VERSION ""

NS_ :

BS_:

BU_: ACCL BGW BLE DBPC DCFL DCFR DCRL DCRR DDP DSM ECPM FBCM FFL FLDC FRDC HLL HLR HUD IHUB LGL PBPC PDP PSM RBCM RCLL RCLR RLDC RLDP RLSM RRDC RRDP RRSM SCAM TOOL IPC u d t

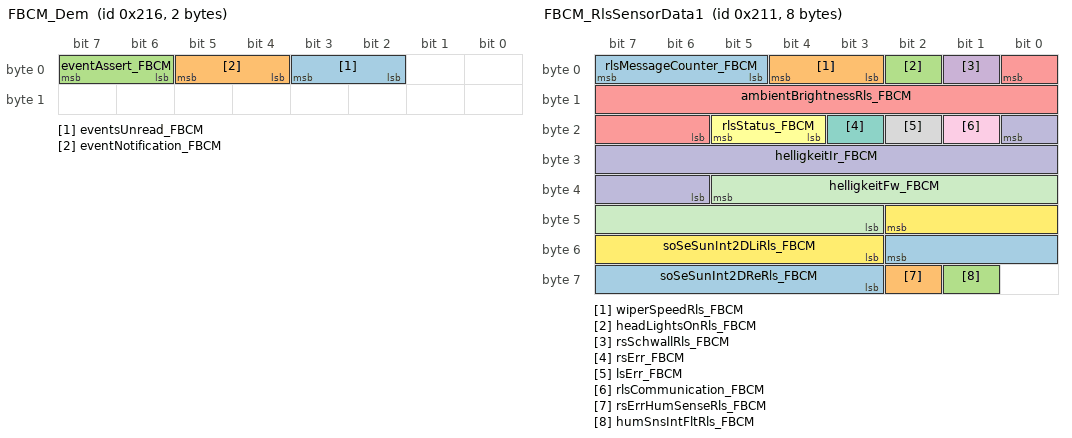
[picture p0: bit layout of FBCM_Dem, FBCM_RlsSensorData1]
BO_ 534 FBCM_Dem: 2 FBCM
 SG_ eventsUnread_FBCM : 3|2@0+ (1,0) [0|2] "" BGW,TOOL
 SG_ eventNotification_FBCM : 5|2@0+ (1,0) [0|2] "" TOOL
 SG_ eventAssert_FBCM : 7|2@0+ (1,0) [0|2] "" TOOL

BO_ 529 FBCM_RlsSensorData1: 8 FBCM
 SG_ rlsMessageCounter_FBCM : 7|3@0+ (1,0) [0|7] "" BGW
 SG_ wiperSpeedRls_FBCM : 4|2@0+ (1,0) [0|3] "" BGW
 SG_ headLightsOnRls_FBCM : 2|1@0+ (1,0) [0|1] "" BGW
 SG_ rsSchwallRls_FBCM : 1|1@0+ (1,0) [0|1] "" BGW
 SG_ ambientBrightnessRls_FBCM : 0|11@0+ (1,0) [0|2047] "" BGW
 SG_ rlsStatus_FBCM : 21|2@0+ (1,0) [0|3] "" BGW
 SG_ rsErr_FBCM : 19|1@0+ (1,0) [0|1] "" BGW
 SG_ lsErr_FBCM : 18|1@0+ (1,0) [0|1] "" BGW
 SG_ rlsCommunication_FBCM : 17|1@0+ (1,0) [0|1] "" BGW
 SG_ helligkeitIr_FBCM : 16|11@0+ (1,0) [0|2047] "" BGW
 SG_ helligkeitFw_FBCM : 37|11@0+ (1,0) [0|2047] "" BGW
 SG_ soSeSunInt2DLiRls_FBCM : 42|8@0+ (1,0) [0|255] "" BGW
 SG_ soSeSunInt2DReRls_FBCM : 50|8@0+ (1,0) [0|255] "" BGW
 SG_ rsErrHumSenseRls_FBCM : 58|1@0+ (1,0) [0|1] "" BGW
 SG_ humSnsIntFltRls_FBCM : 57|1@0+ (1,0) [0|1] "" BGW

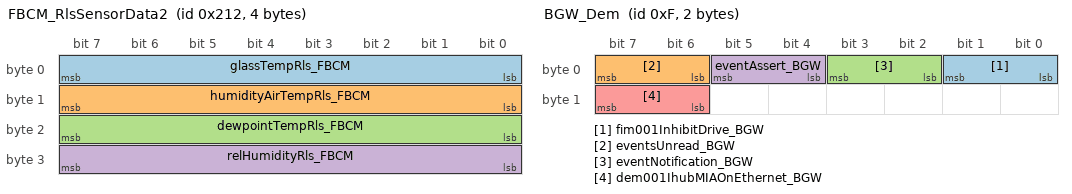
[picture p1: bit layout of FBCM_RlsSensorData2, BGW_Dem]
BO_ 530 FBCM_RlsSensorData2: 4 FBCM
 SG_ glassTempRls_FBCM : 7|8@0+ (1,0) [0|255] "" BGW
 SG_ humidityAirTempRls_FBCM : 15|8@0+ (1,0) [0|255] "" BGW
 SG_ dewpointTempRls_FBCM : 23|8@0+ (1,0) [0|255] "" BGW
 SG_ relHumidityRls_FBCM : 31|8@0+ (1,0) [0|255] "" BGW

BO_ 716 DCRR_IMU: 4 DCRR
 SG_ imuRollAngle_DCRR : 23|14@0- (0.022,0) [-180|180] "" BGW
 SG_ imuPitchAngle_DCRR : 7|14@0- (0.022,0) [-180|180] "" BGW

BO_ 684 DCRL_IMU: 4 DCRL
 SG_ imuRollAngle_DCRL : 23|14@0- (0.022,0) [-180|180] "" BGW
 SG_ imuPitchAngle_DCRL : 7|14@0- (0.022,0) [-180|180] "" BGW

BO_ 652 DCFR_IMU: 4 DCFR
 SG_ imuRollAngle_DCFR : 23|14@0- (0.022,0) [-180|180] "" BGW
 SG_ imuPitchAngle_DCFR : 7|14@0- (0.022,0) [-180|180] "" BGW

BO_ 612 DCFL_IMU: 4 DCFL
 SG_ imuRollAngle_DCFL : 23|14@0- (0.022,0) [-180|180] "" BGW
 SG_ imuPitchAngle_DCFL : 7|14@0- (0.022,0) [-180|180] "" BGW

BO_ 14 BGW_VehicleIdNumber: 8 BGW
 SG_ v : NaN|NaN@0+ (NaN,NaN) [NaN|NaN] "N" u

BO_ 15 BGW_Dem: 2 BGW
 SG_ fim001InhibitDrive_BGW : 1|2@0+ (1,0) [0|2] "" TOOL
 SG_ eventsUnread_BGW : 7|2@0+ (1,0) [0|2] "" TOOL
 SG_ eventNotification_BGW : 3|2@0+ (1,0) [0|2] "" TOOL
 SG_ eventAssert_BGW : 5|2@0+ (1,0) [0|2] "" TOOL
 SG_ dem001IhubMIAOnEthernet_BGW : 15|2@0+ (1,0) [0|2] "" TOOL

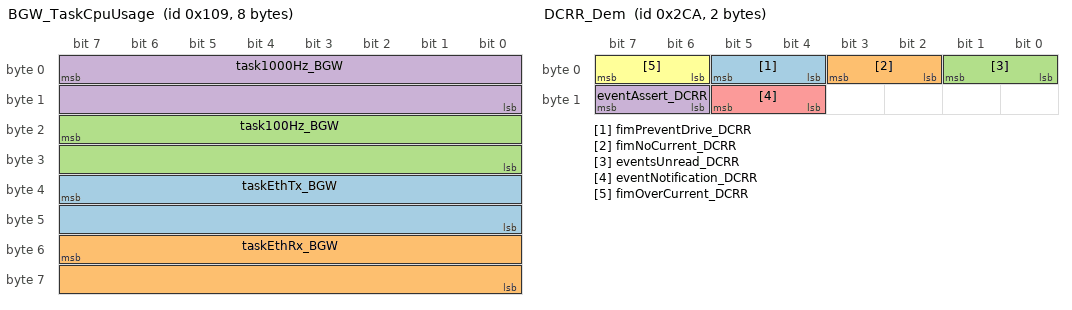
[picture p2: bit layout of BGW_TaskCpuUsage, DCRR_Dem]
BO_ 265 BGW_TaskCpuUsage: 8 BGW
 SG_ taskEthTx_BGW : 39|16@0+ (0.01,0) [0|100] "%" TOOL
 SG_ taskEthRx_BGW : 55|16@0+ (0.01,0) [0|100] "%" TOOL
 SG_ task100Hz_BGW : 23|16@0+ (0.01,0) [0|100] "%" TOOL
 SG_ task1000Hz_BGW : 7|16@0+ (0.01,0) [0|100] "%" TOOL

BO_ 269 BGW_InfoFromIHUB4: 8 BGW
 SG_ chargePortDoorOpenReq_IHUB : 61|2@0+ (1,0) [0|2] "" FBCM
 SG_ doorPassengerWindowLock_IHUB : 47|2@0+ (1,0) [0|2] "" DCRR,DCRL,DCFR,DCFL
 SG_ doorPanelRsdDisableRR_IHUB : 35|2@0+ (1,0) [0|2] "" RRDP
 SG_ doorPanelRsdDisableRL_IHUB : 37|2@0+ (1,0) [0|2] "" RLDP
 SG_ nAirConditionAutoRR_IHUB : 39|2@0+ (1,0) [0|2] "" RRDP
 SG_ nAirConditionAutoRL_IHUB : 41|2@0+ (1,0) [0|2] "" RLDP
 SG_ nAirConditionAutoFR_IHUB : 43|2@0+ (1,0) [0|2] "" PDP
 SG_ nAirConditionAutoFL_IHUB : 45|2@0+ (1,0) [0|2] "" DDP
 SG_ seatMemoryRR_IHUB : 27|2@0+ (1,0) [0|2] "" RRDP
 SG_ seatMemoryRL_IHUB : 29|2@0+ (1,0) [0|2] "" RLDP
 SG_ seatMemoryFL_IHUB : 31|2@0+ (1,0) [0|2] "" DDP
 SG_ seatMemoryFR_IHUB : 33|2@0+ (1,0) [0|2] "" PDP
 SG_ screenDisplayTempUnitsRRDP_IHUB : 25|2@0+ (1,0) [0|2] "" RRDP
 SG_ screenDisplayTempUnitsRLDP_IHUB : 17|2@0+ (1,0) [0|2] "" RLDP
 SG_ screenDisplayTempUnitsPDP_IHUB : 9|2@0+ (1,0) [0|2] "" PDP
 SG_ screenDisplayTempUnitsDDP_IHUB : 1|2@0+ (1,0) [0|2] "" DDP
 SG_ personalAssistantCmdRR_IHUB : 20|3@0+ (1,0) [0|6] "" RRDP
 SG_ personalAssistantCmdRL_IHUB : 23|3@0+ (1,0) [0|6] "" RLDP
 SG_ personalAssistantCmdFR_IHUB : 12|3@0+ (1,0) [0|6] "" PDP
 SG_ personalAssistantCmdFL_IHUB : 15|3@0+ (1,0) [0|6] "" DDP
 SG_ wirelessChargePadRR_IHUB : 4|3@0+ (1,0) [0|6] "" RRDP
 SG_ wirelessChargePadRL_IHUB : 7|3@0+ (1,0) [0|6] "" RLDP
 SG_ windowReqFrontLeft_IHUB : 55|2@0+ (1,0) [0|2] "" DCFL
 SG_ windowReqFrontRight_IHUB : 53|2@0+ (1,0) [0|2] "" DCFR
 SG_ windowReqRearLeft_IHUB : 51|2@0+ (1,0) [0|2] "" DCRL
 SG_ windowReqRearRight_IHUB : 49|2@0+ (1,0) [0|2] "" DCRR
 SG_ mirrorDimmingEnableDisable_IHUB : 63|2@0+ (1,0) [0|2] "" DCFL,DCFR
 SG_ lightHazardOnReq_IHUB : 59|2@0+ (1,0) [0|2] "" FBCM
 SG_ hornOnReq_IHUB : 57|2@0+ (1,0) [0|2] "" FBCM

BO_ 714 DCRR_Dem: 2 DCRR
 SG_ fimPreventDrive_DCRR : 5|2@0+ (1,0) [0|2] "" TOOL
 SG_ fimNoCurrent_DCRR : 3|2@0+ (1,0) [0|2] "" TOOL
 SG_ eventsUnread_DCRR : 1|2@0+ (1,0) [0|2] "" BGW,TOOL
 SG_ eventAssert_DCRR : 15|2@0+ (1,0) [0|2] "" TOOL
 SG_ eventNotification_DCRR : 13|2@0+ (1,0) [0|2] "" TOOL
 SG_ fimOverCurrent_DCRR : 7|2@0+ (1,0) [0|2] "" TOOL

BO_ 270 BGW_InfoFromIHUB3: 8 BGW
 SG_ deviceStateOfChargeFR_IHUB : 0|7@0+ (1,0) [0|100] "" PDP
 SG_ deviceStateOfChargeFL_IHUB : 7|7@0+ (1,0) [0|100] "" DDP
 SG_ deviceStateOfChargeRL_IHUB : 9|7@0+ (1,0) [0|100] "" RLDP
 SG_ deviceStateOfChargeRR_IHUB : 18|7@0+ (1,0) [0|100] "" RRDP
 SG_ deviceChargingFR_IHUB : 25|2@0+ (1,0) [0|2] "" PDP
 SG_ deviceChargingFL_IHUB : 27|2@0+ (1,0) [0|2] "" DDP
 SG_ deviceChargingRL_IHUB : 33|2@0+ (1,0) [0|2] "" RLDP
 SG_ deviceChargingRR_IHUB : 41|2@0+ (1,0) [0|2] "" RRDP
 SG_ deviceSignalStrengthRL_IHUB : 36|3@0+ (1,0) [0|5] "" RLDP
 SG_ deviceSignalStrengthFR_IHUB : 39|3@0+ (1,0) [0|5] "" PDP
 SG_ deviceSignalStrengthFL_IHUB : 44|3@0+ (1,0) [0|5] "" DDP
 SG_ deviceSignalStrengthRR_IHUB : 47|3@0+ (1,0) [0|5] "" RRDP
 SG_ doorPanelDisableRR_IHUB : 49|2@0+ (1,0) [0|2] "" RRDP
 SG_ doorPanelDisableRL_IHUB : 51|2@0+ (1,0) [0|2] "" RLDP
 SG_ doorPanelDisableFR_IHUB : 53|2@0+ (1,0) [0|2] "" PDP
 SG_ doorPanelDisableFL_IHUB : 55|2@0+ (1,0) [0|2] "" DDP
 SG_ doorPanelSeatsDisableRR_IHUB : 57|2@0+ (1,0) [0|2] "" RRDP
 SG_ doorPanelSeatsDisableRL_IHUB : 59|2@0+ (1,0) [0|2] "" RLDP
 SG_ doorPanelSeatsDisableFR_IHUB : 61|2@0+ (1,0) [0|2] "" PDP
 SG_ doorPanelSeatsDisableFL_IHUB : 63|2@0+ (1,0) [0|2] "" DDP

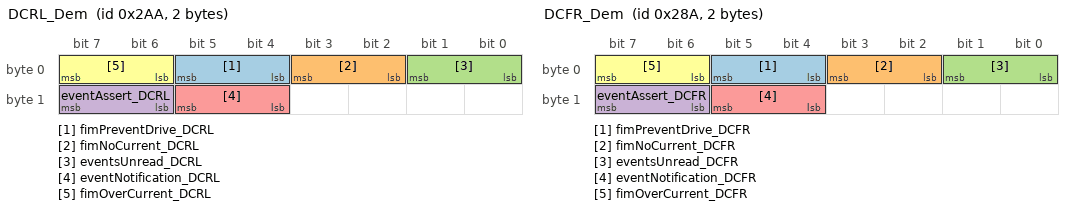
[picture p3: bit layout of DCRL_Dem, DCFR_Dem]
BO_ 682 DCRL_Dem: 2 DCRL
 SG_ fimPreventDrive_DCRL : 5|2@0+ (1,0) [0|2] "" TOOL
 SG_ fimNoCurrent_DCRL : 3|2@0+ (1,0) [0|2] "" TOOL
 SG_ eventsUnread_DCRL : 1|2@0+ (1,0) [0|2] "" BGW,TOOL
 SG_ eventAssert_DCRL : 15|2@0+ (1,0) [0|2] "" TOOL
 SG_ eventNotification_DCRL : 13|2@0+ (1,0) [0|2] "" TOOL
 SG_ fimOverCurrent_DCRL : 7|2@0+ (1,0) [0|2] "" TOOL

BO_ 650 DCFR_Dem: 2 DCFR
 SG_ fimPreventDrive_DCFR : 5|2@0+ (1,0) [0|2] "" TOOL
 SG_ fimNoCurrent_DCFR : 3|2@0+ (1,0) [0|2] "" TOOL
 SG_ eventsUnread_DCFR : 1|2@0+ (1,0) [0|2] "" BGW,TOOL
 SG_ eventAssert_DCFR : 15|2@0+ (1,0) [0|2] "" TOOL
 SG_ eventNotification_DCFR : 13|2@0+ (1,0) [0|2] "" TOOL
 SG_ fimOverCurrent_DCFR : 7|2@0+ (1,0) [0|2] "" TOOL

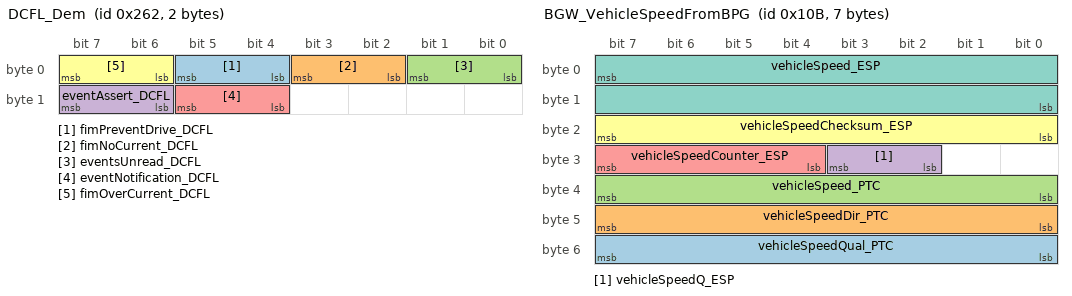
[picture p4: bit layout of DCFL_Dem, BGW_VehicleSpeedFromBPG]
BO_ 610 DCFL_Dem: 2 DCFL
 SG_ fimPreventDrive_DCFL : 5|2@0+ (1,0) [0|2] "" TOOL
 SG_ fimNoCurrent_DCFL : 3|2@0+ (1,0) [0|2] "" TOOL
 SG_ eventsUnread_DCFL : 1|2@0+ (1,0) [0|2] "" BGW,TOOL
 SG_ eventAssert_DCFL : 15|2@0+ (1,0) [0|2] "" TOOL
 SG_ eventNotification_DCFL : 13|2@0+ (1,0) [0|2] "" TOOL
 SG_ fimOverCurrent_DCFL : 7|2@0+ (1,0) [0|2] "" TOOL

BO_ 266 BGW_LightingCmdAes: 5 BGW
 SG_ extBrightness_IHUB : 7|4@0+ (0.07,0) [0|0.98] "%" ECPM,RRDC,RLDC,FRDC,FLDC,FFL
 SG_ extSequenceId_IHUB : 15|8@0+ (1,0) [0|254] "" RRDC,RLDC,FRDC,FLDC,FFL,HLL,HLR,ACCL,LGL,RCLR,RCLL
 SG_ extGlobalLightingCounter_IHUB : 23|8@0+ (1,0) [0|254] "" FBCM,FRDC,RRDC,FLDC,RLDC,FFL,HLL,HLR,ACCL,LGL,RCLR,RCLL

BO_ 267 BGW_VehicleSpeedFromBPG: 7 BGW
 SG_ vehicleSpeedQual_PTC : 55|8@0+ (1,0) [0|254] "" DCFL,DCFR,DCRL,DCRR
 SG_ vehicleSpeedDir_PTC : 47|8@0+ (1,0) [0|254] "" DCFL,DCFR,DCRL,DCRR
 SG_ vehicleSpeed_PTC : 39|8@0+ (1,0) [0|254] "" DCFL,DCFR,DCRL,DCRR
 SG_ vehicleSpeedQ_ESP : 27|2@0+ (1,0) [0|3] "" DCFL,DCFR,DCRL,DCRR
 SG_ vehicleSpeedCounter_ESP : 31|4@0+ (1,0) [0|15] "" DCFL,DCFR,DCRL,DCRR
 SG_ vehicleSpeedChecksum_ESP : 23|8@0+ (1,0) [0|255] "" DCFL,DCFR,DCRL,DCRR
 SG_ vehicleSpeed_ESP : 7|16@0+ (0.01,0) [0|655.34] "km/h" ECPM,FBCM,RBCM,DCFL,DCFR,DCRL,DCRR

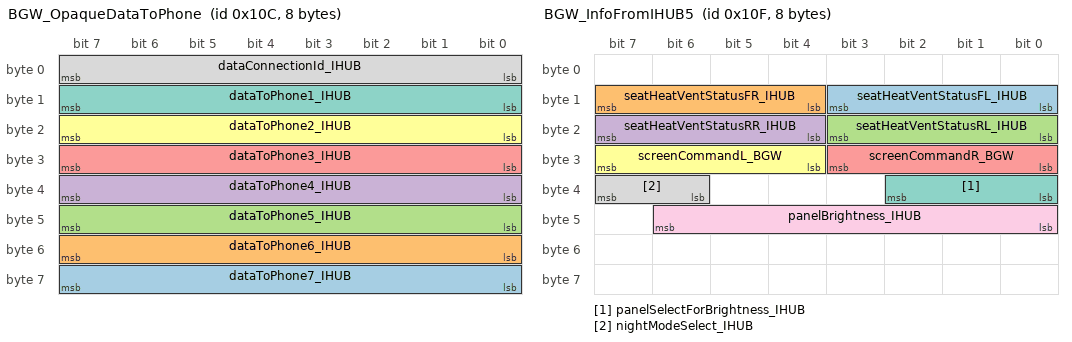
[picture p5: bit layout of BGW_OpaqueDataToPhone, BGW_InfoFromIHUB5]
BO_ 268 BGW_OpaqueDataToPhone: 8 BGW
 SG_ dataToPhone7_IHUB : 63|8@0+ (1,0) [0|254] "" BLE
 SG_ dataToPhone6_IHUB : 55|8@0+ (1,0) [0|254] "" BLE
 SG_ dataToPhone5_IHUB : 47|8@0+ (1,0) [0|254] "" BLE
 SG_ dataToPhone4_IHUB : 39|8@0+ (1,0) [0|254] "" BLE
 SG_ dataToPhone3_IHUB : 31|8@0+ (1,0) [0|254] "" BLE
 SG_ dataToPhone2_IHUB : 23|8@0+ (1,0) [0|254] "" BLE
 SG_ dataToPhone1_IHUB : 15|8@0+ (1,0) [0|254] "" BLE
 SG_ dataConnectionId_IHUB : 7|8@0+ (1,0) [0|254] "" BLE

BO_ 271 BGW_InfoFromIHUB5: 8 BGW
 SG_ seatHeatVentStatusFL_IHUB : 11|4@0+ (1,0) [0|8] "" DDP
 SG_ seatHeatVentStatusFR_IHUB : 15|4@0+ (1,0) [0|8] "" PDP
 SG_ seatHeatVentStatusRL_IHUB : 19|4@0+ (1,0) [0|8] "" RLDP
 SG_ seatHeatVentStatusRR_IHUB : 23|4@0+ (1,0) [0|8] "" RRDP
 SG_ screenCommandR_BGW : 27|4@0+ (1,0) [0|10] "" DBPC
 SG_ screenCommandL_BGW : 31|4@0+ (1,0) [0|10] "" PBPC
 SG_ panelSelectForBrightness_IHUB : 34|3@0+ (1,0) [0|6] "" PBPC,DBPC,DDP,PDP,RLDP,RRDP
 SG_ nightModeSelect_IHUB : 39|2@0+ (1,0) [0|1] "" ECPM,PBPC,DBPC,DDP,PDP,RLDP,RRDP
 SG_ panelBrightness_IHUB : 46|7@0+ (1,0) [0|100] "" ECPM,PBPC,DBPC,DDP,PDP,RLDP,RRDP

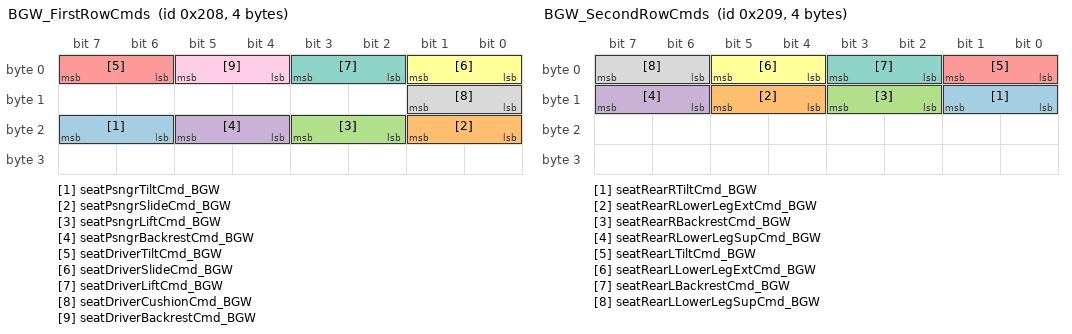
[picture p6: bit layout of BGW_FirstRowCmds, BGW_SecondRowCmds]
BO_ 520 BGW_FirstRowCmds: 4 BGW
 SG_ seatPsngrTiltCmd_BGW : 23|2@0+ (1,0) [0|2] "" PSM
 SG_ seatPsngrSlideCmd_BGW : 17|2@0+ (1,0) [0|2] "" PSM
 SG_ seatPsngrLiftCmd_BGW : 19|2@0+ (1,0) [0|2] "" PSM
 SG_ seatPsngrBackrestCmd_BGW : 21|2@0+ (1,0) [0|2] "" PSM
 SG_ seatDriverTiltCmd_BGW : 7|2@0+ (1,0) [0|2] "" DSM
 SG_ seatDriverSlideCmd_BGW : 1|2@0+ (1,0) [0|2] "" DSM
 SG_ seatDriverLiftCmd_BGW : 3|2@0+ (1,0) [0|2] "" DSM
 SG_ seatDriverCushionCmd_BGW : 9|2@0+ (1,0) [0|2] "" DSM
 SG_ seatDriverBackrestCmd_BGW : 5|2@0+ (1,0) [0|2] "" DSM

BO_ 521 BGW_SecondRowCmds: 4 BGW
 SG_ seatRearRTiltCmd_BGW : 9|2@0+ (1,0) [0|2] "" RRSM
 SG_ seatRearRLowerLegExtCmd_BGW : 13|2@0+ (1,0) [0|2] "" RRSM
 SG_ seatRearRBackrestCmd_BGW : 11|2@0+ (1,0) [0|2] "" RRSM
 SG_ seatRearRLowerLegSupCmd_BGW : 15|2@0+ (1,0) [0|2] "" RRSM
 SG_ seatRearLTiltCmd_BGW : 1|2@0+ (1,0) [0|2] "" RLSM
 SG_ seatRearLLowerLegExtCmd_BGW : 5|2@0+ (1,0) [0|2] "" RLSM
 SG_ seatRearLBackrestCmd_BGW : 3|2@0+ (1,0) [0|2] "" RLSM
 SG_ seatRearLLowerLegSupCmd_BGW : 7|2@0+ (1,0) [0|2] "" RLSM

BO_ 522 BGW_DSMMassageCtrl: 8 BGW
 SG_ seatMassgReqOnOffDSM_BGW : 40|1@0+ (1,0) [0|1] "" DSM
 SG_ seatMassgReqMassgSpdLvlDSM_BGW : 55|2@0+ (1,0) [0|1] "" DSM
 SG_ seatMassgReqMassgProgDSM_BGW : 45|4@0+ (1,0) [0|1] "" DSM
 SG_ seatMassgReqMassgIntenDSM_BGW : 52|2@0+ (1,0) [0|1] "" DSM
 SG_ seatEngPAmbAir1DSM_BGW : 39|8@0+ (5,0) [0|255] "hPa" DSM
 SG_ seatIndVlvCtrlDSM_BGW : 26|1@0+ (1,0) [0|1] "" DSM
 SG_ seatPmpRunDSM_BGW : 25|1@0+ (1,0) [0|1] "" DSM
 SG_ seatShIncDSM_BGW : 23|1@0+ (1,0) [0|1] "" DSM
 SG_ seatShDecDSM_BGW : 24|1@0+ (1,0) [0|1] "" DSM
 SG_ seatCushIncDSM_BGW : 21|1@0+ (1,0) [0|1] "" DSM
 SG_ seatCushDecDSM_BGW : 22|1@0+ (1,0) [0|1] "" DSM
 SG_ seatBackSaveSetToMemDSM_BGW : 20|2@0+ (1,0) [0|1] "" DSM
 SG_ seatBackCtrReqInOutEasyDSM_BGW : 18|1@0+ (1,0) [0|1] "" DSM
 SG_ seatDiAutCorrnDSM_BGW : 17|1@0+ (1,0) [0|1] "" DSM
 SG_ seatEmgyStopDSM_BGW : 16|1@0+ (1,0) [0|1] "" DSM
 SG_ seatBackPosnStoreDSM_BGW : 15|1@0+ (1,0) [0|1] "" DSM
 SG_ seatBackPosnRestoreDSM_BGW : 14|1@0+ (1,0) [0|1] "" DSM
 SG_ seatMemSeatCtrlDSM_BGW : 13|2@0+ (1,0) [0|1] "" DSM
 SG_ seatProfPenDSM_BGW : 11|4@0+ (1,0) [0|14] "" DSM
 SG_ seatLumIncDSM_BGW : 7|1@0+ (1,0) [0|1] "" DSM
 SG_ seatLumDecDSM_BGW : 6|1@0+ (1,0) [0|1] "" DSM
 SG_ seatLumUpDSM_BGW : 5|1@0+ (1,0) [0|1] "" DSM
 SG_ seatLumDwnDSM_BGW : 4|1@0+ (1,0) [0|1] "" DSM
 SG_ seatBackBlstrDecDSM_BGW : 3|1@0+ (1,0) [0|1] "" DSM
 SG_ seatBackBlstrIncDSM_BGW : 2|1@0+ (1,0) [0|1] "" DSM

BO_ 523 BGW_PSMMassageCtrl: 8 BGW
 SG_ seatEngPAmbAir1PSM_BGW : 39|8@0+ (5,0) [0|254] "hPa" PSM
 SG_ seatShIncPSM_BGW : 23|1@0+ (1,0) [0|1] "" PSM
 SG_ seatShDecPSM_BGW : 24|1@0+ (1,0) [0|1] "" PSM
 SG_ seatLumUpPSM_BGW : 5|1@0+ (1,0) [0|1] "" PSM
 SG_ seatLumIncPSM_BGW : 7|1@0+ (1,0) [0|1] "" PSM
 SG_ seatLumDwnPSM_BGW : 4|1@0+ (1,0) [0|1] "" PSM
 SG_ seatLumDecPSM_BGW : 6|1@0+ (1,0) [0|1] "" PSM
 SG_ seatCushIncPSM_BGW : 21|1@0+ (1,0) [0|1] "" PSM
 SG_ seatCushDecPSM_BGW : 22|1@0+ (1,0) [0|1] "" PSM
 SG_ seatBackSaveSetToMemPSM_BGW : 20|2@0+ (1,0) [0|2] "" PSM
 SG_ seatBackPosnStorePSM_BGW : 15|1@0+ (1,0) [0|1] "" PSM
 SG_ seatBackPosnRestorePSM_BGW : 14|1@0+ (1,0) [0|1] "" PSM
 SG_ seatBackCtrReqInOutEasyPSM_BGW : 18|1@0+ (1,0) [0|1] "" PSM
 SG_ seatBackBlstrIncPSM_BGW : 2|1@0+ (1,0) [0|1] "" PSM
 SG_ seatProfPenPSM_BGW : 11|4@0+ (1,0) [0|14] "" PSM
 SG_ seatPmpRunPSM_BGW : 25|1@0+ (1,0) [0|1] "" PSM
 SG_ seatMemSeatCtrlPSM_BGW : 13|2@0+ (1,0) [0|3] "" PSM
 SG_ seatMassgReqOnOffPSM_BGW : 40|1@0+ (1,0) [0|1] "" PSM
 SG_ seatMassgReqMassgSpdLvlPSM_BGW : 55|2@0+ (1,0) [0|2] "" PSM
 SG_ seatMassgReqMassgProgPSM_BGW : 45|4@0+ (1,0) [0|15] "" PSM
 SG_ seatMassgReqMassgIntenPSM_BGW : 52|2@0+ (1,0) [0|2] "" PSM
 SG_ seatIndVlvCtrlPSM_BGW : 26|1@0+ (1,0) [0|1] "" PSM
 SG_ seatEmgyStopPSM_BGW : 16|1@0+ (1,0) [0|1] "" PSM
 SG_ seatDiAutCorrnPSM_BGW : 17|1@0+ (1,0) [0|1] "" PSM
 SG_ seatBackBlstrDecPSM_BGW : 3|1@0+ (1,0) [0|1] "" PSM

BO_ 524 BGW_SecondRowCmdsV2: 4 BGW
 SG_ seatRearRBackrestCmdV2_BGW : 11|2@0+ (1,0) [0|2] "" RRSM
 SG_ seatRearLBackrestCmdV2_BGW : 3|2@0+ (1,0) [0|2] "" RLSM

BO_ 525 BGW_UserInfo: 2 BGW
 SG_ userID_IHUB : 7|8@0+ (1,0) [0|16] "" FBCM,PBPC,DBPC
 SG_ userLocation_IHUB : 15|8@0+ (1,0) [0|30] "" FBCM,PBPC,DBPC

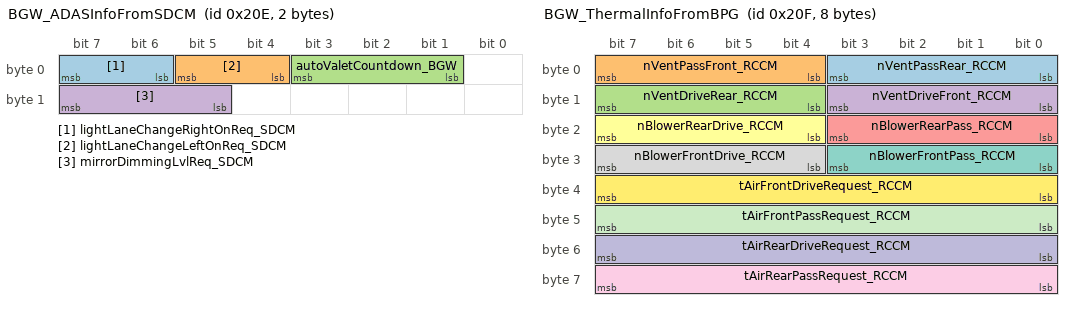
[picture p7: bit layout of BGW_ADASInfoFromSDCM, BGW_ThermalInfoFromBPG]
BO_ 526 BGW_ADASInfoFromSDCM: 2 BGW
 SG_ lightLaneChangeRightOnReq_SDCM : 7|2@0+ (1,0) [0|2] "" FBCM
 SG_ lightLaneChangeLeftOnReq_SDCM : 5|2@0+ (1,0) [0|2] "" FBCM
 SG_ autoValetCountdown_BGW : 3|3@0+ (1,0) [0|3] "" DBPC,PBPC
 SG_ mirrorDimmingLvlReq_SDCM : 15|3@0+ (1,0) [0|6] "" DCFL,DCFR

BO_ 527 BGW_ThermalInfoFromBPG: 8 BGW
 SG_ nVentPassRear_RCCM : 3|4@0+ (1,0) [0|12] "" RRDP
 SG_ nVentPassFront_RCCM : 7|4@0+ (1,0) [0|12] "" PDP
 SG_ nVentDriveRear_RCCM : 15|4@0+ (1,0) [0|12] "" RLDP
 SG_ nVentDriveFront_RCCM : 11|4@0+ (1,0) [0|12] "" DDP
 SG_ nBlowerRearPass_RCCM : 19|4@0+ (1,0) [0|14] "" RRDP
 SG_ nBlowerRearDrive_RCCM : 23|4@0+ (1,0) [0|14] "" RLDP
 SG_ nBlowerFrontPass_RCCM : 27|4@0+ (1,0) [0|14] "" PDP
 SG_ nBlowerFrontDrive_RCCM : 31|4@0+ (1,0) [0|14] "" DDP
 SG_ tAirRearPassRequest_RCCM : 63|8@0+ (0.1,15.5) [15.5|32.5] "C" RRDP
 SG_ tAirRearDriveRequest_RCCM : 55|8@0+ (0.1,15.5) [15.5|32.5] "C" RLDP
 SG_ tAirFrontPassRequest_RCCM : 47|8@0+ (0.1,15.5) [15.5|32.5] "C" PDP
 SG_ tAirFrontDriveRequest_RCCM : 39|8@0+ (0.1,15.5) [15.5|32.5] "C" DDP

BO_ 568 SCAM_Status: 6 SCAM
 SG_ stspTe_SCAM : 41|2@0+ (1,0) [0|2] "" BGW
 SG_ stspTi_SCAM : 43|2@0+ (1,0) [0|2] "" BGW
 SG_ plsHTe_SCAM : 45|2@0+ (1,0) [0|2] "" BGW
 SG_ shcHTe_SCAM : 47|2@0+ (1,0) [0|2] "" BGW
 SG_ drpHTe_SCAM : 33|2@0+ (1,0) [0|2] "" BGW
 SG_ schMTe_SCAM : 35|2@0+ (1,0) [0|2] "" BGW
 SG_ drpMTe_SCAM : 37|2@0+ (1,0) [0|2] "" BGW
 SG_ ovcTe_SCAM : 39|2@0+ (1,0) [0|2] "" BGW
 SG_ hiTmpTe_SCAM : 25|2@0+ (1,0) [0|2] "" BGW
 SG_ stallTe_SCAM : 27|2@0+ (1,0) [0|2] "" BGW
 SG_ plsHTi_SCAM : 29|2@0+ (1,0) [0|2] "" BGW
 SG_ shcHTi_SCAM : 31|2@0+ (1,0) [0|2] "" BGW
 SG_ drpHTi_SCAM : 17|2@0+ (1,0) [0|2] "" BGW
 SG_ shcMTi_SCAM : 19|2@0+ (1,0) [0|2] "" BGW
 SG_ drpMTi_SCAM : 21|2@0+ (1,0) [0|2] "" BGW
 SG_ ovcTi_SCAM : 23|2@0+ (1,0) [0|2] "" BGW
 SG_ hiTmpTi_SCAM : 9|2@0+ (1,0) [0|2] "" BGW
 SG_ stallTi_SCAM : 11|2@0+ (1,0) [0|2] "" BGW
 SG_ maxBlNum_SCAM : 13|2@0+ (1,0) [0|2] "" BGW
 SG_ overVolt_SCAM : 15|2@0+ (1,0) [0|2] "" BGW
 SG_ lowVolt_SCAM : 1|2@0+ (1,0) [0|2] "" BGW
 SG_ underVolt_SCAM : 3|2@0+ (1,0) [0|2] "" BGW
 SG_ comErr_SCAM : 5|2@0+ (1,0) [0|2] "" BGW
 SG_ intErr_SCAM : 7|2@0+ (1,0) [0|2] "" BGW

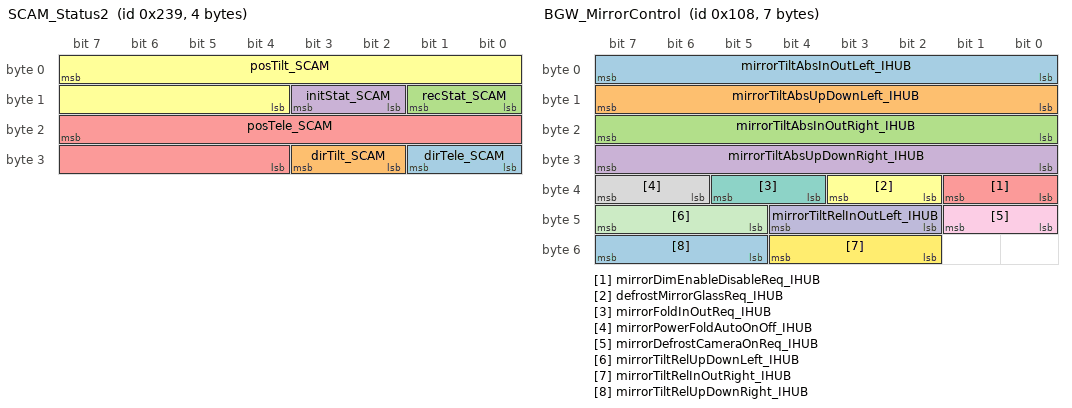
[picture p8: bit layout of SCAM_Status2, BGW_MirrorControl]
BO_ 569 SCAM_Status2: 4 SCAM
 SG_ dirTele_SCAM : 25|2@0+ (1,0) [0|2] "" BGW
 SG_ dirTilt_SCAM : 27|2@0+ (1,0) [0|2] "" BGW
 SG_ recStat_SCAM : 9|2@0+ (1,0) [0|2] "" BGW
 SG_ initStat_SCAM : 11|2@0+ (1,0) [0|2] "" BGW
 SG_ posTele_SCAM : 23|12@0+ (1,0) [0|4094] "" BGW
 SG_ posTilt_SCAM : 7|12@0+ (1,0) [0|4094] "" BGW

BO_ 608 DCFL_Status: 5 DCFL
 SG_ windowLockState_DCFL : 21|2@0+ (1,0) [0|2] "" BGW,DCFL,DCFR,DCRL,DCRR
 SG_ doorIsUnlatched_DCFL : 31|2@0+ (1,0) [0|2] "" FBCM,BGW,DCFR,DCRR,DCRL,IHUB
 SG_ doorExtSwitch_DCFL : 9|2@0+ (1,0) [0|2] "" BGW
 SG_ doorLockReq_DCFL : 23|2@0+ (1,0) [0|2] "" BGW
 SG_ doorMirrorState_DCFL : 7|3@0+ (1,0) [0|6] "" ECPM,BGW
 SG_ doorState_DCFL : 13|4@0+ (1,0) [0|6] "" ECPM,RBCM,FBCM,BGW
 SG_ mirrorHeaterState_DCFL : 15|2@0+ (1,0) [0|2] "" ECPM,BGW
 SG_ sideRepeaterState_DCFL : 2|2@0+ (1,0) [0|2] "" BGW,RBCM
 SG_ doorDTCPresent_DCFL : 4|2@0+ (1,0) [0|2] "" BGW
 SG_ windowStatusFl_DCFL : 19|3@0+ (1,0) [0|6] "" BGW
 SG_ mirrorFoldFeedbackLeft_DCFL : 29|2@0+ (1,0) [0|2] "" BGW
 SG_ mirrorDefrostGlassStatusLh_DCFL : 27|2@0+ (1,0) [0|2] "" BGW
 SG_ mirrorStatusMovUpDownLeft_DCFL : 39|2@0+ (1,0) [0|2] "" BGW
 SG_ mirrorStatusMovInOutLeft_DCFL : 37|2@0+ (1,0) [0|2] "" BGW
 SG_ mirrorDefrostCamStatusLeft_DCFL : 35|2@0+ (1,0) [0|2] "" BGW
 SG_ mirrorFoldAutoStatusLeft_DCFL : 25|2@0+ (1,0) [0|2] "" BGW
 SG_ mirrorDimEnabDisableStatus_DCFL : 33|2@0+ (1,0) [0|2] "" BGW

BO_ 609 DCFL_Switch: 4 DCFL
 SG_ mirrorRight_DCFL : 16|1@0+ (1,0) [0|1] "" DCRR,DCRL,DCFR,DCFL,TOOL
 SG_ mirrorLeft_DCFL : 17|1@0+ (1,0) [0|1] "" DCRR,DCRL,DCFR,DCFL,TOOL
 SG_ mirrorDown_DCFL : 18|1@0+ (1,0) [0|1] "" DCRR,DCRL,DCFR,DCFL,TOOL
 SG_ windowLock_DCFL : 20|1@0+ (1,0) [0|1] "" DCRR,DCRL,DCFR,DCFL,TOOL
 SG_ leftMirrorSel_DCFL : 21|1@0+ (1,0) [0|1] "" DCRR,DCRL,DCFR,DCFL,TOOL
 SG_ rightMirrorSel_DCFL : 22|1@0+ (1,0) [0|1] "" DCRR,DCRL,DCFR,DCFL,TOOL
 SG_ windowReqRearLeft_DCFL : 10|3@0+ (1,0) [0|6] "" DCRR,DCFR,DCFL,DCRL
 SG_ windowReqRearRight_DCFL : 13|3@0+ (1,0) [0|6] "" DCRL,DCFR,DCFL,DCRR
 SG_ nothingPressed_DCFL : 14|1@0+ (1,0) [0|1] "" DCRR,DCRL,DCFR,DCFL,TOOL
 SG_ buttonPressed_DCFL : 15|1@0+ (1,0) [0|1] "" DCRR,DCRL,DCFR,DCFL,TOOL
 SG_ windowReqFrontLeft_DCFL : 3|3@0+ (1,0) [0|6] "" DCRR,DCRL,DCFR,DCFL,BGW
 SG_ windowReqFrontRight_DCFL : 6|3@0+ (1,0) [0|6] "" DCRR,DCRL,DCFR,DCFL,BGW
 SG_ mirrorUp_DCFL : 7|1@0+ (1,0) [0|1] "" DCRR,DCRL,DCFR,DCFL,TOOL
 SG_ doorMirrorFoldCmd_DCFL : 27|2@0+ (1,0) [0|2] "" DCRR,DCRL,DCFL,BGW,DCFR
 SG_ doorExtDriverRearRelease_DCFL : 25|2@0+ (1,0) [0|2] "" DCRR,DCRL,DCFR,DCFL,BGW,FBCM
 SG_ doorIntDriverRearRelease_DCFL : 31|2@0+ (1,0) [0|2] "" DCRR,DCRL,DCFR,DCFL,BGW,FBCM
 SG_ doorDriverFrontPresentReq_DCFL : 29|2@0+ (1,0) [0|2] "" DCRR,DCRL,DCFR,DCFL,BGW,FBCM

BO_ 611 DCFL_MirrorPosition: 3 DCFL
 SG_ mirrorStatusPosUpDownLh_DCFL : 11|12@0- (0.00391,0) [-8|8] "" BGW
 SG_ mirrorStatusPosInOutLh_DCFL : 7|12@0- (0.005374,0) [-11|11] "" BGW

BO_ 264 BGW_MirrorControl: 7 BGW
 SG_ mirrorTiltAbsInOutLeft_IHUB : 7|8@0+ (0.1,-11) [-11|11] "" DCFR,DCFL
 SG_ mirrorTiltAbsUpDownLeft_IHUB : 15|8@0+ (0.1,-8) [-8|8] "" DCFR,DCFL
 SG_ mirrorTiltAbsInOutRight_IHUB : 23|8@0+ (0.1,-11) [-11|11] "" DCFL,DCFR
 SG_ mirrorTiltAbsUpDownRight_IHUB : 31|8@0+ (0.1,-8) [-8|8] "" DCFR,DCFL
 SG_ mirrorDimEnableDisableReq_IHUB : 33|2@0+ (1,0) [0|2] "" DCFL,DCFR
 SG_ defrostMirrorGlassReq_IHUB : 35|2@0+ (1,0) [0|2] "" DCFL,DCFR
 SG_ mirrorFoldInOutReq_IHUB : 37|2@0+ (1,0) [0|2] "" DCFR,DCFL
 SG_ mirrorPowerFoldAutoOnOff_IHUB : 39|2@0+ (1,0) [0|2] "" DCFL,DCFR
 SG_ mirrorDefrostCameraOnReq_IHUB : 41|2@0+ (1,0) [0|2] "" DCFL,DCFR
 SG_ mirrorTiltRelInOutLeft_IHUB : 44|3@0+ (1,0) [0|6] "" DCFL
 SG_ mirrorTiltRelUpDownLeft_IHUB : 47|3@0+ (1,0) [0|6] "" DCFL
 SG_ mirrorTiltRelInOutRight_IHUB : 52|3@0+ (1,0) [0|6] "" DCFL,DCFR
 SG_ mirrorTiltRelUpDownRight_IHUB : 55|3@0+ (1,0) [0|6] "" DCFL,DCFR

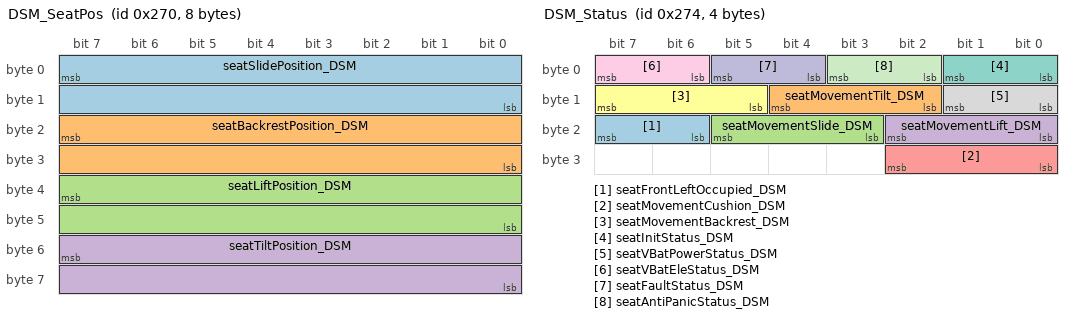
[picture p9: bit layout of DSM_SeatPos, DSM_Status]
BO_ 624 DSM_SeatPos: 8 DSM
 SG_ seatSlidePosition_DSM : 7|16@0- (1,0) [-32768|32766] "" BGW
 SG_ seatBackrestPosition_DSM : 23|16@0- (1,0) [-32768|32766] "" BGW
 SG_ seatLiftPosition_DSM : 39|16@0- (1,0) [-32768|32766] "" BGW
 SG_ seatTiltPosition_DSM : 55|16@0- (1,0) [-32768|32766] "" BGW

BO_ 625 DSM_CushionPos: 2 DSM
 SG_ seatCushionPosition_DSM : 7|16@0- (1,0) [-32768|32766] "" BGW

BO_ 628 DSM_Status: 4 DSM
 SG_ seatFrontLeftOccupied_DSM : 23|2@0+ (1,0) [0|1] "" FBCM,DCFL,BGW,IHUB
 SG_ seatMovementTilt_DSM : 12|3@0+ (1,0) [0|3] "" BGW
 SG_ seatMovementSlide_DSM : 21|3@0+ (1,0) [0|3] "" BGW
 SG_ seatMovementLift_DSM : 18|3@0+ (1,0) [0|3] "" BGW
 SG_ seatMovementCushion_DSM : 26|3@0+ (1,0) [0|3] "" BGW
 SG_ seatMovementBackrest_DSM : 15|3@0+ (1,0) [0|3] "" BGW
 SG_ seatInitStatus_DSM : 1|2@0+ (1,0) [0|2] "" BGW
 SG_ seatVBatPowerStatus_DSM : 9|2@0+ (1,0) [0|1] "" BGW
 SG_ seatVBatEleStatus_DSM : 7|2@0+ (1,0) [0|1] "" BGW
 SG_ seatFaultStatus_DSM : 5|2@0+ (1,0) [0|2] "" BGW
 SG_ seatAntiPanicStatus_DSM : 3|2@0+ (1,0) [0|2] "" BGW

BO_ 648 DCFR_Status: 5 DCFR
 SG_ windowLockState_DCFR : 21|2@0+ (1,0) [0|2] "" DCFL,DCFR,DCRL,DCRR,BGW
 SG_ doorIsUnlatched_DCFR : 31|2@0+ (1,0) [0|2] "" FBCM,BGW,DCFL,DCRR,DCRL,IHUB
 SG_ doorExtSwitch_DCFR : 9|2@0+ (1,0) [0|2] "" BGW
 SG_ doorLockReq_DCFR : 23|2@0+ (1,0) [0|2] "" BGW
 SG_ doorMirrorState_DCFR : 7|3@0+ (1,0) [0|6] "" ECPM,BGW
 SG_ doorState_DCFR : 13|4@0+ (1,0) [0|6] "" ECPM,RBCM,FBCM,BGW
 SG_ mirrorHeaterState_DCFR : 15|2@0+ (1,0) [0|2] "" ECPM,BGW
 SG_ sideRepeaterState_DCFR : 2|2@0+ (1,0) [0|2] "" BGW,RBCM
 SG_ doorDTCPresent_DCFR : 4|2@0+ (1,0) [0|2] "" BGW
 SG_ windowStatusFr_DCFR : 19|3@0+ (1,0) [0|6] "" BGW
 SG_ mirrorFoldFeedbackRight_DCFR : 29|2@0+ (1,0) [0|2] "" BGW
 SG_ mirrorDefrostGlassStatusRh_DCFR : 27|2@0+ (1,0) [0|2] "" BGW
 SG_ mirrorStatusMovUpDownRight_DCFR : 39|2@0+ (1,0) [0|2] "" BGW
 SG_ mirrorStatusMovInOutRight_DCFR : 37|2@0+ (1,0) [0|2] "" BGW
 SG_ mirrorDefrostCamStatusRight_DCFR : 35|2@0+ (1,0) [0|2] "" BGW
 SG_ mirrorFoldAutoStatusRight_DCFR : 25|2@0+ (1,0) [0|2] "" BGW
 SG_ mirrorDimEnabDisableStatus_DCFR : 33|2@0+ (1,0) [0|2] "" BGW

BO_ 649 DCFR_Switch: 4 DCFR
 SG_ mirrorRight_DCFR : 16|1@0+ (1,0) [0|1] "" DCRR,DCRL,DCFR,DCFL,TOOL
 SG_ mirrorLeft_DCFR : 17|1@0+ (1,0) [0|1] "" DCRR,DCRL,DCFR,DCFL,TOOL
 SG_ mirrorDown_DCFR : 18|1@0+ (1,0) [0|1] "" DCRR,DCRL,DCFR,DCFL,TOOL
 SG_ windowLock_DCFR : 20|1@0+ (1,0) [0|1] "" DCRR,DCRL,DCFR,DCFL,TOOL
 SG_ leftMirrorSel_DCFR : 21|1@0+ (1,0) [0|1] "" DCRR,DCRL,DCFR,DCFL,TOOL
 SG_ rightMirrorSel_DCFR : 22|1@0+ (1,0) [0|1] "" DCRR,DCRL,DCFR,DCFL,TOOL
 SG_ windowReqRearLeft_DCFR : 10|3@0+ (1,0) [0|6] "" DCRR,DCFR,DCFL,DCRL
 SG_ windowReqRearRight_DCFR : 13|3@0+ (1,0) [0|6] "" DCRL,DCFR,DCFL,DCRR
 SG_ nothingPressed_DCFR : 14|1@0+ (1,0) [0|1] "" DCRR,DCRL,DCFR,DCFL,TOOL
 SG_ buttonPressed_DCFR : 15|1@0+ (1,0) [0|1] "" DCRR,DCRL,DCFR,DCFL,TOOL
 SG_ windowReqFrontLeft_DCFR : 3|3@0+ (1,0) [0|6] "" DCRR,DCRL,DCFR,DCFL,BGW
 SG_ windowReqFrontRight_DCFR : 6|3@0+ (1,0) [0|6] "" DCRR,DCRL,DCFR,DCFL,BGW,TOOL
 SG_ mirrorUp_DCFR : 7|1@0+ (1,0) [0|1] "" DCRR,DCRL,DCFR,DCFL,TOOL
 SG_ extPassRearRelease_DCFR : 25|2@0+ (1,0) [0|2] "" DCRR,DCRL,DCFR,DCFL,FBCM
 SG_ intPassRearRelease_DCFR : 27|2@0+ (1,0) [0|2] "" DCRR,DCRL,DCFR,DCFL,FBCM
 SG_ frontRightPresentReq_DCFR : 29|2@0+ (1,0) [0|2] "" DCRR,DCRL,DCFR,DCFL,FBCM
 SG_ rearRightPresentReq_DCFR : 31|2@0+ (1,0) [0|2] "" DCRR,DCRL,DCFR,DCFL,FBCM

BO_ 651 DCFR_MirrorPosition: 3 DCFR
 SG_ mirrorStatusPosUpDownRh_DCFR : 11|12@0- (0.00391,0) [-8|8] "" BGW
 SG_ mirrorStatusPosInOutRh_DCFR : 7|12@0- (0.005374,0) [-11|11] "" BGW

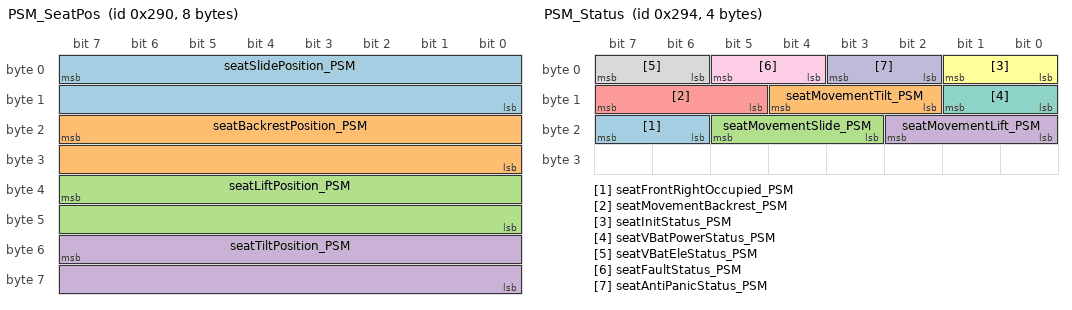
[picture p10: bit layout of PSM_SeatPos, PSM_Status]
BO_ 656 PSM_SeatPos: 8 PSM
 SG_ seatSlidePosition_PSM : 7|16@0- (1,0) [-32768|32766] "" BGW
 SG_ seatBackrestPosition_PSM : 23|16@0- (1,0) [-32768|32766] "" BGW
 SG_ seatLiftPosition_PSM : 39|16@0- (1,0) [-32768|32766] "" BGW
 SG_ seatTiltPosition_PSM : 55|16@0- (1,0) [-32768|32766] "" BGW

BO_ 660 PSM_Status: 4 PSM
 SG_ seatFrontRightOccupied_PSM : 23|2@0+ (1,0) [0|1] "" BGW,IHUB
 SG_ seatMovementTilt_PSM : 12|3@0+ (1,0) [0|3] "" BGW
 SG_ seatMovementSlide_PSM : 21|3@0+ (1,0) [0|3] "" BGW
 SG_ seatMovementLift_PSM : 18|3@0+ (1,0) [0|3] "" BGW
 SG_ seatMovementBackrest_PSM : 15|3@0+ (1,0) [0|3] "" BGW
 SG_ seatInitStatus_PSM : 1|2@0+ (1,0) [0|2] "" BGW
 SG_ seatVBatPowerStatus_PSM : 9|2@0+ (1,0) [0|1] "" BGW
 SG_ seatVBatEleStatus_PSM : 7|2@0+ (1,0) [0|1] "" BGW
 SG_ seatFaultStatus_PSM : 5|2@0+ (1,0) [0|2] "" BGW
 SG_ seatAntiPanicStatus_PSM : 3|2@0+ (1,0) [0|2] "" BGW

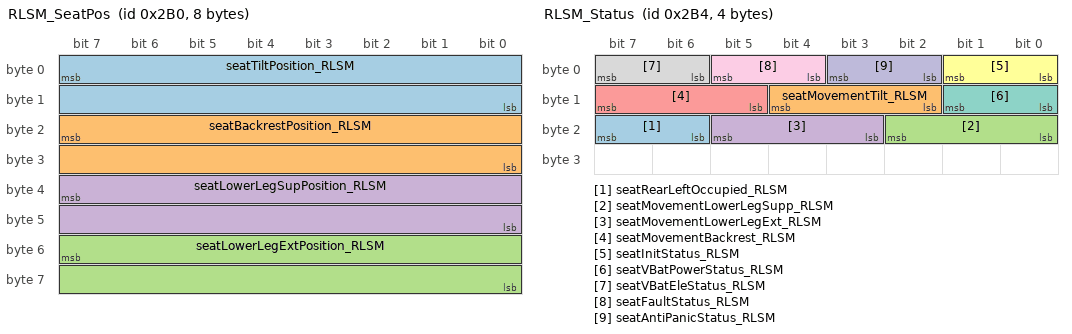
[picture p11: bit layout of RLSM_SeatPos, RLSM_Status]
BO_ 688 RLSM_SeatPos: 8 RLSM
 SG_ seatTiltPosition_RLSM : 7|16@0- (1,0) [-32768|32766] "" BGW
 SG_ seatBackrestPosition_RLSM : 23|16@0- (1,0) [-32768|32766] "" BGW
 SG_ seatLowerLegExtPosition_RLSM : 55|16@0- (1,0) [-32768|32766] "" BGW
 SG_ seatLowerLegSupPosition_RLSM : 39|16@0- (1,0) [-32768|32766] "" BGW

BO_ 689 RLSM_SeatPosV2: 4 RLSM
 SG_ seatBackrestPositionV2_RLSM : 7|16@0- (1,0) [-32768|32766] "" BGW

BO_ 692 RLSM_Status: 4 RLSM
 SG_ seatRearLeftOccupied_RLSM : 23|2@0+ (1,0) [0|1] "" BGW
 SG_ seatMovementTilt_RLSM : 12|3@0+ (1,0) [0|3] "" BGW
 SG_ seatMovementLowerLegSupp_RLSM : 18|3@0+ (1,0) [0|3] "" BGW
 SG_ seatMovementLowerLegExt_RLSM : 21|3@0+ (1,0) [0|3] "" BGW
 SG_ seatMovementBackrest_RLSM : 15|3@0+ (1,0) [0|3] "" BGW
 SG_ seatInitStatus_RLSM : 1|2@0+ (1,0) [0|2] "" BGW
 SG_ seatVBatPowerStatus_RLSM : 9|2@0+ (1,0) [0|1] "" BGW
 SG_ seatVBatEleStatus_RLSM : 7|2@0+ (1,0) [0|1] "" BGW
 SG_ seatFaultStatus_RLSM : 5|2@0+ (1,0) [0|2] "" BGW
 SG_ seatAntiPanicStatus_RLSM : 3|2@0+ (1,0) [0|2] "" BGW

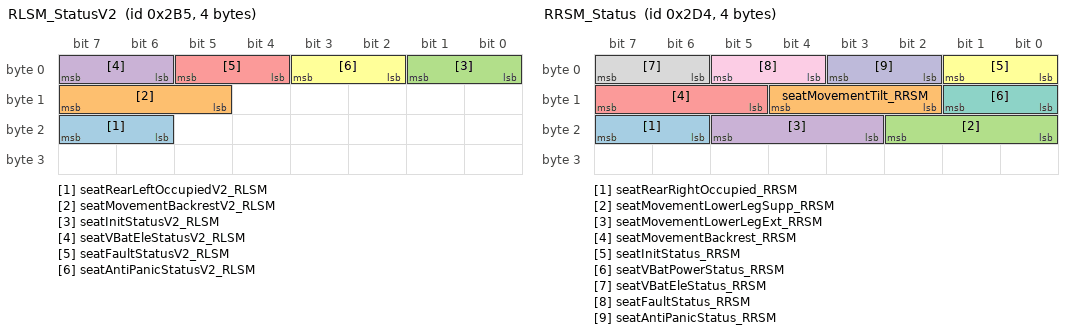
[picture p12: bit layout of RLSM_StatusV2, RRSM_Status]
BO_ 693 RLSM_StatusV2: 4 RLSM
 SG_ seatRearLeftOccupiedV2_RLSM : 23|2@0+ (1,0) [0|1] "" BGW
 SG_ seatMovementBackrestV2_RLSM : 15|3@0+ (1,0) [0|3] "" BGW
 SG_ seatInitStatusV2_RLSM : 1|2@0+ (1,0) [0|2] "" BGW
 SG_ seatVBatEleStatusV2_RLSM : 7|2@0+ (1,0) [0|1] "" BGW
 SG_ seatFaultStatusV2_RLSM : 5|2@0+ (1,0) [0|2] "" BGW
 SG_ seatAntiPanicStatusV2_RLSM : 3|2@0+ (1,0) [0|2] "" BGW

BO_ 720 RRSM_SeatPos: 8 RRSM
 SG_ seatLowerLegExtPosition_RRSM : 7|16@0- (1,0) [-32768|32766] "" BGW
 SG_ seatBackrestPosition_RRSM : 23|16@0- (1,0) [-32768|32766] "" BGW
 SG_ seatLowerLegSupPosition_RRSM : 39|16@0- (1,0) [-32768|32766] "" BGW
 SG_ seatTiltPosition_RRSM : 55|16@0- (1,0) [-32768|32766] "" BGW

BO_ 721 RRSM_SeatPosV2: 4 RRSM
 SG_ seatBackrestPositionV2_RRSM : 7|16@0- (1,0) [-32768|32766] "" BGW

BO_ 724 RRSM_Status: 4 RRSM
 SG_ seatRearRightOccupied_RRSM : 23|2@0+ (1,0) [0|1] "" BGW
 SG_ seatMovementTilt_RRSM : 12|3@0+ (1,0) [0|3] "" BGW
 SG_ seatMovementLowerLegSupp_RRSM : 18|3@0+ (1,0) [0|3] "" BGW
 SG_ seatMovementLowerLegExt_RRSM : 21|3@0+ (1,0) [0|3] "" BGW
 SG_ seatMovementBackrest_RRSM : 15|3@0+ (1,0) [0|3] "" BGW
 SG_ seatInitStatus_RRSM : 1|2@0+ (1,0) [0|2] "" BGW
 SG_ seatVBatPowerStatus_RRSM : 9|2@0+ (1,0) [0|1] "" BGW
 SG_ seatVBatEleStatus_RRSM : 7|2@0+ (1,0) [0|1] "" BGW
 SG_ seatFaultStatus_RRSM : 5|2@0+ (1,0) [0|2] "" BGW
 SG_ seatAntiPanicStatus_RRSM : 3|2@0+ (1,0) [0|2] "" BGW

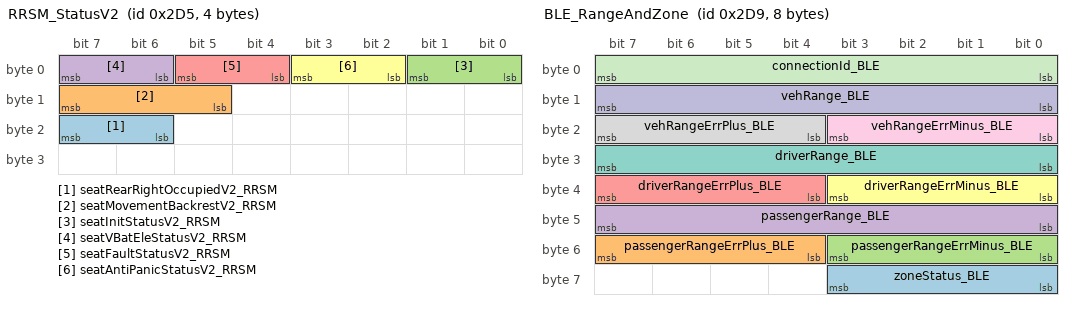
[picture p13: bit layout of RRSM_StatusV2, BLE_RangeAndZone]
BO_ 725 RRSM_StatusV2: 4 RRSM
 SG_ seatRearRightOccupiedV2_RRSM : 23|2@0+ (1,0) [0|1] "" BGW
 SG_ seatMovementBackrestV2_RRSM : 15|3@0+ (1,0) [0|3] "" BGW
 SG_ seatInitStatusV2_RRSM : 1|2@0+ (1,0) [0|2] "" BGW
 SG_ seatVBatEleStatusV2_RRSM : 7|2@0+ (1,0) [0|1] "" BGW
 SG_ seatFaultStatusV2_RRSM : 5|2@0+ (1,0) [0|2] "" BGW
 SG_ seatAntiPanicStatusV2_RRSM : 3|2@0+ (1,0) [0|2] "" BGW

BO_ 728 BLE_ConnectionStarted: 2 BLE
 SG_ connectionState1_BLE : 9|2@0+ (1,0) [0|2] "" BGW
 SG_ connectionId1_BLE : 7|8@0+ (1,0) [0|254] "" BGW

BO_ 729 BLE_RangeAndZone: 8 BLE
 SG_ zoneStatus_BLE : 59|4@0+ (1,0) [0|14] "" BGW
 SG_ passengerRangeErrPlus_BLE : 55|4@0+ (1,0) [0|14] "" BGW
 SG_ passengerRangeErrMinus_BLE : 51|4@0+ (1,0) [0|14] "" BGW
 SG_ passengerRange_BLE : 47|8@0+ (0.1,0) [0|25.4] "meters" BGW
 SG_ driverRangeErrPlus_BLE : 39|4@0+ (1,0) [0|14] "" BGW
 SG_ driverRangeErrMinus_BLE : 35|4@0+ (1,0) [0|14] "" BGW
 SG_ driverRange_BLE : 31|8@0+ (0.1,0) [0|25.4] "meters" BGW
 SG_ vehRangeErrPlus_BLE : 23|4@0+ (1,0) [0|14] "" BGW
 SG_ vehRangeErrMinus_BLE : 19|4@0+ (1,0) [0|14] "" BGW
 SG_ vehRange_BLE : 15|8@0+ (0.1,0) [0|25.4] "meters" BGW
 SG_ connectionId_BLE : 7|8@0+ (1,0) [0|254] "" BGW

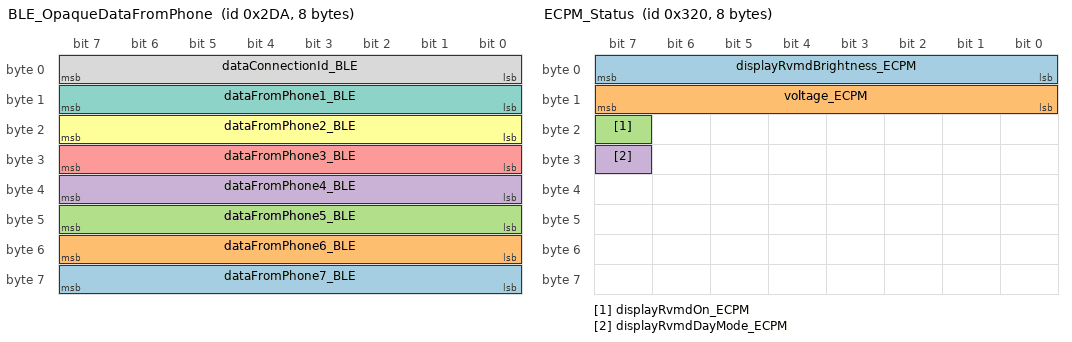
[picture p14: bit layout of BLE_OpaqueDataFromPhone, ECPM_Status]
BO_ 730 BLE_OpaqueDataFromPhone: 8 BLE
 SG_ dataFromPhone7_BLE : 63|8@0+ (1,0) [0|254] "" BGW
 SG_ dataFromPhone6_BLE : 55|8@0+ (1,0) [0|254] "" BGW
 SG_ dataFromPhone5_BLE : 47|8@0+ (1,0) [0|254] "" BGW
 SG_ dataFromPhone4_BLE : 39|8@0+ (1,0) [0|254] "" BGW
 SG_ dataFromPhone3_BLE : 31|8@0+ (1,0) [0|254] "" BGW
 SG_ dataFromPhone2_BLE : 23|8@0+ (1,0) [0|254] "" BGW
 SG_ dataFromPhone1_BLE : 15|8@0+ (1,0) [0|254] "" BGW
 SG_ dataConnectionId_BLE : 7|8@0+ (1,0) [0|254] "" BGW

BO_ 776 BGW_InteriorLightingCmd: 3 BGW
 SG_ gblInteriorLightCounter_BGW : 23|8@0+ (1,0) [0|254] "" DCFL,DCFR,DCRL,DCRR,FBCM
 SG_ brightnessInterior_BGW : 7|4@0+ (0.07,0) [0|0.98] "" ECPM,DCFL,DCFR,DCRL,DCRR,FBCM
 SG_ sequenceIdInterior_BGW : 15|8@0+ (1,0) [0|254] "" DCFL,DCFR,DCRL,DCRR,FBCM

BO_ 777 BGW_InfoFromIHUB2: 8 BGW
 SG_ nAirConditionRR_IHUB : 57|2@0+ (1,0) [0|2] "" RRDP
 SG_ nAirConditionRL_IHUB : 59|2@0+ (1,0) [0|2] "" RLDP
 SG_ nAirConditionFR_IHUB : 61|2@0+ (1,0) [0|2] "" PDP
 SG_ nAirConditionFL_IHUB : 63|2@0+ (1,0) [0|2] "" DDP
 SG_ doorPanelHvacDisableRR_IHUB : 49|2@0+ (1,0) [0|2] "" RRDP
 SG_ doorPanelHvacDisableRL_IHUB : 51|2@0+ (1,0) [0|2] "" RLDP
 SG_ doorPanelHvacDisableFR_IHUB : 53|2@0+ (1,0) [0|2] "" PDP
 SG_ doorPanelHvacDisableFL_IHUB : 55|2@0+ (1,0) [0|2] "" DDP
 SG_ doorPanelAudioDisableRR_IHUB : 41|2@0+ (1,0) [0|2] "" RRDP
 SG_ doorPanelAudioDisableRL_IHUB : 43|2@0+ (1,0) [0|2] "" RLDP
 SG_ doorPanelAudioDisableFR_IHUB : 45|2@0+ (1,0) [0|2] "" PDP
 SG_ doorPanelAudioDisableFL_IHUB : 47|2@0+ (1,0) [0|2] "" DDP
 SG_ volumeStatusFL_IHUB : 7|6@0+ (1,0) [0|45] "" DDP
 SG_ volumeStatusFR_IHUB : 1|6@0+ (1,0) [0|45] "" PDP
 SG_ volumeStatusRL_IHUB : 21|6@0+ (1,0) [0|45] "" RLDP
 SG_ volumeStatusRR_IHUB : 11|6@0+ (1,0) [0|45] "" RRDP
 SG_ muteStatusFL_IHUB : 25|2@0+ (1,0) [0|1] "" DDP
 SG_ muteStatusFR_IHUB : 27|2@0+ (1,0) [0|1] "" PDP
 SG_ muteStatusRL_IHUB : 29|2@0+ (1,0) [0|1] "" RLDP
 SG_ muteStatusRR_IHUB : 31|2@0+ (1,0) [0|1] "" RRDP
 SG_ seatRelaxedStatusFL_IHUB : 33|2@0+ (1,0) [0|2] "" DDP
 SG_ seatRelaxedStatusFR_IHUB : 35|2@0+ (1,0) [0|2] "" PDP
 SG_ seatRelaxedStatusRL_IHUB : 37|2@0+ (1,0) [0|2] "" RLDP
 SG_ seatRelaxedStatusRR_IHUB : 39|2@0+ (1,0) [0|2] "" RRDP

BO_ 778 BGW_GoToAbsPositionRRSM: 8 BGW
 SG_ seatLowerLegExtAbsPosRRSM_BGW : 7|16@0- (1,0) [-32768|32766] "" RRSM
 SG_ seatBackrestAbsPosRRSM_BGW : 23|16@0- (1,0) [-32768|32766] "" RRSM
 SG_ seatLowerLegSupAbsPosRRSM_BGW : 39|16@0- (1,0) [-32768|32766] "" RRSM
 SG_ seatTiltAbsPosRRSM_BGW : 55|16@0- (1,0) [-32768|32766] "" RRSM

BO_ 779 BGW_AestheticLightingCmd: 3 BGW
 SG_ globalLightingCounter_IHUB : 23|8@0+ (1,0) [0|254] "" FBCM,FRDC,RRDC,FLDC,RLDC,FFL,HLL,HLR,ACCL,LGL,RCLR,RCLL
 SG_ brightness_IHUB : 7|4@0+ (0.07,0) [0|0.98] "%" ECPM,RRDC,RLDC,FRDC,FLDC,FFL
 SG_ sequenceId_IHUB : 15|8@0+ (1,0) [0|254] "" RRDC,RLDC,FRDC,FLDC,FFL,HLL,HLR,ACCL,LGL,RCLR,RCLL

BO_ 781 BGW_GoToAbsPositionDSM: 8 BGW
 SG_ seatSlideAbsPosDSM_BGW : 7|16@0- (1,0) [-32768|32766] "" DSM
 SG_ seatBackrestAbsPosDSM_BGW : 23|16@0- (1,0) [-32768|32766] "" DSM
 SG_ seatLiftAbsPosDSM_BGW : 39|16@0- (1,0) [-32768|32766] "" DSM
 SG_ seatTiltAbsPosDSM_BGW : 55|16@0- (1,0) [-32768|32766] "" DSM

BO_ 782 BGW_GoToAbsPositionPSM: 8 BGW
 SG_ seatSlideAbsPosPSM_BGW : 7|16@0- (1,0) [-32768|32766] "" PSM
 SG_ seatBackrestAbsPosPSM_BGW : 23|16@0- (1,0) [-32768|32766] "" PSM
 SG_ seatLiftAbsPosPSM_BGW : 39|16@0- (1,0) [-32768|32766] "" PSM
 SG_ seatTiltAbsPosPSM_BGW : 55|16@0- (1,0) [-32768|32766] "" PSM

BO_ 783 BGW_GoToAbsPositionRLSM: 8 BGW
 SG_ seatLowerLegExtAbsPosRLSM_BGW : 7|16@0- (1,0) [-32768|32766] "" RLSM
 SG_ seatBackrestAbsPosRLSM_BGW : 23|16@0- (1,0) [-32768|32766] "" RLSM
 SG_ seatLowerLegSupAbsPosRLSM_BGW : 39|16@0- (1,0) [-32768|32766] "" RLSM
 SG_ seatTiltAbsPosRLSM_BGW : 55|16@0- (1,0) [-32768|32766] "" RLSM

BO_ 800 ECPM_Status: 8 ECPM
 SG_ displayRvmdBrightness_ECPM : 7|8@0+ (1,0) [0|100] "" TOOL
 SG_ voltage_ECPM : 15|8@0+ (0.1,0) [0|25.4] "" TOOL
 SG_ displayRvmdOn_ECPM : 23|1@0+ (1,0) [0|1] "" TOOL
 SG_ displayRvmdDayMode_ECPM : 31|1@0+ (1,0) [0|1] "" TOOL

BO_ 801 ECPM_DtcMatrix: 8 ECPM

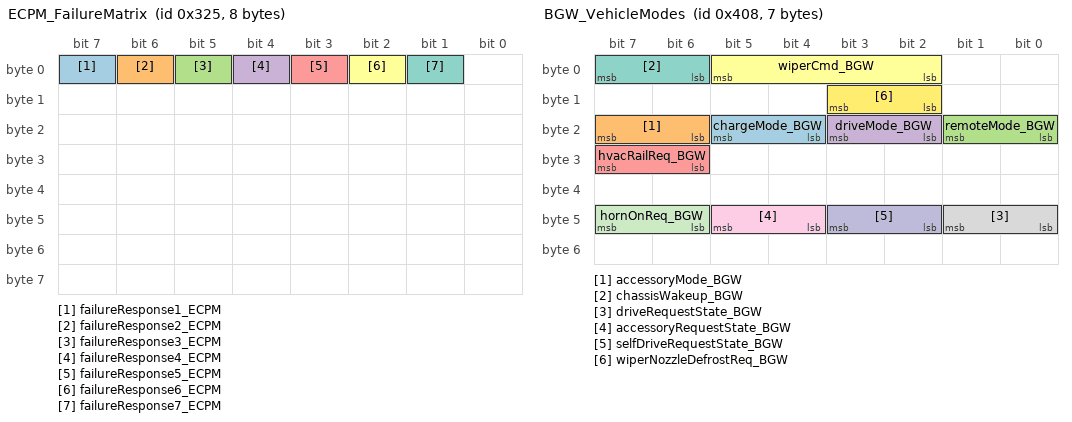
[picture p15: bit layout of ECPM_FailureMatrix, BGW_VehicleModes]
BO_ 805 ECPM_FailureMatrix: 8 ECPM
 SG_ failureResponse1_ECPM : 7|1@0+ (1,0) [0|1] "" TOOL
 SG_ failureResponse2_ECPM : 6|1@0+ (1,0) [0|1] "" TOOL
 SG_ failureResponse3_ECPM : 5|1@0+ (1,0) [0|1] "" TOOL
 SG_ failureResponse4_ECPM : 4|1@0+ (1,0) [0|1] "" TOOL
 SG_ failureResponse5_ECPM : 3|1@0+ (1,0) [0|1] "" TOOL
 SG_ failureResponse6_ECPM : 2|1@0+ (1,0) [0|1] "" TOOL
 SG_ failureResponse7_ECPM : 1|1@0+ (1,0) [0|1] "" TOOL

BO_ 807 ECPM_Debug: 8 ECPM

BO_ 1032 BGW_VehicleModes: 7 BGW
 SG_ chargeMode_BGW : 21|2@0+ (1,0) [0|2] "" DCFL,DCFR,DCRL,DCRR,FBCM
 SG_ accessoryMode_BGW : 23|2@0+ (1,0) [0|2] "" DCFL,DCFR,DCRL,DCRR,FBCM
 SG_ remoteMode_BGW : 17|2@0+ (1,0) [0|2] "" DCFL,DCFR,DCRL,DCRR,FBCM
 SG_ driveMode_BGW : 19|2@0+ (1,0) [0|2] "" DCFL,DCFR,DCRL,DCRR,FBCM
 SG_ hvacRailReq_BGW : 31|2@0+ (1,0) [0|2] "" FBCM,RBCM
 SG_ wiperCmd_BGW : 5|4@0+ (1,0) [0|14] "" FBCM
 SG_ chassisWakeup_BGW : 7|2@0+ (1,0) [0|2] "" FBCM,RBCM
 SG_ driveRequestState_BGW : 41|2@0+ (1,0) [0|2] "" RBCM,DCFL,DCFR,DCRL,DCRR,FBCM
 SG_ accessoryRequestState_BGW : 45|2@0+ (1,0) [0|2] "" RBCM,FBCM
 SG_ selfDriveRequestState_BGW : 43|2@0+ (1,0) [0|2] "" FBCM,RBCM
 SG_ hornOnReq_BGW : 47|2@0+ (1,0) [0|2] "" FBCM
 SG_ wiperNozzleDefrostReq_BGW : 11|2@0+ (1,0) [0|2] "" ECPM,FBCM

BO_ 1033 BGW_InfoFromIHUB: 7 BGW
 SG_ exteriorLightReq_IHUB : 51|3@0+ (1,0) [0|7] "" FBCM
 SG_ rearSeatDisplayUpDownReq_IHUB : 33|2@0+ (1,0) [0|2] "" FBCM
 SG_ frunkLockReq_IHUB : 17|2@0+ (1,0) [0|2] "" FBCM
 SG_ liftgateLockReq_IHUB : 27|2@0+ (1,0) [0|2] "" FBCM
 SG_ doorRRLockReq_IHUB : 29|2@0+ (1,0) [0|2] "" FBCM
 SG_ doorRLLockReq_IHUB : 31|2@0+ (1,0) [0|2] "" FBCM
 SG_ doorFRLockReq_IHUB : 25|2@0+ (1,0) [0|2] "" FBCM
 SG_ doorFLLockReq_IHUB : 39|2@0+ (1,0) [0|2] "" FBCM
 SG_ doorRearRightOperation_IHUB : 11|4@0+ (1,0) [0|14] "" DCFL,DCFR,DCRR,DCRL,FBCM
 SG_ doorRearLeftOperation_IHUB : 7|4@0+ (1,0) [0|14] "" DCFL,DCFR,DCRR,DCRL,FBCM
 SG_ doorFrontRightOperation_IHUB : 3|4@0+ (1,0) [0|14] "" DCFL,DCFR,DCRR,DCRL,FBCM
 SG_ doorFrontLeftOperation_IHUB : 15|4@0+ (1,0) [0|14] "" DCFL,DCFR,DCRR,DCRL,FBCM
 SG_ lightLowBeamOnReq_IHUB : 19|2@0+ (1,0) [0|2] "" FBCM,RBCM
 SG_ frontHoodOpen_IHUB : 23|2@0+ (1,0) [0|2] "" FBCM,RBCM
 SG_ liftgateOperation_IHUB : 21|2@0+ (1,0) [0|2] "" RBCM
 SG_ fogSwitchRear_IHUB : 37|2@0+ (1,0) [0|2] "" RBCM
 SG_ fogSwitchFront_IHUB : 35|2@0+ (1,0) [0|2] "" FBCM
 SG_ range_IHUB : 47|12@0+ (0.5,0) [0|2047] "km" DBPC,PBPC

BO_ 1034 TOOL_SeatCalib: 1 TOOL
 SG_ seatToCalib_TOOL : 6|4@0+ (1,0) [0|14] "" BGW
 SG_ seatCalibInstruct_TOOL : 2|3@0+ (1,0) [0|6] "" BGW

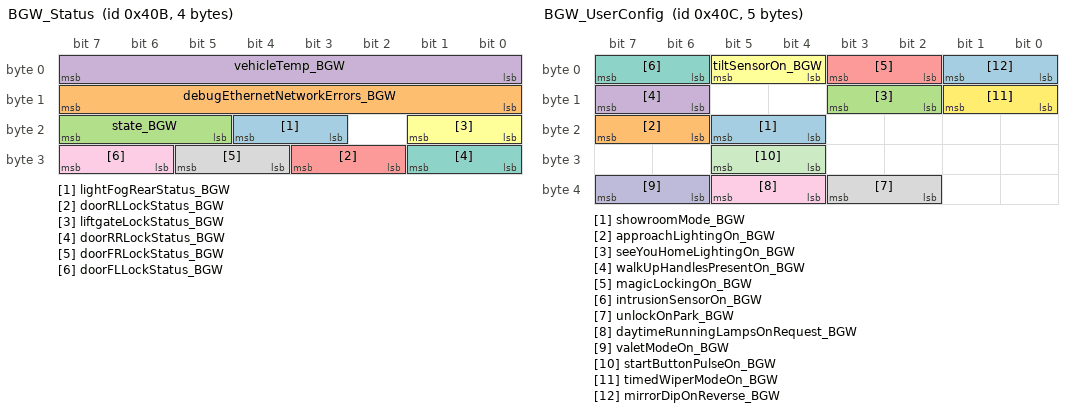
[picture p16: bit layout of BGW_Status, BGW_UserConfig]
BO_ 1035 BGW_Status: 4 BGW
 SG_ lightFogRearStatus_BGW : 20|2@0+ (1,0) [0|2] "" IHUB
 SG_ debugEthernetNetworkErrors_BGW : 15|8@0+ (1,0) [0|62] "" TOOL
 SG_ state_BGW : 23|3@0+ (1,0) [0|6] "" TOOL
 SG_ vehicleTemp_BGW : 7|8@0- (1,0) [-40|125] "C" TOOL,FBCM
 SG_ doorRLLockStatus_BGW : 27|2@0+ (1,0) [0|2] "" FBCM,DCFL,DCFR,DCRL,DCRR,DDP,PDP,RBCM,RLDP,RRDP
 SG_ liftgateLockStatus_BGW : 17|2@0+ (1,0) [0|2] "" FBCM,DCFL,DCFR,DCRL,DCRR,DDP,PDP,RBCM,RLDP,RRDP
 SG_ doorRRLockStatus_BGW : 25|2@0+ (1,0) [0|2] "" FBCM,DCFL,DCFR,DCRL,DCRR,DDP,PDP,RBCM,RLDP,RRDP
 SG_ doorFRLockStatus_BGW : 29|2@0+ (1,0) [0|2] "" FBCM,DCFL,DCFR,DCRL,DCRR,DDP,PDP,RBCM,RLDP,RRDP
 SG_ doorFLLockStatus_BGW : 31|2@0+ (1,0) [0|2] "" FBCM,DCFL,DCFR,DCRL,DCRR,DDP,PDP,RBCM,RLDP,RRDP

BO_ 1036 BGW_UserConfig: 5 BGW
 SG_ showroomMode_BGW : 21|2@0+ (1,0) [0|2] "" TOOL
 SG_ approachLightingOn_BGW : 23|2@0+ (1,0) [0|2] "" FBCM
 SG_ seeYouHomeLightingOn_BGW : 11|2@0+ (1,0) [0|2] "" FBCM
 SG_ walkUpHandlesPresentOn_BGW : 15|2@0+ (1,0) [0|2] "" TOOL
 SG_ magicLockingOn_BGW : 3|2@0+ (1,0) [0|2] "" TOOL
 SG_ tiltSensorOn_BGW : 5|2@0+ (1,0) [0|2] "" TOOL
 SG_ intrusionSensorOn_BGW : 7|2@0+ (1,0) [0|2] "" TOOL
 SG_ unlockOnPark_BGW : 35|2@0+ (1,0) [0|2] "" FBCM
 SG_ daytimeRunningLampsOnRequest_BGW : 37|2@0+ (1,0) [0|2] "" RBCM
 SG_ valetModeOn_BGW : 39|2@0+ (1,0) [0|2] "" RBCM,FBCM
 SG_ startButtonPulseOn_BGW : 29|2@0+ (1,0) [0|2] "" FBCM
 SG_ timedWiperModeOn_BGW : 9|2@0+ (1,0) [0|2] "" RBCM
 SG_ mirrorDipOnReverse_BGW : 1|2@0+ (1,0) [0|2] "" ECPM,DCFL,DCFR

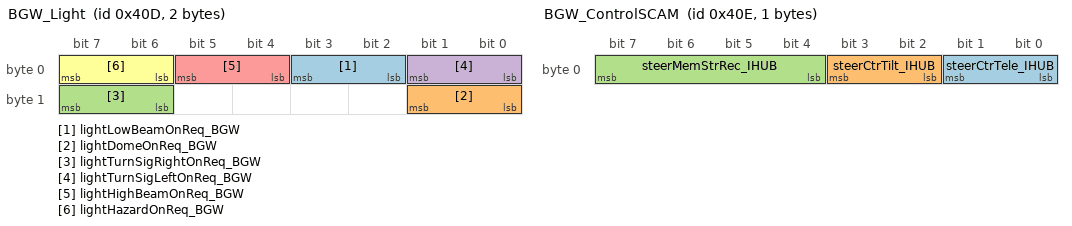
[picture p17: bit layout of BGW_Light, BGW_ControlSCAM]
BO_ 1037 BGW_Light: 2 BGW
 SG_ lightLowBeamOnReq_BGW : 3|2@0+ (1,0) [0|2] "" FBCM,RBCM,HLL,HLR
 SG_ lightDomeOnReq_BGW : 9|2@0+ (1,0) [0|2] "" FBCM,RBCM
 SG_ lightTurnSigRightOnReq_BGW : 15|2@0+ (1,0) [0|2] "" FBCM,RBCM,HLL,HLR
 SG_ lightTurnSigLeftOnReq_BGW : 1|2@0+ (1,0) [0|2] "" FBCM,RBCM,HLL,HLR
 SG_ lightHighBeamOnReq_BGW : 5|2@0+ (1,0) [0|2] "" FBCM,RBCM,HLL,HLR
 SG_ lightHazardOnReq_BGW : 7|2@0+ (1,0) [0|2] "" FBCM,RBCM,HLL,HLR

BO_ 1038 BGW_ControlSCAM: 1 BGW
 SG_ steerCtrTele_IHUB : 1|2@0+ (1,0) [0|2] "" SCAM
 SG_ steerCtrTilt_IHUB : 3|2@0+ (1,0) [0|2] "" SCAM
 SG_ steerMemStrRec_IHUB : 7|4@0+ (1,0) [0|14] "" SCAM

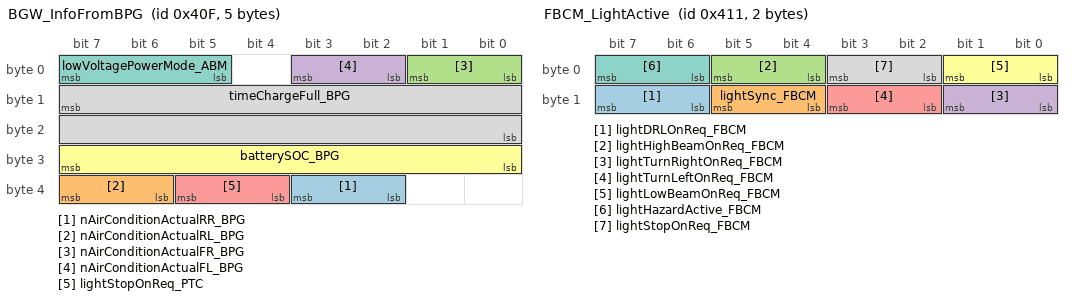
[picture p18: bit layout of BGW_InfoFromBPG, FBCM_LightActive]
BO_ 1039 BGW_InfoFromBPG: 5 BGW
 SG_ nAirConditionActualRR_BPG : 35|2@0+ (1,0) [0|2] "" RRDP
 SG_ nAirConditionActualRL_BPG : 39|2@0+ (1,0) [0|2] "" RLDP
 SG_ nAirConditionActualFR_BPG : 1|2@0+ (1,0) [0|2] "" PDP
 SG_ nAirConditionActualFL_BPG : 3|2@0+ (1,0) [0|2] "" DDP
 SG_ lightStopOnReq_PTC : 37|2@0+ (1,0) [0|2] "" ECPM,DCRL,DCRR,DCFR,DCFL,RCLR,RCLL,LGL,RBCM
 SG_ batterySOC_BPG : 31|8@0+ (0.5,0) [0|100] "%" PBPC,DBPC
 SG_ lowVoltagePowerMode_ABM : 7|3@0+ (1,0) [0|3] "" RBCM,FBCM
 SG_ timeChargeFull_BPG : 15|16@0+ (1,0) [0|65534] "minutes" PBPC,DBPC

BO_ 1041 FBCM_LightActive: 2 FBCM
 SG_ lightDRLOnReq_FBCM : 15|2@0+ (1,0) [0|2] "" BGW,IHUB,HUD,HLR,HLL
 SG_ lightSync_FBCM : 13|2@0+ (1,0) [0|2] "" DCFL,DCFR,RCLR,RCLL,RBCM,HLL,HLR,BGW,IHUB
 SG_ lightHighBeamOnReq_FBCM : 5|2@0+ (1,0) [0|2] "" IHUB,RCLR,LGL,RCLL,ACCL,HUD,RBCM,BGW,HLL,HLR
 SG_ lightTurnRightOnReq_FBCM : 9|2@0+ (1,0) [0|2] "" IHUB,DCFR,RCLR,RCLL,FRDC,HUD,RBCM,BGW,HLL,HLR
 SG_ lightTurnLeftOnReq_FBCM : 11|2@0+ (1,0) [0|2] "" IHUB,DCFL,RCLL,RCLR,FLDC,HUD,RBCM,BGW,HLL,HLR
 SG_ lightLowBeamOnReq_FBCM : 1|2@0+ (1,0) [0|2] "" IHUB,HUD,RBCM,BGW,HLL,HLR
 SG_ lightHazardActive_FBCM : 7|2@0+ (1,0) [0|2] "" DCFR,DCFL,HUD,RBCM,BGW,HLL,HLR,IPC
 SG_ lightStopOnReq_FBCM : 3|2@0+ (1,0) [0|2] "" RBCM,RCLL,RCLR

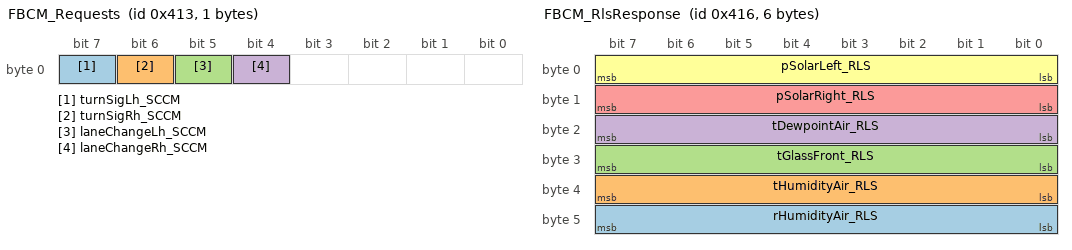
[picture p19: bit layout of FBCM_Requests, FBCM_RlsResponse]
BO_ 1043 FBCM_Requests: 1 FBCM
 SG_ turnSigLh_SCCM : 7|1@0+ (1,0) [0|1] "" BGW
 SG_ turnSigRh_SCCM : 6|1@0+ (1,0) [0|1] "" BGW
 SG_ laneChangeLh_SCCM : 5|1@0+ (1,0) [0|1] "" BGW
 SG_ laneChangeRh_SCCM : 4|1@0+ (1,0) [0|1] "" BGW

BO_ 1045 FBCM_Status: 7 FBCM
 SG_ chargePortDoorStatus_FBCM : 23|3@0+ (1,0) [0|2] "" IHUB,BGW
 SG_ lightHazardStatus_FBCM : 9|2@0+ (1,0) [0|2] "" HUD,IHUB,BGW
 SG_ lightFogFrontStatus_FBCM : 11|2@0+ (1,0) [0|2] "" BGW,IHUB
 SG_ lightDomeStatus_FBCM : 53|2@0+ (1,0) [0|2] "" BGW
 SG_ brakeFluidLevel_FBCM : 55|2@0+ (1,0) [0|2] "" BGW,IHUB
 SG_ lightFogFrontRightStatus_FBCM : 17|2@0+ (1,0) [0|2] "" ECPM,HUD,ACCL,HLL,HLR,LGL,RCLL,RCLR,BGW
 SG_ lightFogFrontLeftStatus_FBCM : 25|2@0+ (1,0) [0|2] "" ECPM,HUD,ACCL,HLL,HLR,LGL,RCLL,RCLR,BGW
 SG_ srsStatus_FBCM : 7|2@0+ (1,0) [0|2] "" BGW
 SG_ wiperStatus_LWMM : 15|4@0+ (1,0) [0|14] "" HUD,BGW
 SG_ washerFluidLevel_FBCM : 27|2@0+ (1,0) [0|2] "" HUD,BGW,IHUB
 SG_ hornStatus_FBCM : 29|2@0+ (1,0) [0|2] "" BGW
 SG_ stateVehicle_FBCM : 4|3@0+ (1,0) [0|6] "" ECPM,RCLR,RCLL,LGL,HLR,HLL,ACCL,BGW,RBCM
 SG_ scStatus_FBCM : 45|4@0+ (1,0) [0|14] "" BGW
 SG_ frontTrunkStatus_FBCM : 31|2@0+ (1,0) [0|2] "" RBCM,BGW
 SG_ lockRejected_FBCM : 19|2@0+ (1,0) [0|2] "" BGW,RBCM
 SG_ dtcPresent_FBCM : 1|2@0+ (1,0) [0|2] "" BGW
 SG_ scClusterMessage_FBCM : 39|10@0+ (1,0) [0|1022] "" BGW
 SG_ rsdStatus_FBCM : 51|3@0+ (1,0) [0|6] "" BGW,RLDP,RRDP

BO_ 1046 FBCM_RlsResponse: 6 FBCM
 SG_ rHumidityAir_RLS : 47|8@0+ (0.5,0) [0|100] "% RH" BGW
 SG_ tHumidityAir_RLS : 39|8@0+ (0.5,-40) [-40|87] "deg C" BGW
 SG_ tGlassFront_RLS : 31|8@0+ (0.5,-40) [-40|87] "deg C" BGW
 SG_ tDewpointAir_RLS : 23|8@0+ (0.5,-40) [-40|87] "deg C" BGW
 SG_ pSolarRight_RLS : 15|8@0+ (5,0) [0|1200] " W/m2" BGW
 SG_ pSolarLeft_RLS : 7|8@0+ (5,0) [0|1200] "W/m2" BGW

BO_ 1056 RBCM_Status: 5 RBCM
 SG_ liftgateOpenStatus_RBCM : 37|2@0+ (1,0) [0|2] "" BGW
 SG_ lightDomeStatus_RBCM : 39|2@0+ (1,0) [0|2] "" BGW
 SG_ liftgateStatus_RBCM : 27|3@0+ (1,0) [0|6] "" BGW
 SG_ lightCHMSLStatus_RBCM : 29|2@0+ (1,0) [0|2] "" BGW
 SG_ lightStopTrailerStatus_RBCM : 31|2@0+ (1,0) [0|2] "" BGW
 SG_ lightTailTrailerStatus_RBCM : 17|2@0+ (1,0) [0|2] "" BGW
 SG_ lightHazardStatus_RBCM : 19|2@0+ (1,0) [0|2] "" BGW
 SG_ lightTailLeftStatus_RBCM : 21|2@0+ (1,0) [0|2] "" HUD,BGW
 SG_ lightTailRightStatus_RBCM : 23|2@0+ (1,0) [0|2] "" HUD,BGW
 SG_ lightTurnRightStatus_RBCM : 9|2@0+ (1,0) [0|2] "" BGW
 SG_ lightStopLeftStatus_RBCM : 11|2@0+ (1,0) [0|2] "" BGW
 SG_ lightTurnLeftStatus_RBCM : 13|2@0+ (1,0) [0|2] "" BGW
 SG_ lightStopRightStatus_RBCM : 15|2@0+ (1,0) [0|2] "" BGW
 SG_ licencePlateIllumStatus_RBCM : 1|2@0+ (1,0) [0|2] "" BGW
 SG_ lightFogRearLeftStatus_RBCM : 3|2@0+ (1,0) [0|2] "" ECPM,ACCL,HLL,HLR,LGL,RCLL,RCLR,HUD,BGW
 SG_ lightReverseStatus_RBCM : 5|2@0+ (1,0) [0|2] "" BGW
 SG_ lightFogRearRightStatus_RBCM : 7|2@0+ (1,0) [0|2] "" ECPM,ACCL,HLL,HLR,LGL,RCLL,RCLR,HUD,BGW

CM_ BU_ ACCL "Accessory Lamp";
CM_ BU_ BGW "Body Control Gateway";
CM_ BU_ BLE "Bluetooth Low Energy SCM (System Control Module)";
CM_ BU_ DBPC "Driver B-Pillar Controller";
CM_ BU_ DCFL "Door Controller Front Left";
CM_ BU_ DCFR "Door Controller Front Right";
CM_ BU_ DCRL "Door Controller Rear Left";
CM_ BU_ DCRR "Door Controller Rear Right";
CM_ BU_ DDP "Driver Door Panel";
CM_ BU_ DSM "Driver Seat Module";
CM_ BU_ ECPM "Exterior Camera Processing Module";
CM_ BU_ FBCM "Front Body Control Module";
CM_ BU_ FFL "Front Facia Lighting";
CM_ BU_ FLDC "Front Left Door Cladding";
CM_ BU_ FRDC "Front Right Door Cladding";
CM_ BU_ HLL "Head Light Left ";
CM_ BU_ HLR "Head Light Right";
CM_ BU_ HUD "Heads Up Display (Receiver Only)";
CM_ BU_ IHUB "IPC portion of Infotainment Hub (Receiver Only)";
CM_ BU_ LGL "Lift Gate Lighting";
CM_ BU_ PBPC "Passenger B-Pillar Control Module";
CM_ BU_ PDP "Passenger Door Panel";
CM_ BU_ PSM "Passenger Seat Module";
CM_ BU_ RBCM "Rear Body Control Module (Merged with BGW for Gamma)";
CM_ BU_ RCLL "RCL Tail Lamp Left";
CM_ BU_ RCLR "RCL Tail Lamp Right";
CM_ BU_ RLDC "Rear Left Door Cladding";
CM_ BU_ RLDP "Rear Left Door Panel";
CM_ BU_ RLSM "Rear Left Seat Module";
CM_ BU_ RRDC "Rear Right Door Cladding";
CM_ BU_ RRDP "Rear Right Door Panel";
CM_ BU_ RRSM "Rear Right Seat Module";
CM_ BU_ SCAM "Steering Column Adjust Module";
CM_ BU_ TOOL "Diagnostic tool";CM_ BO_ undefined "made 10 second cyclic for bus loading issue. will fix later.";
CM_ BO_ undefined "Made cyclic time 10s for bus loading issue. Will fix later.";
CM_ BO_ undefined "Values are ascii letters from the number zero to capital Z. Lowercase letters are not supported for VIN.";
CM_ BO_ undefined "Debug message used to capture task CPU usage. Temporary.";CM_ SG_ 265 taskEthTx_BGW "Temporary signal for debugging.";
CM_ SG_ 265 taskEthRx_BGW "Temporary signal for debugging.";
CM_ SG_ 265 task100Hz_BGW "Temporary signal for debugging.";
CM_ SG_ 265 task1000Hz_BGW "Temporary signal for debugging.";
CM_ SG_ 269 wirelessChargePadRR_IHUB "Should originate from WCPM3";
CM_ SG_ 269 wirelessChargePadRL_IHUB "Should originate from WCPM2";
CM_ SG_ 269 mirrorDimmingEnableDisable_IHUB "Enables/Disables mirror dimming function. Level of dimming is determined by SDCM.";
CM_ SG_ 267 vehicleSpeedQ_ESP "VehicleSpeed Qualifier";
CM_ SG_ 267 vehicleSpeed_ESP "ESP calculated vehicle speed. Average of front wheels on rear wheel drive vehicles. Average of all four wheels on dual motor vehicles.";
CM_ SG_ 271 screenCommandR_BGW "RENAME, GATEWAYED from IHUB. Information to display on Passenger B-Pillar Display";
CM_ SG_ 271 screenCommandL_BGW "RENAME, GATEWAYED from IHUB. Information to display on Driver B-Pillar Display";
CM_ SG_ 271 panelSelectForBrightness_IHUB "RENAME, GATEWAYED from IHUB. Used in combination with panelBrightness_IHUB to dim screens";
CM_ SG_ 271 nightModeSelect_IHUB "UNSURE of function";
CM_ SG_ 271 panelBrightness_IHUB "RENAME, GATEWAYED from IHUB. Used in combination with panelSelectForBrightness_IHUB to dim screens";
CM_ SG_ 520 seatPsngrTiltCmd_BGW "RENAME, GATEWAYED from IHUB. Command passenger seat tilt to increment or decrement";
CM_ SG_ 520 seatPsngrSlideCmd_BGW "RENAME, GATEWAYED from IHUB. Command passenger seat slide to increment or decrement";
CM_ SG_ 520 seatPsngrLiftCmd_BGW "RENAME, GATEWAYED from IHUB. Command passenger seat lift to increment or decrement";
CM_ SG_ 520 seatPsngrBackrestCmd_BGW "RENAME, GATEWAYED from IHUB. Command passenger backrest to increment or decrement";
CM_ SG_ 520 seatDriverTiltCmd_BGW "RENAME, GATEWAYED from IHUB. Command driver seat tilt to increment or decrement";
CM_ SG_ 520 seatDriverSlideCmd_BGW "RENAME, GATEWAYED from IHUB. Command driver seat slide to increment or decrement";
CM_ SG_ 520 seatDriverLiftCmd_BGW "RENAME, GATEWAYED from IHUB. Command driver seat lift to increment or decrement";
CM_ SG_ 520 seatDriverCushionCmd_BGW "RENAME, GATEWAYED from IHUB. Command driver seat cushion to increment or decrement";
CM_ SG_ 520 seatDriverBackrestCmd_BGW "RENAME, GATEWAYED from IHUB. Command driver backrest to increment or decrement";
CM_ SG_ 521 seatRearRTiltCmd_BGW "RENAME, GATEWAYED from IHUB. Command rear right seat tilt to increment or decrement";
CM_ SG_ 521 seatRearRLowerLegExtCmd_BGW "RENAME, GATEWAYED from IHUB. Command rear right leg extension to increment or decrement";
CM_ SG_ 521 seatRearRBackrestCmd_BGW "RENAME, GATEWAYED from IHUB. Command rear right seat backrest to increment or decrement";
CM_ SG_ 521 seatRearRLowerLegSupCmd_BGW "RENAME, GATEWAYED from IHUB. Command rear right leg support to increment or decrement";
CM_ SG_ 521 seatRearLTiltCmd_BGW "RENAME, GATEWAYED from IHUB. Command rear left seat tilt to increment or decrement";
CM_ SG_ 521 seatRearLLowerLegExtCmd_BGW "RENAME, GATEWAYED from IHUB. Command rear left seat leg extension to increment or decrement";
CM_ SG_ 521 seatRearLBackrestCmd_BGW "RENAME, GATEWAYED from IHUB. Command rear left seat tilt to increment or decrement";
CM_ SG_ 521 seatRearLLowerLegSupCmd_BGW "RENAME, GATEWAYED from IHUB. Command rear left seat leg support to increment or decrement";
CM_ SG_ 522 seatMassgReqOnOffDSM_BGW "RENAME, GATEWAYED from IHUB";
CM_ SG_ 522 seatMassgReqMassgSpdLvlDSM_BGW "RENAME, GATEWAYED from IHUB";
CM_ SG_ 522 seatMassgReqMassgProgDSM_BGW "RENAME, GATEWAYED from IHUB";
CM_ SG_ 522 seatMassgReqMassgIntenDSM_BGW "RENAME, GATEWAYED from IHUB";
CM_ SG_ 522 seatEngPAmbAir1DSM_BGW "RENAME, GATEWAYED from IHUB";
CM_ SG_ 522 seatIndVlvCtrlDSM_BGW "RENAME, GATEWAYED from IHUB";
CM_ SG_ 522 seatPmpRunDSM_BGW "RENAME, GATEWAYED from IHUB";
CM_ SG_ 522 seatShIncDSM_BGW "RENAME, GATEWAYED from IHUB";
CM_ SG_ 522 seatShDecDSM_BGW "RENAME, GATEWAYED from IHUB";
CM_ SG_ 522 seatCushIncDSM_BGW "RENAME, GATEWAYED from IHUB";
CM_ SG_ 522 seatCushDecDSM_BGW "RENAME, GATEWAYED from IHUB";
CM_ SG_ 522 seatBackSaveSetToMemDSM_BGW "RENAME, GATEWAYED from IHUB";
CM_ SG_ 522 seatBackCtrReqInOutEasyDSM_BGW "RENAME, GATEWAYED from IHUB";
CM_ SG_ 522 seatDiAutCorrnDSM_BGW "RENAME, GATEWAYED from IHUB";
CM_ SG_ 522 seatEmgyStopDSM_BGW "RENAME, GATEWAYED from IHUB";
CM_ SG_ 522 seatBackPosnStoreDSM_BGW "RENAME, GATEWAYED from IHUB";
CM_ SG_ 522 seatBackPosnRestoreDSM_BGW "RENAME, GATEWAYED from IHUB";
CM_ SG_ 522 seatMemSeatCtrlDSM_BGW "RENAME, GATEWAYED from IHUB";
CM_ SG_ 522 seatProfPenDSM_BGW "RENAME, GATEWAYED from IHUB";
CM_ SG_ 522 seatLumIncDSM_BGW "RENAME, GATEWAYED from IHUB";
CM_ SG_ 522 seatLumDecDSM_BGW "RENAME, GATEWAYED from IHUB";
CM_ SG_ 522 seatLumUpDSM_BGW "RENAME, GATEWAYED from IHUB";
CM_ SG_ 522 seatLumDwnDSM_BGW "RENAME, GATEWAYED from IHUB";
CM_ SG_ 522 seatBackBlstrDecDSM_BGW "RENAME, GATEWAYED from IHUB";
CM_ SG_ 522 seatBackBlstrIncDSM_BGW "RENAME, GATEWAYED from IHUB";
CM_ SG_ 523 seatEngPAmbAir1PSM_BGW "RENAME, GATEWAYED from IHUB";
CM_ SG_ 523 seatShIncPSM_BGW "RENAME, GATEWAYED from IHUB";
CM_ SG_ 523 seatShDecPSM_BGW "RENAME, GATEWAYED from IHUB";
CM_ SG_ 523 seatLumUpPSM_BGW "RENAME, GATEWAYED from IHUB";
CM_ SG_ 523 seatLumIncPSM_BGW "RENAME, GATEWAYED from IHUB";
CM_ SG_ 523 seatLumDwnPSM_BGW "RENAME, GATEWAYED from IHUB";
CM_ SG_ 523 seatLumDecPSM_BGW "RENAME, GATEWAYED from IHUB";
CM_ SG_ 523 seatCushIncPSM_BGW "RENAME, GATEWAYED from IHUB";
CM_ SG_ 523 seatCushDecPSM_BGW "RENAME, GATEWAYED from IHUB";
CM_ SG_ 523 seatBackSaveSetToMemPSM_BGW "RENAME, GATEWAYED from IHUB";
CM_ SG_ 523 seatBackPosnStorePSM_BGW "RENAME, GATEWAYED from IHUB";
CM_ SG_ 523 seatBackPosnRestorePSM_BGW "RENAME, GATEWAYED from IHUB";
CM_ SG_ 523 seatBackCtrReqInOutEasyPSM_BGW "RENAME, GATEWAYED from IHUB";
CM_ SG_ 523 seatBackBlstrIncPSM_BGW "RENAME, GATEWAYED from IHUB";
CM_ SG_ 523 seatProfPenPSM_BGW "RENAME, GATEWAYED from IHUB";
CM_ SG_ 523 seatPmpRunPSM_BGW "RENAME, GATEWAYED from IHUB";
CM_ SG_ 523 seatMemSeatCtrlPSM_BGW "RENAME, GATEWAYED from IHUB";
CM_ SG_ 523 seatMassgReqOnOffPSM_BGW "RENAME, GATEWAYED from IHUB";
CM_ SG_ 523 seatMassgReqMassgSpdLvlPSM_BGW "RENAME, GATEWAYED from IHUB";
CM_ SG_ 523 seatMassgReqMassgProgPSM_BGW "RENAME, GATEWAYED from IHUB";
CM_ SG_ 523 seatMassgReqMassgIntenPSM_BGW "RENAME, GATEWAYED from IHUB";
CM_ SG_ 523 seatIndVlvCtrlPSM_BGW "RENAME, GATEWAYED from IHUB";
CM_ SG_ 523 seatEmgyStopPSM_BGW "RENAME, GATEWAYED from IHUB";
CM_ SG_ 523 seatDiAutCorrnPSM_BGW "RENAME, GATEWAYED from IHUB";
CM_ SG_ 523 seatBackBlstrDecPSM_BGW "RENAME, GATEWAYED from IHUB";
CM_ SG_ 524 seatRearRBackrestCmdV2_BGW "RENAME, GATEWAYED from IHUB";
CM_ SG_ 524 seatRearLBackrestCmdV2_BGW "RENAME, GATEWAYED from IHUB";
CM_ SG_ 526 lightLaneChangeRightOnReq_SDCM "Right lane change request from SDCM.";
CM_ SG_ 526 lightLaneChangeLeftOnReq_SDCM "Left lane change request from SDCM";
CM_ SG_ 526 autoValetCountdown_BGW "RENAME, GATEWAYED from SDCM";
CM_ SG_ 526 mirrorDimmingLvlReq_SDCM "Configures level of mirror dimming.";
CM_ SG_ 568 stspTe_SCAM "Softstop Tele";
CM_ SG_ 568 stspTi_SCAM "Softstop Tilt";
CM_ SG_ 568 plsHTe_SCAM "Plausability HALL Tele";
CM_ SG_ 568 shcHTe_SCAM "Short Circuit HALL Tele";
CM_ SG_ 568 drpHTe_SCAM "Disruption HALL Tele";
CM_ SG_ 568 schMTe_SCAM "Short Circuit Motor Tele";
CM_ SG_ 568 drpMTe_SCAM "Disruption Motor Tele";
CM_ SG_ 568 ovcTe_SCAM "Overcurrent Tele";
CM_ SG_ 568 hiTmpTe_SCAM "High Temperature Tele";
CM_ SG_ 568 stallTe_SCAM "Stall Tele";
CM_ SG_ 568 plsHTi_SCAM "Plausability HALL Tilt";
CM_ SG_ 568 shcHTi_SCAM "Short Circuit HALL Tilt";
CM_ SG_ 568 drpHTi_SCAM "Disruption HALL Tilt";
CM_ SG_ 568 shcMTi_SCAM "Short Circuit Motor Tilt";
CM_ SG_ 568 drpMTi_SCAM "Disruption Motor Tilt";
CM_ SG_ 568 ovcTi_SCAM "Overcurrent Tilt";
CM_ SG_ 568 hiTmpTi_SCAM "High Temperature Tilt";
CM_ SG_ 568 stallTi_SCAM "Stall Tilt";
CM_ SG_ 568 maxBlNum_SCAM "Maximum Block Number";
CM_ SG_ 568 overVolt_SCAM "Overvoltage";
CM_ SG_ 568 lowVolt_SCAM "Low Voltage";
CM_ SG_ 568 underVolt_SCAM "Undervoltage";
CM_ SG_ 568 comErr_SCAM "Communication Error";
CM_ SG_ 568 intErr_SCAM "Internal Error";
CM_ SG_ 569 dirTele_SCAM "Direction Tele";
CM_ SG_ 569 dirTilt_SCAM "Direction Tilt";
CM_ SG_ 569 recStat_SCAM "Status Recall";
CM_ SG_ 569 initStat_SCAM "Initialization status";
CM_ SG_ 569 posTele_SCAM "Position Tele";
CM_ SG_ 569 posTilt_SCAM "Position Tilt";
CM_ SG_ 608 doorIsUnlatched_DCFL "Front left door latched or unlatched";
CM_ SG_ 608 doorLockReq_DCFL "Front left door lock request status";
CM_ SG_ 608 doorMirrorState_DCFL "Left mirror retracted or presented status";
CM_ SG_ 608 doorState_DCFL "Front left door open, opening, closed, closing status";
CM_ SG_ 608 mirrorHeaterState_DCFL "Left door mirror heater status";
CM_ SG_ 608 sideRepeaterState_DCFL "Left side repeater status";
CM_ SG_ 608 doorDTCPresent_DCFL "Front left door DTC present status";
CM_ SG_ 608 mirrorStatusMovUpDownLeft_DCFL "Front left mirror up/down movement status";
CM_ SG_ 608 mirrorStatusMovInOutLeft_DCFL "Front left mirror inwords/outwords movement status";
CM_ SG_ 608 mirrorDefrostCamStatusLeft_DCFL "Front left mirror camera defrost status";
CM_ SG_ 608 mirrorFoldAutoStatusLeft_DCFL "Front left mirror auto-fold status";
CM_ SG_ 608 mirrorDimEnabDisableStatus_DCFL "Front left mirror dimming status";
CM_ SG_ 609 windowReqRearLeft_DCFL "Rear-Left window request status";
CM_ SG_ 609 windowReqRearRight_DCFL "Rear-Right window request status";
CM_ SG_ 609 windowReqFrontLeft_DCFL "Front-Left window request status";
CM_ SG_ 609 windowReqFrontRight_DCFL "Front-Right window request status";
CM_ SG_ 609 doorExtDriverRearRelease_DCFL "Body controller received command to open rear driver side door from the exterior release.";
CM_ SG_ 609 doorIntDriverRearRelease_DCFL "Body controller received command to open rear driver side door from the interior release.";
CM_ SG_ 624 seatSlidePosition_DSM "CHANGE units? Driver seat module reports absolute slide position in hall counts";
CM_ SG_ 624 seatBackrestPosition_DSM "CHANGE units? Driver seat module reports absolute backrest position in hall counts";
CM_ SG_ 624 seatLiftPosition_DSM "CHANGE units? Driver seat module reports absolute lift position in hall counts";
CM_ SG_ 624 seatTiltPosition_DSM "CHANGE units? Driver seat module reports absolute tilt position in hall counts";
CM_ SG_ 625 seatCushionPosition_DSM "CHANGE units? Driver seat module reports absolute cushion position in hall counts";
CM_ SG_ 628 seatFrontLeftOccupied_DSM "DSM reports whether driver seat is occupied";
CM_ SG_ 628 seatMovementTilt_DSM "DSM reports status of tilt maneuver";
CM_ SG_ 628 seatMovementSlide_DSM "DSM reports status of slide maneuver";
CM_ SG_ 628 seatMovementLift_DSM "DSM reports status of lift maneuver";
CM_ SG_ 628 seatMovementCushion_DSM "DSM reports status of cushion maneuver";
CM_ SG_ 628 seatMovementBackrest_DSM "DSM reports status of backrest maneuver";
CM_ SG_ 648 doorLockReq_DCFR "Front right door lock request status";
CM_ SG_ 648 mirrorHeaterState_DCFR "Right door mirror heater status";
CM_ SG_ 648 sideRepeaterState_DCFR "Right side repeater status";
CM_ SG_ 648 mirrorStatusMovUpDownRight_DCFR "Front right mirror up/down movement status";
CM_ SG_ 648 mirrorStatusMovInOutRight_DCFR "Front right mirror inwards/outwards movement status";
CM_ SG_ 648 mirrorDefrostCamStatusRight_DCFR "Front right mirror camera defrost status";
CM_ SG_ 648 mirrorFoldAutoStatusRight_DCFR "Front right mirror auto-fold status";
CM_ SG_ 648 mirrorDimEnabDisableStatus_DCFR "Front right mirror dimming status";
CM_ SG_ 649 windowReqRearLeft_DCFR "Rear-Left window request status";
CM_ SG_ 649 windowReqRearRight_DCFR "Rear-Right window request status";
CM_ SG_ 649 windowReqFrontLeft_DCFR "Front-Left window request status";
CM_ SG_ 649 windowReqFrontRight_DCFR "Front-Right window request status";
CM_ SG_ 649 extPassRearRelease_DCFR "Body controller received command to open rear passenger side door from the exterior release.";
CM_ SG_ 649 intPassRearRelease_DCFR "Body controller received command to open rear passenger side door from the interior release.";
CM_ SG_ 656 seatSlidePosition_PSM "CHANGE units? Passenger seat module reports absolute slide position in hall counts";
CM_ SG_ 656 seatBackrestPosition_PSM "CHANGE units? Passenger seat module reports absolute backrest position in hall counts";
CM_ SG_ 656 seatLiftPosition_PSM "CHANGE units? Passenger seat module reports absolute lift position in hall counts";
CM_ SG_ 656 seatTiltPosition_PSM "CHANGE units? Passenger seat module reports absolute tilt position in hall counts";
CM_ SG_ 660 seatFrontRightOccupied_PSM "Passenger seat module reports whether passenger seat is occupied";
CM_ SG_ 660 seatMovementTilt_PSM "Passenger seat module reports status of tilt maneuver";
CM_ SG_ 660 seatMovementSlide_PSM "Passenger seat module reports status of slide maneuver";
CM_ SG_ 660 seatMovementLift_PSM "Passenger seat module reports status of lift maneuver";
CM_ SG_ 660 seatMovementBackrest_PSM "Passenger seat module reports status of backrest maneuver";
CM_ SG_ 688 seatTiltPosition_RLSM "Rear left seat module reports absolute tilt position in hall counts";
CM_ SG_ 688 seatBackrestPosition_RLSM "Rear left seat module reports absolute backrest position in hall counts";
CM_ SG_ 688 seatLowerLegExtPosition_RLSM "Rear left seat module reports absolute leg extension position in hall counts";
CM_ SG_ 688 seatLowerLegSupPosition_RLSM "Rear left seat module reports absolute leg support position in hall counts";
CM_ SG_ 689 seatBackrestPositionV2_RLSM "Rear left seat module reports absolute backrest position for 60/40 configuration";
CM_ SG_ 692 seatRearLeftOccupied_RLSM "Rear left seat module reports whether seat is occupied";
CM_ SG_ 692 seatMovementTilt_RLSM "Rear left seat module reports status of tilt maneuver";
CM_ SG_ 692 seatMovementLowerLegSupp_RLSM "Rear left seat module reports status of leg support maneuver";
CM_ SG_ 692 seatMovementLowerLegExt_RLSM "Rear left seat module reports status of leg extension maneuver";
CM_ SG_ 692 seatMovementBackrest_RLSM "Rear left seat module reports status of backrest maneuver";
CM_ SG_ 693 seatRearLeftOccupiedV2_RLSM "Rear left seat module reports whether seat is occupied for 60/40 configuration";
CM_ SG_ 693 seatMovementBackrestV2_RLSM "Rear left seat module reports status of backrest maneuver for 60/40 configuration";
CM_ SG_ 721 seatBackrestPositionV2_RRSM "Rear right seat module reports absolute backrest position in hall counts";
CM_ SG_ 724 seatRearRightOccupied_RRSM "Rear right seat module reports whether seat is occupied";
CM_ SG_ 724 seatMovementTilt_RRSM "Rear right seat module reports status of tilt maneuver";
CM_ SG_ 724 seatMovementLowerLegSupp_RRSM "Rear right seat module reports status of leg support maneuver";
CM_ SG_ 724 seatMovementLowerLegExt_RRSM "Rear right seat module reports status of leg extension maneuver";
CM_ SG_ 724 seatMovementBackrest_RRSM "Rear right seat module reports status of backrest maneuver";
CM_ SG_ 725 seatRearRightOccupiedV2_RRSM "Rear right seat module reports whether seat is occupied for 60/40 configuration";
CM_ SG_ 725 seatMovementBackrestV2_RRSM "Rear right seat module reports status of backrest maneuver for 60/40 configuration";
CM_ SG_ 776 gblInteriorLightCounter_BGW "RENAME, GATEWAYED from IHUB?";
CM_ SG_ 776 brightnessInterior_BGW "RENAME, GATEWAYED from IHUB. Set brightness of interior aesthetic lighting";
CM_ SG_ 776 sequenceIdInterior_BGW "RENAME, GATEWAYED from IHUB. Set interior lighting sequence";
CM_ SG_ 778 seatLowerLegExtAbsPosRRSM_BGW "RENAME, GATEWAYED from IHUB. Set rear right seat leg extension position in hall counts";
CM_ SG_ 778 seatBackrestAbsPosRRSM_BGW "RENAME, GATEWAYED from IHUB. Set rear right seat backrest position in hall counts";
CM_ SG_ 778 seatLowerLegSupAbsPosRRSM_BGW "RENAME, GATEWAYED from IHUB. Set rear right seat leg support position in hall counts";
CM_ SG_ 778 seatTiltAbsPosRRSM_BGW "RENAME, GATEWAYED from IHUB. Set rear right seat tilt position in hall counts";
CM_ SG_ 779 globalLightingCounter_IHUB "RENAME, GATEWAYED from IHUB?";
CM_ SG_ 779 brightness_IHUB "RENAME, GATEWAYED from IHUB. Set brightness of exterior aesthetic lighting";
CM_ SG_ 779 sequenceId_IHUB "RENAME, GATEWAYED from IHUB. Set exterior lighting sequence";
CM_ SG_ 781 seatSlideAbsPosDSM_BGW "RENAME, GATEWAYED from IHUB. Set driver seat slide position in hall counts";
CM_ SG_ 781 seatBackrestAbsPosDSM_BGW "RENAME, GATEWAYED from IHUB. Set driver seat backrest position in hall counts";
CM_ SG_ 781 seatLiftAbsPosDSM_BGW "RENAME, GATEWAYED from IHUB. Set driver seat lift position in hall counts";
CM_ SG_ 781 seatTiltAbsPosDSM_BGW "RENAME, GATEWAYED from IHUB. Set driver seat tilt position in hall counts";
CM_ SG_ 782 seatSlideAbsPosPSM_BGW "RENAME, GATEWAYED from IHUB. Set passenger seat slide position in hall counts";
CM_ SG_ 782 seatBackrestAbsPosPSM_BGW "RENAME, GATEWAYED from IHUB. Set passenger seat backrest position in hall counts";
CM_ SG_ 782 seatLiftAbsPosPSM_BGW "RENAME, GATEWAYED from IHUB. Set passenger seat lift position in hall counts";
CM_ SG_ 782 seatTiltAbsPosPSM_BGW "RENAME, GATEWAYED from IHUB. Set passenger seat tilt position in hall counts";
CM_ SG_ 783 seatLowerLegExtAbsPosRLSM_BGW "RENAME, GATEWAYED from IHUB. Set rear left seat leg extension position in hall counts";
CM_ SG_ 783 seatBackrestAbsPosRLSM_BGW "RENAME, GATEWAYED from IHUB. Set rear left seat backrest position in hall counts";
CM_ SG_ 783 seatLowerLegSupAbsPosRLSM_BGW "RENAME, GATEWAYED from IHUB. Set rear left seat leg support in hall counts";
CM_ SG_ 783 seatTiltAbsPosRLSM_BGW "RENAME, GATEWAYED from IHUB. Set rear left seat tilt position in hall counts";
CM_ SG_ 1032 driveMode_BGW "Defines vehicle level drive mode/status.";
CM_ SG_ 1032 hvacRailReq_BGW "Gateway is requesting enable of the HVAC 12V rail";
CM_ SG_ 1032 wiperCmd_BGW "Wiper Command from BGW";
CM_ SG_ 1032 chassisWakeup_BGW "Request enable of chassis relay control";
CM_ SG_ 1032 driveRequestState_BGW "This request signal is sent by the BGW to the FBCM and RBCM. If TRUE, make state transition from Accessory to Drive. If FALSE, make state transition from Drive to Accessory.";
CM_ SG_ 1032 accessoryRequestState_BGW "This request signal is sent by the BGW to the FBCM and RBCM. If TRUE, make state transition from Standby to Accessory. If FALSE, make state transition from Accessory to Standby.";
CM_ SG_ 1032 selfDriveRequestState_BGW "This request signal is sent by the BGW to the FBCM and RBCM. If TRUE, make state transition from Accessory to Self Drive. If FALSE, make state transition from Self Drive to Accessory.";
CM_ SG_ 1032 hornOnReq_BGW "RENAME, GATEWAYED from SDCM. Request horns to be actuated by FBCM";
CM_ SG_ 1032 wiperNozzleDefrostReq_BGW "RENAME, GATEWAYED from IHUB/SDCM? Request FBCM and ECPM to turn on defrost controls";
CM_ SG_ 1033 exteriorLightReq_IHUB "Request exterior lights.";
CM_ SG_ 1033 rearSeatDisplayUpDownReq_IHUB "IHUB commands FBCM to raise/lower the Rear Seat Display";
CM_ SG_ 1033 frunkLockReq_IHUB "REVIEW locking strategy. IHUB requests FBCM to lock front trunk";
CM_ SG_ 1033 liftgateLockReq_IHUB "REVIEW locking strategy. IHUB requests FBCM to lock liftgate";
CM_ SG_ 1033 doorRRLockReq_IHUB "REVIEW locking strategy. IHUB requests FBCM to lock rear right door";
CM_ SG_ 1033 doorRLLockReq_IHUB "REVIEW locking strategy. IHUB requests FBCM to lock rear left door";
CM_ SG_ 1033 doorFRLockReq_IHUB "REVIEW locking strategy. IHUB requests FBCM to lock front right door";
CM_ SG_ 1033 doorFLLockReq_IHUB "REVIEW locking strategy. IHUB requests FBCM to lock front left door";
CM_ SG_ 1033 doorRearRightOperation_IHUB "Request door to open, close, pop";
CM_ SG_ 1033 doorRearLeftOperation_IHUB "Request door to open, close, pop";
CM_ SG_ 1033 doorFrontRightOperation_IHUB "Request door to open, close, pop";
CM_ SG_ 1033 doorFrontLeftOperation_IHUB "Request door to open, close, pop";
CM_ SG_ 1033 lightLowBeamOnReq_IHUB "Request low beams on/off";
CM_ SG_ 1033 frontHoodOpen_IHUB "Request FBCM to pop hood (front trunk)";
CM_ SG_ 1033 liftgateOperation_IHUB "CHANGE receiver to BGW. Request to power open liftgate";
CM_ SG_ 1033 fogSwitchRear_IHUB "Request rear fog lights on/off";
CM_ SG_ 1033 fogSwitchFront_IHUB "Request front fog lights on/off";
CM_ SG_ 1033 range_IHUB "IHUB calculates vehicle range to display on B-Pillar Displays";
CM_ SG_ 1034 seatToCalib_TOOL "Seat selection for calibration";
CM_ SG_ 1034 seatCalibInstruct_TOOL "Seat calibration command";
CM_ SG_ 1035 lightFogRearStatus_BGW "Status of the rear fog light";
CM_ SG_ 1035 debugEthernetNetworkErrors_BGW "Diagnostic signal for ethernet traffic. Not for production";
CM_ SG_ 1035 vehicleTemp_BGW "REVIEW purpose. Vehicle Temperature";
CM_ SG_ 1035 doorRLLockStatus_BGW "Rear-Left door lock status";
CM_ SG_ 1035 liftgateLockStatus_BGW "Liftgate lock status";
CM_ SG_ 1035 doorRRLockStatus_BGW "Rear-Right door lock status";
CM_ SG_ 1035 doorFRLockStatus_BGW "Front-Right door lock status";
CM_ SG_ 1035 doorFLLockStatus_BGW "Front-Left door lock status";
CM_ SG_ 1036 daytimeRunningLampsOnRequest_BGW "User config";
CM_ SG_ 1037 lightLowBeamOnReq_BGW "REMOVE for Beta only";
CM_ SG_ 1037 lightDomeOnReq_BGW "Gateway is requesting enable of the dome light";
CM_ SG_ 1037 lightTurnSigRightOnReq_BGW "RENAME, GATEWAYED from ADAS";
CM_ SG_ 1037 lightTurnSigLeftOnReq_BGW "RENAME, GATEWAYED from ADAS";
CM_ SG_ 1037 lightHighBeamOnReq_BGW "RENAME, GATEWAYED from ADAS";
CM_ SG_ 1037 lightHazardOnReq_BGW "RENAME, GATEWAYED from ADAS";
CM_ SG_ 1038 steerCtrTele_IHUB "Control Telescope";
CM_ SG_ 1038 steerCtrTilt_IHUB "Control Tilt";
CM_ SG_ 1038 steerMemStrRec_IHUB "Memory Store and Recall Control";
CM_ SG_ 1039 nAirConditionActualRR_BPG "Should originate from TCM";
CM_ SG_ 1039 nAirConditionActualRL_BPG "Should originate from TCM";
CM_ SG_ 1039 nAirConditionActualFR_BPG "Should originate from TCM";
CM_ SG_ 1039 nAirConditionActualFL_BPG "Should originate from TCM";
CM_ SG_ 1039 lightStopOnReq_PTC "Brake Light Request";
CM_ SG_ 1039 batterySOC_BPG "HV battery state of charge for B-Pillar display";
CM_ SG_ 1039 lowVoltagePowerMode_ABM "Power management strategy";
CM_ SG_ 1039 timeChargeFull_BPG "Time to full charge for B-Pillar display";
CM_ SG_ 1041 lightDRLOnReq_FBCM "Daytime running lights on request.";
CM_ SG_ 1041 lightSync_FBCM "To sync the front and rear turn and hazard lights";
CM_ SG_ 1041 lightHighBeamOnReq_FBCM "RENAME lightHighBeamOnReq_FBCM. High Beam headlight on request";
CM_ SG_ 1041 lightTurnRightOnReq_FBCM "RENAME lightTurnRightOnReq_FBCM. Turn right on request from FBCM";
CM_ SG_ 1041 lightTurnLeftOnReq_FBCM "RENAME lightTurnLeftOnReq_FBCM. Turn Left on request from FBCM";
CM_ SG_ 1041 lightLowBeamOnReq_FBCM "RENAME lightLowBeamOnReq_FBCM. Low Beam headlight on request from FBCM";
CM_ SG_ 1041 lightHazardActive_FBCM "Front Hazard light status. Do not remove as its needed for compatibility with hazard lights";
CM_ SG_ 1041 lightStopOnReq_FBCM "Signal to turn on the brake lights from FBCM";
CM_ SG_ 1045 scStatus_FBCM "Placeholder 4 bit status";
CM_ SG_ 1045 frontTrunkStatus_FBCM "Front trunk open status";
CM_ SG_ 1045 lockRejected_FBCM "The lock request was rejected";
CM_ SG_ 1045 scClusterMessage_FBCM "Security controller cluster message number";
CM_ SG_ 1056 lightDomeStatus_RBCM "Status of courtesy lighting (rear dome light)";
CM_ SG_ 1056 lightStopTrailerStatus_RBCM "Brake Trailer Status";
CM_ SG_ 1056 lightTailTrailerStatus_RBCM "Park Trailer Light StatusPark Trailer Light Status";
CM_ SG_ 1056 lightTailLeftStatus_RBCM "Left Tail light status";
CM_ SG_ 1056 lightTailRightStatus_RBCM "Right tail light status";
CM_ SG_ 1056 lightTurnRightStatus_RBCM "Right sidelight status from RBCM";
CM_ SG_ 1056 lightStopLeftStatus_RBCM "Left brake light status";
CM_ SG_ 1056 lightTurnLeftStatus_RBCM "Left sidelight status";
CM_ SG_ 1056 lightStopRightStatus_RBCM "Right brake light status";
CM_ SG_ 1056 licencePlateIllumStatus_RBCM "License Plate lightt status";
CM_ SG_ 1056 lightFogRearLeftStatus_RBCM "Rear fog light status";
CM_ SG_ 1056 lightReverseStatus_RBCM "Reverse light status";
CM_ SG_ 1056 lightFogRearRightStatus_RBCM "Rear fog light status";
VAL_ 534 eventsUnread_FBCM 3 "SNA" 2 "NotUsed" 1 "NewEvents" 0 "NoNewEvents" ;
VAL_ 534 eventNotification_FBCM 3 "SNA" 2 "Untested" 1 "Set" 0 "Cleared" ;
VAL_ 534 eventAssert_FBCM 3 "SNA" 2 "Untested" 1 "Set" 0 "Cleared" ;
VAL_ 15 fim001InhibitDrive_BGW 3 "SNA" 2 "InhibitedOnlyRemoteCause" 1 "InhibitedLocalCause" 0 "NotInhibited" ;
VAL_ 15 eventsUnread_BGW 3 "SNA" 2 "NotUsed" 1 "NewEvents" 0 "NoNewEvents" ;
VAL_ 15 eventNotification_BGW 3 "SNA" 2 "Untested" 1 "Set" 0 "Cleared" ;
VAL_ 15 eventAssert_BGW 3 "SNA" 2 "Untested" 1 "Set" 0 "Cleared" ;
VAL_ 15 dem001IhubMIAOnEthernet_BGW 3 "SNA" 2 "Untested" 1 "Set" 0 "Cleared" ;
VAL_ 269 chargePortDoorOpenReq_IHUB 3 "SNA" 2 "NoCommand" 1 "True" 0 "False" ;
VAL_ 269 doorPassengerWindowLock_IHUB 3 "SNA" 2 "NoChange" 1 "Unlock" 0 "Lock" ;
VAL_ 269 doorPanelRsdDisableRR_IHUB 3 "SNA" 1 "True" 0 "False" ;
VAL_ 269 doorPanelRsdDisableRL_IHUB 3 "SNA" 1 "True" 0 "False" ;
VAL_ 269 nAirConditionAutoRR_IHUB 3 "SNA" 1 "True" 0 "False" ;
VAL_ 269 nAirConditionAutoRL_IHUB 3 "SNA" 1 "True" 0 "False" ;
VAL_ 269 nAirConditionAutoFR_IHUB 3 "SNA" 1 "True" 0 "False" ;
VAL_ 269 nAirConditionAutoFL_IHUB 3 "SNA" 1 "True" 0 "False" ;
VAL_ 269 seatMemoryRR_IHUB 3 "SNA" 2 "NotSaved" 1 "PosSaved" 0 "NoAction" ;
VAL_ 269 seatMemoryRL_IHUB 3 "SNA" 2 "NotSaved" 1 "PosSaved" 0 "NoAction" ;
VAL_ 269 seatMemoryFL_IHUB 3 "SNA" 2 "NotSaved" 1 "PosSaved" 0 "NoAction" ;
VAL_ 269 seatMemoryFR_IHUB 3 "SNA" 2 "NotSaved" 1 "PosSaved" 0 "NoAction" ;
VAL_ 269 screenDisplayTempUnitsRRDP_IHUB 3 "SNA" 1 "Fahrenheit" 0 "Celsius" ;
VAL_ 269 screenDisplayTempUnitsRLDP_IHUB 3 "SNA" 1 "Fahrenheit" 0 "Celsius" ;
VAL_ 269 screenDisplayTempUnitsPDP_IHUB 3 "SNA" 1 "Fahrenheit" 0 "Celsius" ;
VAL_ 269 screenDisplayTempUnitsDDP_IHUB 3 "SNA" 1 "Fahrenheit" 0 "Celsius" ;
VAL_ 269 personalAssistantCmdRR_IHUB 7 "SNA" 4 "AiDisabled" 3 "AiAvailable" 2 "AiOutput" 1 "AiThinking" 0 "AiListening" ;
VAL_ 269 personalAssistantCmdRL_IHUB 7 "SNA" 4 "AiDisabled" 3 "AiAvailable" 2 "AiOutput" 1 "AiThinking" 0 "AiListening" ;
VAL_ 269 personalAssistantCmdFR_IHUB 7 "SNA" 4 "AiDisabled" 3 "AiAvailable" 2 "AiOutput" 1 "AiThinking" 0 "AiListening" ;
VAL_ 269 personalAssistantCmdFL_IHUB 7 "SNA" 4 "AiDisabled" 3 "AiAvailable" 2 "AiOutput" 1 "AiThinking" 0 "AiListening" ;
VAL_ 269 wirelessChargePadRR_IHUB 7 "SNA" 3 "Error" 2 "ChargingComplete" 1 "Charging" 0 "NotCharging" ;
VAL_ 269 wirelessChargePadRL_IHUB 7 "SNA" 3 "Error" 2 "ChargingComplete" 1 "Charging" 0 "NotCharging" ;
VAL_ 269 windowReqFrontLeft_IHUB 3 "SNA" 2 "AutoUp" 1 "AutoDown" 0 "NoCommand" ;
VAL_ 269 windowReqFrontRight_IHUB 3 "SNA" 2 "AutoUp" 1 "AutoDown" 0 "NoCommand" ;
VAL_ 269 windowReqRearLeft_IHUB 3 "SNA" 2 "AutoUp" 1 "AutoDown" 0 "NoCommand" ;
VAL_ 269 windowReqRearRight_IHUB 3 "SNA" 2 "AutoUp" 1 "AutoDown" 0 "NoCommand" ;
VAL_ 269 mirrorDimmingEnableDisable_IHUB 3 "SNA" 1 "Enable" 0 "Disable" ;
VAL_ 269 lightHazardOnReq_IHUB 3 "SNA" 1 "On" 0 "Off" ;
VAL_ 269 hornOnReq_IHUB 3 "SNA" 1 "On" 0 "Off" ;
VAL_ 714 fimPreventDrive_DCRR 3 "SNA" 2 "InhibitedOnlyRemoteCause" 1 "InhibitedLocalCause" 0 "NotInhibited" ;
VAL_ 714 fimNoCurrent_DCRR 3 "SNA" 2 "InhibitedOnlyRemoteCause" 1 "InhibitedLocalCause" 0 "NotInhibited" ;
VAL_ 714 eventsUnread_DCRR 3 "SNA" 2 "NotUsed" 1 "NewEvents" 0 "NoNewEvents" ;
VAL_ 714 eventAssert_DCRR 3 "SNA" 2 "Untested" 1 "Set" 0 "Cleared" ;
VAL_ 714 eventNotification_DCRR 3 "SNA" 2 "Untested" 1 "Set" 0 "Cleared" ;
VAL_ 714 fimOverCurrent_DCRR 3 "SNA" 2 "InhibitedOnlyRemoteCause" 1 "InhibitedLocalCause" 0 "NotInhibited" ;
VAL_ 270 deviceStateOfChargeFR_IHUB 127 "SNA" ;
VAL_ 270 deviceStateOfChargeFL_IHUB 127 "SNA" ;
VAL_ 270 deviceStateOfChargeRL_IHUB 127 "SNA" ;
VAL_ 270 deviceStateOfChargeRR_IHUB 127 "SNA" ;
VAL_ 270 deviceChargingFR_IHUB 3 "SNA" 1 "True" 0 "False" ;
VAL_ 270 deviceChargingFL_IHUB 3 "SNA" 1 "True" 0 "False" ;
VAL_ 270 deviceChargingRL_IHUB 3 "SNA" 1 "True" 0 "False" ;
VAL_ 270 deviceChargingRR_IHUB 3 "SNA" 1 "True" 0 "False" ;
VAL_ 270 deviceSignalStrengthRL_IHUB 7 "SNA" 5 "5" 4 "4" 3 "3" 2 "2" 1 "1" 0 "0" ;
VAL_ 270 deviceSignalStrengthFR_IHUB 7 "SNA" 5 "5" 4 "4" 3 "3" 2 "2" 1 "1" 0 "0" ;
VAL_ 270 deviceSignalStrengthFL_IHUB 7 "SNA" 5 "5" 4 "4" 3 "3" 2 "2" 1 "1" 0 "0" ;
VAL_ 270 deviceSignalStrengthRR_IHUB 7 "SNA" 5 "5" 4 "4" 3 "3" 2 "2" 1 "1" 0 "0" ;
VAL_ 270 doorPanelDisableRR_IHUB 3 "SNA" 1 "True" 0 "False" ;
VAL_ 270 doorPanelDisableRL_IHUB 3 "SNA" 1 "True" 0 "False" ;
VAL_ 270 doorPanelDisableFR_IHUB 3 "SNA" 1 "True" 0 "False" ;
VAL_ 270 doorPanelDisableFL_IHUB 3 "SNA" 1 "True" 0 "False" ;
VAL_ 270 doorPanelSeatsDisableRR_IHUB 3 "SNA" 1 "True" 0 "False" ;
VAL_ 270 doorPanelSeatsDisableRL_IHUB 3 "SNA" 1 "True" 0 "False" ;
VAL_ 270 doorPanelSeatsDisableFR_IHUB 3 "SNA" 1 "True" 0 "False" ;
VAL_ 270 doorPanelSeatsDisableFL_IHUB 3 "SNA" 1 "True" 0 "False" ;
VAL_ 682 fimPreventDrive_DCRL 3 "SNA" 2 "InhibitedOnlyRemoteCause" 1 "InhibitedLocalCause" 0 "NotInhibited" ;
VAL_ 682 fimNoCurrent_DCRL 3 "SNA" 2 "InhibitedOnlyRemoteCause" 1 "InhibitedLocalCause" 0 "NotInhibited" ;
VAL_ 682 eventsUnread_DCRL 3 "SNA" 2 "NotUsed" 1 "NewEvents" 0 "NoNewEvents" ;
VAL_ 682 eventAssert_DCRL 3 "SNA" 2 "Untested" 1 "Set" 0 "Cleared" ;
VAL_ 682 eventNotification_DCRL 3 "SNA" 2 "Untested" 1 "Set" 0 "Cleared" ;
VAL_ 682 fimOverCurrent_DCRL 3 "SNA" 2 "InhibitedOnlyRemoteCause" 1 "InhibitedLocalCause" 0 "NotInhibited" ;
VAL_ 650 fimPreventDrive_DCFR 3 "SNA" 2 "InhibitedOnlyRemoteCause" 1 "InhibitedLocalCause" 0 "NotInhibited" ;
VAL_ 650 fimNoCurrent_DCFR 3 "SNA" 2 "InhibitedOnlyRemoteCause" 1 "InhibitedLocalCause" 0 "NotInhibited" ;
VAL_ 650 eventsUnread_DCFR 3 "SNA" 2 "NotUsed" 1 "NewEvents" 0 "NoNewEvents" ;
VAL_ 650 eventAssert_DCFR 3 "SNA" 2 "Untested" 1 "Set" 0 "Cleared" ;
VAL_ 650 eventNotification_DCFR 3 "SNA" 2 "Untested" 1 "Set" 0 "Cleared" ;
VAL_ 650 fimOverCurrent_DCFR 3 "SNA" 2 "InhibitedOnlyRemoteCause" 1 "InhibitedLocalCause" 0 "NotInhibited" ;
VAL_ 610 fimPreventDrive_DCFL 3 "SNA" 2 "InhibitedOnlyRemoteCause" 1 "InhibitedLocalCause" 0 "NotInhibited" ;
VAL_ 610 fimNoCurrent_DCFL 3 "SNA" 2 "InhibitedOnlyRemoteCause" 1 "InhibitedLocalCause" 0 "NotInhibited" ;
VAL_ 610 eventsUnread_DCFL 3 "SNA" 2 "NotUsed" 1 "NewEvents" 0 "NoNewEvents" ;
VAL_ 610 eventAssert_DCFL 3 "SNA" 2 "Untested" 1 "Set" 0 "Cleared" ;
VAL_ 610 eventNotification_DCFL 3 "SNA" 2 "Untested" 1 "Set" 0 "Cleared" ;
VAL_ 610 fimOverCurrent_DCFL 3 "SNA" 2 "InhibitedOnlyRemoteCause" 1 "InhibitedLocalCause" 0 "NotInhibited" ;
VAL_ 266 extSequenceId_IHUB 255 "SNA" 99 "Alarm" 98 "Unlock" 97 "Lock" 92 "Custom" 91 "RgbYellow" 90 "RgbRed" 89 "RgbBlue" 87 "RgbWhite" 56 "ObstructionRearRight" 55 "ObstructionRearLeft" 54 "ObstructionFrontRight" 53 "ObstructionFrontLeft" 52 "OpeningLhFrontAndRear" 51 "OpeningRhFrontAndRear" 47 "Hazard" 46 "Sleep" 45 "FollowHome" 44 "HappyDog" 43 "Awake" 42 "ChargingInterrupt" 41 "ChargingComplete" 40 "ChargingUnplugged" 39 "ChargingInProgress" 38 "ChargerReady" 34 "LatchedRearRight" 33 "LatchedFrontRight" 32 "LatchedRearLeft" 31 "LatchedFrontLeft" 30 "OpenRearRight" 29 "OpenFrontRight" 28 "OpenRearLeft" 27 "OpenFrontLeft" 26 "ClosingRearRight" 25 "ClosingFrontRight" 24 "ClosingRearLeft" 23 "ClosingFrontLeft" 22 "OpeningRearRight" 21 "OpeningFrontRight" 20 "OpeningRearLeft" 19 "OpeningFrontLeft" 18 "AutoValetComplete" 17 "AutoValetInProgress" 16 "AutoValetCountdown" 15 "Neutral" 14 "Reverse" 13 "AutoMode" 12 "Park" 11 "Drive" 10 "Test10" 9 "Test9" 8 "Test8" 7 "Test7" 6 "Test6" 5 "Test5" 4 "Test4" 3 "Test3" 2 "Test2" 1 "Test1" 0 "Null" ;
VAL_ 267 vehicleSpeedQ_ESP 3 "InSpec" 0 "UndefinableAccuracySna" ;
VAL_ 271 seatHeatVentStatusFL_IHUB 15 "SNA" 7 "Heat3" 6 "Heat2" 5 "Heat1" 4 "Off" 3 "Vent1" 2 "Vent2" 1 "Vent3" 0 "NoCommand" ;
VAL_ 271 seatHeatVentStatusFR_IHUB 15 "SNA" 7 "Heat3" 6 "Heat2" 5 "Heat1" 4 "Off" 3 "Vent1" 2 "Vent2" 1 "Vent3" 0 "NoCommand" ;
VAL_ 271 seatHeatVentStatusRL_IHUB 15 "SNA" 7 "Heat3" 6 "Heat2" 5 "Heat1" 4 "Off" 3 "Vent1" 2 "Vent2" 1 "Vent3" 0 "NoCommand" ;
VAL_ 271 seatHeatVentStatusRR_IHUB 15 "SNA" 7 "Heat3" 6 "Heat2" 5 "Heat1" 4 "Off" 3 "Vent1" 2 "Vent2" 1 "Vent3" 0 "NoCommand" ;
VAL_ 271 screenCommandR_BGW 15 "SNA" 10 "AutoValetDone" 9 "AutoValetProgress" 8 "AutoValetCountdown" 7 "Charging" 6 "Battery" 5 "Welcome" 4 "DisabledNotForCes" 3 "ScanFail" 2 "ScanSuccess" 1 "Scanning" 0 "Off" ;
VAL_ 271 screenCommandL_BGW 15 "SNA" 10 "AutoValetDone" 9 "AutoValetProgress" 8 "AutoValetCountdown" 7 "Charging" 6 "Battery" 5 "Welcome" 4 "DisabledNotForCes" 3 "ScanFail" 2 "ScanSuccess" 1 "Scanning" 0 "Off" ;
VAL_ 271 panelSelectForBrightness_IHUB 7 "SNA" 6 "All" 5 "Pbpc" 4 "Dbpc" 3 "Rrdp" 2 "Rldp" 1 "Pdp" 0 "Ddp" ;
VAL_ 271 nightModeSelect_IHUB 3 "SNA" 1 "True" 0 "False" ;
VAL_ 520 seatPsngrTiltCmd_BGW 3 "SNA" 2 "MoveDown" 1 "MoveUp" 0 "Stop" ;
VAL_ 520 seatPsngrSlideCmd_BGW 3 "SNA" 2 "MoveBackward" 1 "MoveForward" 0 "Stop" ;
VAL_ 520 seatPsngrLiftCmd_BGW 3 "SNA" 2 "MoveDown" 1 "MoveUp" 0 "Stop" ;
VAL_ 520 seatPsngrBackrestCmd_BGW 3 "SNA" 2 "MoveBackward" 1 "MoveForward" 0 "Stop" ;
VAL_ 520 seatDriverTiltCmd_BGW 3 "SNA" 2 "MoveDown" 1 "MoveUp" 0 "Stop" ;
VAL_ 520 seatDriverSlideCmd_BGW 3 "SNA" 2 "MoveBackward" 1 "MoveForward" 0 "Stop" ;
VAL_ 520 seatDriverLiftCmd_BGW 3 "SNA" 2 "MoveDown" 1 "MoveUp" 0 "Stop" ;
VAL_ 520 seatDriverCushionCmd_BGW 3 "SNA" 2 "MoveBackward" 1 "MoveForward" 0 "Stop" ;
VAL_ 520 seatDriverBackrestCmd_BGW 3 "SNA" 2 "MoveBackward" 1 "MoveForward" 0 "Stop" ;
VAL_ 521 seatRearRTiltCmd_BGW 3 "SNA" 2 "MoveDown" 1 "MoveUp" 0 "Stop" ;
VAL_ 521 seatRearRLowerLegExtCmd_BGW 3 "SNA" 2 "MoveBackward" 1 "MoveForward" 0 "Stop" ;
VAL_ 521 seatRearRBackrestCmd_BGW 3 "SNA" 2 "MoveBackward" 1 "MoveForward" 0 "Stop" ;
VAL_ 521 seatRearRLowerLegSupCmd_BGW 3 "SNA" 2 "MoveDown" 1 "MoveUp" 0 "Stop" ;
VAL_ 521 seatRearLTiltCmd_BGW 3 "SNA" 2 "MoveDown" 1 "MoveUp" 0 "Stop" ;
VAL_ 521 seatRearLLowerLegExtCmd_BGW 3 "SNA" 2 "MoveBackward" 1 "MoveForward" 0 "Stop" ;
VAL_ 521 seatRearLBackrestCmd_BGW 3 "SNA" 2 "MoveBackward" 1 "MoveForward" 0 "Stop" ;
VAL_ 521 seatRearLLowerLegSupCmd_BGW 3 "SNA" 2 "MoveDown" 1 "MoveUp" 0 "Stop" ;
VAL_ 522 seatMassgReqOnOffDSM_BGW 1 "On" 0 "Off" ;
VAL_ 522 seatMassgReqMassgSpdLvlDSM_BGW 3 "SNA" 2 "MassgIntenLvlIntenHi" 1 "MassgIntenLvlIntenNorm" 0 "MassgIntenLvlIntenLo" ;
VAL_ 522 seatMassgReqMassgProgDSM_BGW 15 "Test" 14 "JounceDownCush" 13 "JounceDownBack" 12 "JounceDownSeat" 11 "JounceUpCush" 10 "JounceUpBack" 9 "JounceUpSeat" 8 "JounceUpDownCush" 7 "JounceUpDownBack" 6 "JounceUpDownSeat" 5 "RollUpDownCush" 4 "RollUpDownBack" 3 "RollUpDownSeat" 2 "RollUpCush" 1 "RollUpBack" 0 "RollUpSeat" ;
VAL_ 522 seatMassgReqMassgIntenDSM_BGW 3 "SNA" 2 "MassgIntenLvlIntenHi" 1 "MassgIntenLvlIntenNorm" 0 "MassgIntenLvlIntenLo" ;
VAL_ 522 seatIndVlvCtrlDSM_BGW 1 "True" 0 "False" ;
VAL_ 522 seatPmpRunDSM_BGW 1 "True" 0 "False" ;
VAL_ 522 seatShIncDSM_BGW 1 "True" 0 "False" ;
VAL_ 522 seatShDecDSM_BGW 1 "True" 0 "False" ;
VAL_ 522 seatCushIncDSM_BGW 1 "True" 0 "False" ;
VAL_ 522 seatCushDecDSM_BGW 1 "True" 0 "False" ;
VAL_ 522 seatBackSaveSetToMemDSM_BGW 3 "SNA" 2 "Aut" 1 "On" 0 "Off" ;
VAL_ 522 seatBackCtrReqInOutEasyDSM_BGW 1 "On" 0 "Off" ;
VAL_ 522 seatDiAutCorrnDSM_BGW 1 "True" 0 "False" ;
VAL_ 522 seatEmgyStopDSM_BGW 1 "True" 0 "False" ;
VAL_ 522 seatBackPosnStoreDSM_BGW 1 "True" 0 "False" ;
VAL_ 522 seatBackPosnRestoreDSM_BGW 1 "True" 0 "False" ;
VAL_ 522 seatMemSeatCtrlDSM_BGW 3 "MemPosnMemBnk3" 2 "MemPosnMemBnk2" 1 "MemPosnMemBnk1" 0 "MemPosnProfPosn" ;
VAL_ 522 seatLumIncDSM_BGW 1 "True" 0 "False" ;
VAL_ 522 seatLumDecDSM_BGW 1 "True" 0 "False" ;
VAL_ 522 seatLumUpDSM_BGW 1 "True" 0 "False" ;
VAL_ 522 seatLumDwnDSM_BGW 1 "True" 0 "False" ;
VAL_ 522 seatBackBlstrDecDSM_BGW 1 "True" 0 "False" ;
VAL_ 522 seatBackBlstrIncDSM_BGW 1 "True" 0 "False" ;
VAL_ 523 seatShIncPSM_BGW 1 "True" 0 "False" ;
VAL_ 523 seatShDecPSM_BGW 1 "True" 0 "False" ;
VAL_ 523 seatLumUpPSM_BGW 1 "True" 0 "False" ;
VAL_ 523 seatLumIncPSM_BGW 1 "True" 0 "False" ;
VAL_ 523 seatLumDwnPSM_BGW 1 "True" 0 "False" ;
VAL_ 523 seatLumDecPSM_BGW 1 "True" 0 "False" ;
VAL_ 523 seatCushIncPSM_BGW 1 "True" 0 "False" ;
VAL_ 523 seatCushDecPSM_BGW 1 "True" 0 "False" ;
VAL_ 523 seatBackSaveSetToMemPSM_BGW 3 "SNA" 2 "Aut" 1 "On" 0 "Off" ;
VAL_ 523 seatBackPosnStorePSM_BGW 1 "True" 0 "False" ;
VAL_ 523 seatBackPosnRestorePSM_BGW 1 "True" 0 "False" ;
VAL_ 523 seatBackCtrReqInOutEasyPSM_BGW 1 "On" 0 "Off" ;
VAL_ 523 seatBackBlstrIncPSM_BGW 1 "True" 0 "False" ;
VAL_ 523 seatPmpRunPSM_BGW 1 "True" 0 "False" ;
VAL_ 523 seatMemSeatCtrlPSM_BGW 3 "MemPosnMemBnk3" 2 "MemPosnMemBnk2" 1 "MemPosnMemBnk1" 0 "MemPosnProfPosn" ;
VAL_ 523 seatMassgReqOnOffPSM_BGW 1 "On" 0 "Off" ;
VAL_ 523 seatMassgReqMassgSpdLvlPSM_BGW 3 "SNA" 2 "MassgIntenLvlIntenHi" 1 "MassgIntenLvlIntenNorm" 0 "MassgIntenLvlIntenLo" ;
VAL_ 523 seatMassgReqMassgProgPSM_BGW 15 "Test" 14 "JounceDownCush" 13 "JounceDownBack" 12 "JounceDownSeat" 11 "JounceUpCush" 10 "JounceUpBack" 9 "JounceUpSeat" 8 "JounceUpDownCush" 7 "JounceUpDownBack" 6 "JounceUpDownSeat" 5 "RollUpDownCush" 4 "RollUpDownBack" 3 "RollUpDownSeat" 2 "RollUpCush" 1 "RollUpBack" 0 "RollUpSeat" ;
VAL_ 523 seatMassgReqMassgIntenPSM_BGW 3 "SNA" 2 "MassgIntenLvlIntenHi" 1 "MassgIntenLvlIntenNorm" 0 "MassgIntenLvlIntenLo" ;
VAL_ 523 seatIndVlvCtrlPSM_BGW 1 "True" 0 "False" ;
VAL_ 523 seatEmgyStopPSM_BGW 1 "True" 0 "False" ;
VAL_ 523 seatDiAutCorrnPSM_BGW 1 "True" 0 "False" ;
VAL_ 523 seatBackBlstrDecPSM_BGW 1 "True" 0 "False" ;
VAL_ 524 seatRearRBackrestCmdV2_BGW 3 "SNA" 2 "MoveBackward" 1 "MoveForward" 0 "Stop" ;
VAL_ 524 seatRearLBackrestCmdV2_BGW 3 "SNA" 2 "MoveBackward" 1 "MoveForward" 0 "Stop" ;
VAL_ 525 userID_IHUB 255 "SNA" 10 "User10" 9 "User9" 8 "User8" 7 "User7" 6 "User6" 5 "User5" 4 "User4" 3 "Nick" 2 "Sara" 1 "Michael" 0 "NoAuthorizedUser" ;
VAL_ 525 userLocation_IHUB 255 "SNA" 13 "Right" 12 "Left" 11 "Rear" 10 "Front" 9 "RearRightDoor" 8 "RearLeftDoor" 7 "FrontRightDoor" 6 "FrontLeftDoor" 5 "RearMiddleSeat" 4 "RearRightSeat" 3 "RearLeftSeat" 2 "FrontRightSeat" 1 "FrontLeftSeat" 0 "Reserved" ;
VAL_ 526 lightLaneChangeRightOnReq_SDCM 3 "SNA" 2 "TurnLightOn" 1 "TurnLightOff" 0 "NoCommand" ;
VAL_ 526 lightLaneChangeLeftOnReq_SDCM 3 "SNA" 2 "TurnLightOn" 1 "TurnLightOff" 0 "NoCommand" ;
VAL_ 526 mirrorDimmingLvlReq_SDCM 7 "SNA" 5 "Level5" 4 "Level4" 3 "Level3" 2 "Level2" 1 "Level1" 0 "Off" ;
VAL_ 527 nVentPassRear_RCCM 15 "SNA" 8 "NoCommand" 7 "CenterFootDoor" 6 "CenterFoot" 5 "CenterDoor" 4 "Center" 3 "FootDoor" 2 "Foot" 1 "Door" 0 "SystemOff" ;
VAL_ 527 nVentPassFront_RCCM 15 "SNA" 9 "NoCommand" 8 "DefrostVent" 7 "DefrostFoot" 6 "Defrost2" 5 "Defrost1" 4 "TriLevel" 3 "BiLevel" 2 "Foot" 1 "Vent" 0 "SystemOff" ;
VAL_ 527 nVentDriveRear_RCCM 15 "SNA" 8 "NoCommand" 7 "CenterFootDoor" 6 "CenterFoot" 5 "CenterDoor" 4 "Center" 3 "FootDoor" 2 "Foot" 1 "Door" 0 "SystemOff" ;
VAL_ 527 nVentDriveFront_RCCM 15 "SNA" 9 "NoCommand" 8 "DefrostVent" 7 "DefrostFoot" 6 "Defrost2" 5 "Defrost1" 4 "TriLevel" 3 "BiLevel" 2 "Foot" 1 "Vent" 0 "SystemOff" ;
VAL_ 527 nBlowerRearPass_RCCM 15 "SNA" ;
VAL_ 527 nBlowerRearDrive_RCCM 15 "SNA" ;
VAL_ 527 nBlowerFrontPass_RCCM 15 "SNA" ;
VAL_ 527 nBlowerFrontDrive_RCCM 15 "SNA" ;
VAL_ 527 tAirRearPassRequest_RCCM 255 "SNA" ;
VAL_ 527 tAirRearDriveRequest_RCCM 255 "SNA" ;
VAL_ 527 tAirFrontPassRequest_RCCM 255 "SNA" ;
VAL_ 527 tAirFrontDriveRequest_RCCM 255 "SNA" ;
VAL_ 568 stspTe_SCAM 3 "SNA" 1 "True" 0 "False" ;
VAL_ 568 stspTi_SCAM 3 "SNA" 1 "True" 0 "False" ;
VAL_ 568 plsHTe_SCAM 3 "SNA" 1 "True" 0 "False" ;
VAL_ 568 shcHTe_SCAM 3 "SNA" 1 "True" 0 "False" ;
VAL_ 568 drpHTe_SCAM 3 "SNA" 1 "True" 0 "False" ;
VAL_ 568 schMTe_SCAM 3 "SNA" 1 "True" 0 "False" ;
VAL_ 568 drpMTe_SCAM 3 "SNA" 1 "True" 0 "False" ;
VAL_ 568 ovcTe_SCAM 3 "SNA" 1 "True" 0 "False" ;
VAL_ 568 hiTmpTe_SCAM 3 "SNA" 1 "True" 0 "False" ;
VAL_ 568 stallTe_SCAM 3 "SNA" 1 "True" 0 "False" ;
VAL_ 568 plsHTi_SCAM 3 "SNA" 1 "True" 0 "False" ;
VAL_ 568 shcHTi_SCAM 3 "SNA" 1 "True" 0 "False" ;
VAL_ 568 drpHTi_SCAM 3 "SNA" 1 "True" 0 "False" ;
VAL_ 568 shcMTi_SCAM 3 "SNA" 1 "True" 0 "False" ;
VAL_ 568 drpMTi_SCAM 3 "SNA" 1 "True" 0 "False" ;
VAL_ 568 ovcTi_SCAM 3 "SNA" 1 "True" 0 "False" ;
VAL_ 568 hiTmpTi_SCAM 3 "SNA" 1 "True" 0 "False" ;
VAL_ 568 stallTi_SCAM 3 "SNA" 1 "True" 0 "False" ;
VAL_ 568 maxBlNum_SCAM 3 "SNA" 1 "True" 0 "False" ;
VAL_ 568 overVolt_SCAM 3 "SNA" 1 "True" 0 "False" ;
VAL_ 568 lowVolt_SCAM 3 "SNA" 1 "True" 0 "False" ;
VAL_ 568 underVolt_SCAM 3 "SNA" 1 "True" 0 "False" ;
VAL_ 568 comErr_SCAM 3 "SNA" 1 "True" 0 "False" ;
VAL_ 568 intErr_SCAM 3 "SNA" 1 "True" 0 "False" ;
VAL_ 569 dirTele_SCAM 3 "SNA" 2 "MoveForward" 1 "MoveBackward" 0 "NoMovement" ;
VAL_ 569 dirTilt_SCAM 3 "SNA" 2 "MoveUp" 1 "MoveDown" 0 "NoMovement" ;
VAL_ 569 recStat_SCAM 3 "SNA" 2 "RecallCompleted" 1 "RecallInProcess" 0 "NoRecall" ;
VAL_ 569 initStat_SCAM 3 "SNA" 2 "TiltInitialized" 1 "TeleInitialized" 0 "Initialized" ;
VAL_ 608 windowLockState_DCFL 3 "SNA" 2 "Unused" 1 "Locked" 0 "Unlocked" ;
VAL_ 608 doorIsUnlatched_DCFL 3 "SNA" 1 "True" 0 "False" ;
VAL_ 608 doorExtSwitch_DCFL 3 "SNA" 1 "True" 0 "False" ;
VAL_ 608 doorLockReq_DCFL 3 "SNA" 2 "LockRequest" 1 "UnlockRequest" 0 "NoRequest" ;
VAL_ 608 doorMirrorState_DCFL 7 "SNA" 4 "Retracting" 3 "Retracted" 2 "Presenting" 1 "Presented" 0 "Unknown" ;
VAL_ 608 doorState_DCFL 15 "SNA" 9 "DoorUnlatchingError" 8 "DoorClosingError" 7 "DoorOpeningError" 6 "DoorClosingObstruction" 5 "DoorOpeningObstruction" 4 "DoorClosing" 3 "DoorOpening" 2 "DoorUnlatched" 1 "DoorOpen" 0 "DoorClosed" ;
VAL_ 608 mirrorHeaterState_DCFL 3 "SNA" 2 "Fault" 1 "On" 0 "Off" ;
VAL_ 608 sideRepeaterState_DCFL 3 "SNA" 2 "LightFault" 1 "LightOn" 0 "LightOff" ;
VAL_ 608 windowStatusFl_DCFL 7 "SNA" 4 "Error" 3 "WindowRollingDown" 2 "WindowRollingUp" 1 "WindowOpen" 0 "WindowClosed" ;
VAL_ 608 mirrorFoldFeedbackLeft_DCFL 3 "SNA" 2 "FoldIn" 1 "FoldOut" 0 "NoCommand" ;
VAL_ 608 mirrorDefrostGlassStatusLh_DCFL 3 "SNA" 2 "Error" 1 "On" 0 "Off" ;
VAL_ 608 mirrorStatusMovUpDownLeft_DCFL 3 "SNA" 2 "MovingDown" 1 "MovingUp" 0 "NotMoving" ;
VAL_ 608 mirrorStatusMovInOutLeft_DCFL 3 "SNA" 2 "MovingOut" 1 "MovingIn" 0 "NotMoving" ;
VAL_ 608 mirrorDefrostCamStatusLeft_DCFL 3 "SNA" 2 "Error" 1 "On" 0 "Off" ;
VAL_ 608 mirrorFoldAutoStatusLeft_DCFL 3 "SNA" 2 "Error" 1 "On" 0 "Off" ;
VAL_ 608 mirrorDimEnabDisableStatus_DCFL 3 "SNA" 2 "Error" 1 "On" 0 "Off" ;
VAL_ 609 windowReqRearLeft_DCFL 7 "SNA" 6 "AutoUp" 5 "AutoDown" 2 "PropUp" 1 "PropDown" 0 "NoCommand" ;
VAL_ 609 windowReqRearRight_DCFL 7 "SNA" 6 "AutoUp" 5 "AutoDown" 2 "PropUp" 1 "PropDown" 0 "NoCommand" ;
VAL_ 609 windowReqFrontLeft_DCFL 7 "SNA" 6 "AutoUp" 5 "AutoDown" 2 "PropUp" 1 "PropDown" 0 "NoCommand" ;
VAL_ 609 windowReqFrontRight_DCFL 7 "SNA" 6 "AutoUp" 5 "AutoDown" 2 "PropUp" 1 "PropDown" 0 "NoCommand" ;
VAL_ 609 doorMirrorFoldCmd_DCFL 3 "SNA" 2 "FoldIn" 1 "FoldOut" 0 "NoCommand" ;
VAL_ 609 doorExtDriverRearRelease_DCFL 3 "SNA" 2 "Fault" 1 "Pressed" 0 "Unpressed" ;
VAL_ 609 doorIntDriverRearRelease_DCFL 3 "SNA" 2 "Fault" 1 "Pressed" 0 "Unpressed" ;
VAL_ 609 doorDriverFrontPresentReq_DCFL 3 "SNA" 2 "Fault" 1 "Pressed" 0 "Unpressed" ;
VAL_ 264 mirrorDimEnableDisableReq_IHUB 3 "SNA" 1 "Enable" 0 "Disable" ;
VAL_ 264 defrostMirrorGlassReq_IHUB 3 "SNA" 1 "True" 0 "False" ;
VAL_ 264 mirrorFoldInOutReq_IHUB 3 "SNA" 2 "FoldIn" 1 "FoldOut" 0 "NoCommand" ;
VAL_ 264 mirrorPowerFoldAutoOnOff_IHUB 3 "SNA" 1 "On" 0 "Off" ;
VAL_ 264 mirrorDefrostCameraOnReq_IHUB 3 "SNA" 1 "On" 0 "Off" ;
VAL_ 264 mirrorTiltRelInOutLeft_IHUB 7 "SNA" 3 "AbsolutePosition" 2 "TiltOut" 1 "TiltIn" 0 "NoCommand" ;
VAL_ 264 mirrorTiltRelUpDownLeft_IHUB 7 "SNA" 3 "AbsolutePosition" 2 "TiltDown" 1 "TiltUp" 0 "NoCommand" ;
VAL_ 264 mirrorTiltRelInOutRight_IHUB 7 "SNA" 3 "AbsolutePosition" 2 "TiltOut" 1 "TiltIn" 0 "NoCommand" ;
VAL_ 264 mirrorTiltRelUpDownRight_IHUB 7 "SNA" 3 "AbsolutePosition" 2 "TiltDown" 1 "TiltUp" 0 "NoCommand" ;
VAL_ 628 seatFrontLeftOccupied_DSM 3 "SNA" 1 "True" 0 "False" ;
VAL_ 628 seatMovementTilt_DSM 7 "SNA" 3 "Success" 2 "NotSuccess" 1 "InProgress" 0 "NotActive" ;
VAL_ 628 seatMovementSlide_DSM 7 "SNA" 3 "Success" 2 "NotSuccess" 1 "InProgress" 0 "NotActive" ;
VAL_ 628 seatMovementLift_DSM 7 "SNA" 3 "Success" 2 "NotSuccess" 1 "InProgress" 0 "NotActive" ;
VAL_ 628 seatMovementCushion_DSM 7 "SNA" 3 "Success" 2 "NotSuccess" 1 "InProgress" 0 "NotActive" ;
VAL_ 628 seatMovementBackrest_DSM 7 "SNA" 3 "Success" 2 "NotSuccess" 1 "InProgress" 0 "NotActive" ;
VAL_ 628 seatInitStatus_DSM 3 "SNA" 1 "InitStatusFault" 0 "InitStatusNoFault" ;
VAL_ 628 seatVBatPowerStatus_DSM 3 "SNA" 1 "VbatMotorFault" 0 "VbatMotorNoFault" ;
VAL_ 628 seatVBatEleStatus_DSM 3 "SNA" 1 "VbatComfortFault" 0 "VbatComfortNoFault" ;
VAL_ 628 seatFaultStatus_DSM 3 "SNA" 2 "FaultStatusFaultFailure" 1 "FaultStatusFaultWarning" 0 "FaultStatusNoFault" ;
VAL_ 628 seatAntiPanicStatus_DSM 3 "SNA" 2 "AntiPanicStatusUnused" 1 "AntiPanicStatusActive" 0 "AntiPanicStatusInactive" ;
VAL_ 648 windowLockState_DCFR 3 "SNA" 2 "Unused" 1 "Locked" 0 "Unlocked" ;
VAL_ 648 doorIsUnlatched_DCFR 3 "SNA" 1 "True" 0 "False" ;
VAL_ 648 doorExtSwitch_DCFR 3 "SNA" 1 "True" 0 "False" ;
VAL_ 648 doorLockReq_DCFR 3 "SNA" 2 "LockRequest" 1 "UnlockRequest" 0 "NoRequest" ;
VAL_ 648 doorMirrorState_DCFR 7 "SNA" 4 "Retracting" 3 "Retracted" 2 "Presenting" 1 "Presented" 0 "Unknown" ;
VAL_ 648 doorState_DCFR 15 "SNA" 9 "DoorUnlatchingError" 8 "DoorClosingError" 7 "DoorOpeningError" 6 "DoorClosingObstruction" 5 "DoorOpeningObstruction" 4 "DoorClosing" 3 "DoorOpening" 2 "DoorUnlatched" 1 "DoorOpen" 0 "DoorClosed" ;
VAL_ 648 mirrorHeaterState_DCFR 3 "SNA" 2 "Fault" 1 "On" 0 "Off" ;
VAL_ 648 sideRepeaterState_DCFR 3 "SNA" 2 "LightFault" 1 "LightOn" 0 "LightOff" ;
VAL_ 648 windowStatusFr_DCFR 7 "SNA" 4 "Error" 3 "WindowRollingDown" 2 "WindowRollingUp" 1 "WindowOpen" 0 "WindowClosed" ;
VAL_ 648 mirrorFoldFeedbackRight_DCFR 3 "SNA" 2 "FoldIn" 1 "FoldOut" 0 "NoCommand" ;
VAL_ 648 mirrorDefrostGlassStatusRh_DCFR 3 "SNA" 2 "Error" 1 "On" 0 "Off" ;
VAL_ 648 mirrorStatusMovUpDownRight_DCFR 3 "SNA" 2 "MovingDown" 1 "MovingUp" 0 "NotMoving" ;
VAL_ 648 mirrorStatusMovInOutRight_DCFR 3 "SNA" 2 "MovingOut" 1 "MovingIn" 0 "NotMoving" ;
VAL_ 648 mirrorDefrostCamStatusRight_DCFR 3 "SNA" 2 "Error" 1 "On" 0 "Off" ;
VAL_ 648 mirrorFoldAutoStatusRight_DCFR 3 "SNA" 2 "Error" 1 "On" 0 "Off" ;
VAL_ 648 mirrorDimEnabDisableStatus_DCFR 3 "SNA" 2 "Error" 1 "On" 0 "Off" ;
VAL_ 649 windowReqRearLeft_DCFR 7 "SNA" 6 "AutoUp" 5 "AutoDown" 2 "PropUp" 1 "PropDown" 0 "NoCommand" ;
VAL_ 649 windowReqRearRight_DCFR 7 "SNA" 6 "AutoUp" 5 "AutoDown" 2 "PropUp" 1 "PropDown" 0 "NoCommand" ;
VAL_ 649 windowReqFrontLeft_DCFR 7 "SNA" 6 "AutoUp" 5 "AutoDown" 2 "PropUp" 1 "PropDown" 0 "NoCommand" ;
VAL_ 649 windowReqFrontRight_DCFR 7 "SNA" 6 "AutoUp" 5 "AutoDown" 2 "PropUp" 1 "PropDown" 0 "NoCommand" ;
VAL_ 649 extPassRearRelease_DCFR 3 "SNA" 2 "Fault" 1 "Pressed" 0 "Unpressed" ;
VAL_ 649 intPassRearRelease_DCFR 3 "SNA" 2 "Fault" 1 "Pressed" 0 "Unpressed" ;
VAL_ 649 frontRightPresentReq_DCFR 3 "SNA" 2 "Fault" 1 "Pressed" 0 "Unpressed" ;
VAL_ 649 rearRightPresentReq_DCFR 3 "SNA" 2 "Fault" 1 "Pressed" 0 "Unpressed" ;
VAL_ 660 seatFrontRightOccupied_PSM 3 "SNA" 1 "True" 0 "False" ;
VAL_ 660 seatMovementTilt_PSM 7 "SNA" 3 "Success" 2 "NotSuccess" 1 "InProgress" 0 "NotActive" ;
VAL_ 660 seatMovementSlide_PSM 7 "SNA" 3 "Success" 2 "NotSuccess" 1 "InProgress" 0 "NotActive" ;
VAL_ 660 seatMovementLift_PSM 7 "SNA" 3 "Success" 2 "NotSuccess" 1 "InProgress" 0 "NotActive" ;
VAL_ 660 seatMovementBackrest_PSM 7 "SNA" 3 "Success" 2 "NotSuccess" 1 "InProgress" 0 "NotActive" ;
VAL_ 660 seatInitStatus_PSM 3 "SNA" 1 "InitStatusFault" 0 "InitStatusNoFault" ;
VAL_ 660 seatVBatPowerStatus_PSM 3 "SNA" 1 "VbatMotorFault" 0 "VbatMotorNoFault" ;
VAL_ 660 seatVBatEleStatus_PSM 3 "SNA" 1 "VbatComfortFault" 0 "VbatComfortNoFault" ;
VAL_ 660 seatFaultStatus_PSM 3 "SNA" 2 "FaultStatusFaultFailure" 1 "FaultStatusFaultWarning" 0 "FaultStatusNoFault" ;
VAL_ 660 seatAntiPanicStatus_PSM 3 "SNA" 2 "AntiPanicStatusUnused" 1 "AntiPanicStatusActive" 0 "AntiPanicStatusInactive" ;
VAL_ 692 seatRearLeftOccupied_RLSM 3 "SNA" 1 "True" 0 "False" ;
VAL_ 692 seatMovementTilt_RLSM 7 "SNA" 3 "Success" 2 "NotSuccess" 1 "InProgress" 0 "NotActive" ;
VAL_ 692 seatMovementLowerLegSupp_RLSM 7 "SNA" 3 "Success" 2 "NotSuccess" 1 "InProgress" 0 "NotActive" ;
VAL_ 692 seatMovementLowerLegExt_RLSM 7 "SNA" 3 "Success" 2 "NotSuccess" 1 "InProgress" 0 "NotActive" ;
VAL_ 692 seatMovementBackrest_RLSM 7 "SNA" 3 "Success" 2 "NotSuccess" 1 "InProgress" 0 "NotActive" ;
VAL_ 692 seatInitStatus_RLSM 3 "SNA" 1 "InitStatusFault" 0 "InitStatusNoFault" ;
VAL_ 692 seatVBatPowerStatus_RLSM 3 "SNA" 1 "VbatMotorFault" 0 "VbatMotorNoFault" ;
VAL_ 692 seatVBatEleStatus_RLSM 3 "SNA" 1 "VbatComfortFault" 0 "VbatComfortNoFault" ;
VAL_ 692 seatFaultStatus_RLSM 3 "SNA" 2 "FaultStatusFaultFailure" 1 "FaultStatusFaultWarning" 0 "FaultStatusNoFault" ;
VAL_ 692 seatAntiPanicStatus_RLSM 3 "SNA" 2 "AntiPanicStatusUnused" 1 "AntiPanicStatusActive" 0 "AntiPanicStatusInactive" ;
VAL_ 693 seatRearLeftOccupiedV2_RLSM 3 "SNA" 1 "True" 0 "False" ;
VAL_ 693 seatMovementBackrestV2_RLSM 7 "SNA" 3 "Success" 2 "NotSuccess" 1 "InProgress" 0 "NotActive" ;
VAL_ 693 seatInitStatusV2_RLSM 3 "SNA" 1 "InitStatusFault" 0 "InitStatusNoFault" ;
VAL_ 693 seatVBatEleStatusV2_RLSM 3 "SNA" 1 "VbatComfortFault" 0 "VbatComfortNoFault" ;
VAL_ 693 seatFaultStatusV2_RLSM 3 "SNA" 2 "FaultStatusFaultFailure" 1 "FaultStatusFaultWarning" 0 "FaultStatusNoFault" ;
VAL_ 693 seatAntiPanicStatusV2_RLSM 3 "SNA" 2 "AntiPanicStatusUnused" 1 "AntiPanicStatusActive" 0 "AntiPanicStatusInactive" ;
VAL_ 724 seatRearRightOccupied_RRSM 3 "SNA" 1 "True" 0 "False" ;
VAL_ 724 seatMovementTilt_RRSM 7 "SNA" 3 "Success" 2 "NotSuccess" 1 "InProgress" 0 "NotActive" ;
VAL_ 724 seatMovementLowerLegSupp_RRSM 7 "SNA" 3 "Success" 2 "NotSuccess" 1 "InProgress" 0 "NotActive" ;
VAL_ 724 seatMovementLowerLegExt_RRSM 7 "SNA" 3 "Success" 2 "NotSuccess" 1 "InProgress" 0 "NotActive" ;
VAL_ 724 seatMovementBackrest_RRSM 7 "SNA" 3 "Success" 2 "NotSuccess" 1 "InProgress" 0 "NotActive" ;
VAL_ 724 seatInitStatus_RRSM 3 "SNA" 1 "InitStatusFault" 0 "InitStatusNoFault" ;
VAL_ 724 seatVBatPowerStatus_RRSM 3 "SNA" 1 "VbatMotorFault" 0 "VbatMotorNoFault" ;
VAL_ 724 seatVBatEleStatus_RRSM 3 "SNA" 1 "VbatComfortFault" 0 "VbatComfortNoFault" ;
VAL_ 724 seatFaultStatus_RRSM 3 "SNA" 2 "FaultStatusFaultFailure" 1 "FaultStatusFaultWarning" 0 "FaultStatusNoFault" ;
VAL_ 724 seatAntiPanicStatus_RRSM 3 "SNA" 2 "AntiPanicStatusUnused" 1 "AntiPanicStatusActive" 0 "AntiPanicStatusInactive" ;
VAL_ 725 seatRearRightOccupiedV2_RRSM 3 "SNA" 1 "True" 0 "False" ;
VAL_ 725 seatMovementBackrestV2_RRSM 7 "SNA" 3 "Success" 2 "NotSuccess" 1 "InProgress" 0 "NotActive" ;
VAL_ 725 seatInitStatusV2_RRSM 3 "SNA" 1 "InitStatusFault" 0 "InitStatusNoFault" ;
VAL_ 725 seatVBatEleStatusV2_RRSM 3 "SNA" 1 "VbatComfortFault" 0 "VbatComfortNoFault" ;
VAL_ 725 seatFaultStatusV2_RRSM 3 "SNA" 2 "FaultStatusFaultFailure" 1 "FaultStatusFaultWarning" 0 "FaultStatusNoFault" ;
VAL_ 725 seatAntiPanicStatusV2_RRSM 3 "SNA" 2 "AntiPanicStatusUnused" 1 "AntiPanicStatusActive" 0 "AntiPanicStatusInactive" ;
VAL_ 728 connectionState1_BLE 3 "SNA" 1 "True" 0 "False" ;
VAL_ 729 zoneStatus_BLE 15 "SNA" 14 "Reserved6" 13 "Reserved5" 12 "InsideUnknown" 11 "InsideRearRightSeat" 10 "InsideRearLeftSeat" 9 "InsidePassengerSeat" 8 "InsideDriverSeat" 7 "Reserved4" 6 "Reserved3" 5 "Reserved2" 4 "Reserved1" 3 "OutsideNearPassengerSideDoor" 2 "OutsideNearDriverSideDoor" 1 "OutsideWakeup" 0 "OutsideFar" ;
VAL_ 776 sequenceIdInterior_BGW 255 "SNA" 50 "Spa2" 49 "Spa1" 48 "SpaAwake" 47 "Hazard" 46 "WalkAround" 45 "FollowHome" 44 "HappyDog" 43 "Awake" 42 "ChargingInterrupt" 41 "ChargingCompleted" 40 "ChargingUnplugged" 39 "ChargingInProgress" 38 "ChargerReady" 37 "WifiHotspot" 36 "ParkedOnStage" 35 "TheUnveil" 34 "ObstructionPassengerRear" 33 "ObstructionPassengerFront" 32 "ObstructionDriverRear" 31 "ObstructionDriverFront" 30 "ClosedPassengerRear" 29 "ClosedPassengerFront" 28 "ClosedDriverRear" 27 "ClosedDriverFront" 26 "ClosingPassengerRear" 25 "ClosingPassengerFront" 24 "ClosingDriverRear" 23 "ClosingDriverFront" 22 "OpenPassengerRear" 21 "OpenPassengerFront" 20 "OpenDriverRear" 19 "OpenDriverFront" 18 "AutoValetParked" 17 "AutoValetParking" 16 "AutoValetCountDown" 15 "TurnLeft" 14 "TurnRight" 13 "AutonomousMode" 12 "ParkMode" 11 "DriveMode" 10 "Test10" 9 "Test9" 8 "Test8" 7 "Test7" 6 "Test6" 5 "Test5" 4 "Test4" 3 "Test3" 2 "Test2" 1 "Test1" 0 "Null" ;
VAL_ 777 nAirConditionRR_IHUB 3 "SNA" 2 "AcEnabled" 1 "BlowerEnabled" 0 "SystemOff" ;
VAL_ 777 nAirConditionRL_IHUB 3 "SNA" 2 "AcEnabled" 1 "BlowerEnabled" 0 "SystemOff" ;
VAL_ 777 nAirConditionFR_IHUB 3 "SNA" 2 "AcEnabled" 1 "BlowerEnabled" 0 "SystemOff" ;
VAL_ 777 nAirConditionFL_IHUB 3 "SNA" 2 "AcEnabled" 1 "BlowerEnabled" 0 "SystemOff" ;
VAL_ 777 doorPanelHvacDisableRR_IHUB 3 "SNA" 1 "True" 0 "False" ;
VAL_ 777 doorPanelHvacDisableRL_IHUB 3 "SNA" 1 "True" 0 "False" ;
VAL_ 777 doorPanelHvacDisableFR_IHUB 3 "SNA" 1 "True" 0 "False" ;
VAL_ 777 doorPanelHvacDisableFL_IHUB 3 "SNA" 1 "True" 0 "False" ;
VAL_ 777 doorPanelAudioDisableRR_IHUB 3 "SNA" 1 "True" 0 "False" ;
VAL_ 777 doorPanelAudioDisableRL_IHUB 3 "SNA" 1 "True" 0 "False" ;
VAL_ 777 doorPanelAudioDisableFR_IHUB 3 "SNA" 1 "True" 0 "False" ;
VAL_ 777 doorPanelAudioDisableFL_IHUB 3 "SNA" 1 "True" 0 "False" ;
VAL_ 777 volumeStatusFL_IHUB 63 "SNA" ;
VAL_ 777 volumeStatusFR_IHUB 63 "SNA" ;
VAL_ 777 volumeStatusRL_IHUB 63 "SNA" ;
VAL_ 777 volumeStatusRR_IHUB 63 "SNA" ;
VAL_ 777 muteStatusFL_IHUB 3 "SNA" 2 "Disabled" 1 "True" 0 "False" ;
VAL_ 777 muteStatusFR_IHUB 3 "SNA" 2 "Disabled" 1 "True" 0 "False" ;
VAL_ 777 muteStatusRL_IHUB 3 "SNA" 2 "Disabled" 1 "True" 0 "False" ;
VAL_ 777 muteStatusRR_IHUB 3 "SNA" 2 "Disabled" 1 "True" 0 "False" ;
VAL_ 777 seatRelaxedStatusFL_IHUB 3 "SNA" 2 "Transitioning" 1 "True" 0 "False" ;
VAL_ 777 seatRelaxedStatusFR_IHUB 3 "SNA" 2 "Transitioning" 1 "True" 0 "False" ;
VAL_ 777 seatRelaxedStatusRL_IHUB 3 "SNA" 2 "Transitioning" 1 "True" 0 "False" ;
VAL_ 777 seatRelaxedStatusRR_IHUB 3 "SNA" 2 "Transitioning" 1 "True" 0 "False" ;
VAL_ 779 sequenceId_IHUB 255 "SNA" 47 "Hazard" 46 "WalkAround" 45 "FollowHome" 44 "HappyDog" 43 "Awake" 42 "ChargingInterrupt" 41 "ChargingCompleted" 40 "ChargingUnplugged" 39 "ChargingInProgress" 38 "ChargerReady" 37 "WifiHotspot" 36 "ParkedOnStage" 35 "TheUnveil" 34 "ObstructionPassengerRear" 33 "ObstructionPassengerFront" 32 "ObstructionDriverRear" 31 "ObstructionDriverFront" 30 "ClosedPassengerRear" 29 "ClosedPassengerFront" 28 "ClosedDriverRear" 27 "ClosedDriverFront" 26 "ClosingPassengerRear" 25 "ClosingPassengerFront" 24 "ClosingDriverRear" 23 "ClosingDriverFront" 22 "OpenPassengerRear" 21 "OpenPassengerFront" 20 "OpenDriverRear" 19 "OpenDriverFront" 18 "AutoValetParked" 17 "AutoValetParking" 16 "AutoValetCountDown" 15 "Neutral" 14 "Reverse" 13 "Autonomous" 12 "Park" 11 "Drive" 10 "Test10" 9 "Test9" 8 "Test8" 7 "Test7" 6 "Test6" 5 "Test5" 4 "Test4" 3 "Test3" 2 "Test2" 1 "Test1" 0 "Null" ;
VAL_ 1032 chargeMode_BGW 3 "SNA" 1 "True" 0 "False" ;
VAL_ 1032 accessoryMode_BGW 3 "SNA" 2 "Reserved" 1 "LowAndHighVoltage" 0 "False" ;
VAL_ 1032 remoteMode_BGW 3 "SNA" 2 "Reserved" 1 "LowAndHighVoltage" 0 "False" ;
VAL_ 1032 driveMode_BGW 3 "SNA" 2 "Moving" 1 "Run" 0 "False" ;
VAL_ 1032 wiperCmd_BGW 15 "SNA" 9 "IntermittentMode1" 8 "IntermittentMode2" 7 "IntermittentMode3" 6 "IntermittentMode4" 5 "IntermittentMode5" 4 "ServicePosition" 3 "HighWipes" 2 "LowWipes" 1 "Park" 0 "NoWipe" ;
VAL_ 1032 chassisWakeup_BGW 3 "SNA" 1 "True" 0 "False" ;
VAL_ 1032 driveRequestState_BGW 3 "SNA" 1 "True" 0 "False" ;
VAL_ 1032 accessoryRequestState_BGW 3 "SNA" 1 "True" 0 "False" ;
VAL_ 1032 selfDriveRequestState_BGW 3 "SNA" 1 "True" 0 "False" ;
VAL_ 1032 hornOnReq_BGW 3 "SNA" 1 "True" 0 "False" ;
VAL_ 1032 wiperNozzleDefrostReq_BGW 3 "SNA" 1 "True" 0 "False" ;
VAL_ 1033 exteriorLightReq_IHUB 7 "SNA" 4 "Auto" 3 "HighBeam" 2 "LowBeam" 1 "Parking" 0 "Off" ;
VAL_ 1033 rearSeatDisplayUpDownReq_IHUB 3 "SNA" 1 "UnfoldDown" 0 "FoldUp" ;
VAL_ 1033 frunkLockReq_IHUB 3 "SNA" 2 "NoChange" 1 "Unlock" 0 "Lock" ;
VAL_ 1033 liftgateLockReq_IHUB 3 "SNA" 2 "NoChange" 1 "Unlock" 0 "Lock" ;
VAL_ 1033 doorRRLockReq_IHUB 3 "SNA" 2 "NoChange" 1 "Unlock" 0 "Lock" ;
VAL_ 1033 doorRLLockReq_IHUB 3 "SNA" 2 "NoChange" 1 "Unlock" 0 "Lock" ;
VAL_ 1033 doorFRLockReq_IHUB 3 "SNA" 2 "NoChange" 1 "Unlock" 0 "Lock" ;
VAL_ 1033 doorFLLockReq_IHUB 3 "SNA" 2 "NoChange" 1 "Unlock" 0 "Lock" ;
VAL_ 1033 doorRearRightOperation_IHUB 15 "SNA" 7 "PopDoor" 4 "DoorClose" 3 "DoorOpen" 0 "NoAction" ;
VAL_ 1033 doorRearLeftOperation_IHUB 15 "SNA" 7 "PopDoor" 4 "DoorClose" 3 "DoorOpen" 0 "NoAction" ;
VAL_ 1033 doorFrontRightOperation_IHUB 15 "SNA" 7 "PopDoor" 4 "DoorClose" 3 "DoorOpen" 0 "NoAction" ;
VAL_ 1033 doorFrontLeftOperation_IHUB 15 "SNA" 7 "PopDoor" 4 "DoorClose" 3 "DoorOpen" 0 "NoAction" ;
VAL_ 1033 lightLowBeamOnReq_IHUB 3 "SNA" 1 "TurnLightOn" 0 "TurnLightOff" ;
VAL_ 1033 frontHoodOpen_IHUB 3 "SNA" 2 "Open" 1 "Close" 0 "NoAction" ;
VAL_ 1033 liftgateOperation_IHUB 3 "SNA" 2 "Open" 1 "Close" 0 "NoAction" ;
VAL_ 1033 fogSwitchRear_IHUB 3 "SNA" 1 "TurnLightOn" 0 "TurnLightOff" ;
VAL_ 1033 fogSwitchFront_IHUB 3 "SNA" 1 "TurnLightOn" 0 "TurnLightOff" ;
VAL_ 1034 seatToCalib_TOOL 15 "SNA" 6 "RearLeftV2" 5 "RearRightV2" 4 "RearLeft" 3 "RearRight" 2 "FrontRight" 1 "FrontLeft" 0 "NoSeat" ;
VAL_ 1034 seatCalibInstruct_TOOL 7 "SNA" 3 "ContCalib" 2 "StopCalib" 1 "StartCalib" 0 "NoInstruct" ;
VAL_ 1035 lightFogRearStatus_BGW 3 "SNA" 2 "LightFault" 1 "LightOn" 0 "LightOff" ;
VAL_ 1035 debugEthernetNetworkErrors_BGW 255 "SNA" 39 "NetIpv4ErrAddrCfgInProgress" 38 "NetIpv4ErrAddrNoneAvail" 37 "NetConnErrAddrInUse" 36 "NetConnErrAddrNotUsed" 35 "NetConnErrInvalidAddrLen" 34 "NetConnErrInvalidProtocolix" 33 "NetConnErrInvalidType" 32 "NetConnErrInvalidFamily" 31 "NetConnErrInvalidConn" 30 "NetConnErrNotUsed" 29 "NetConnErrNoneAvail" 28 "NetSockErrTxqClosed" 27 "NetSockErrAddrInUse" 26 "NetSockErrPortNbrNoneAvail" 25 "NetSockErrInvalidPortNbr" 24 "NetSockErrInvalidAddrLen" 23 "NetSockErrInvalidAddr" 22 "NetSockErrInvalidConn" 21 "NetSockErrInvalidDataSize" 20 "NetSockErrInvalidFlag" 19 "NetSockErrInvalidOp" 18 "NetSockErrInvalidState" 17 "NetSockErrInvalidType" 16 "NetSockErrInvalidProtocol" 15 "NetSockErrInvalidFamily" 14 "NetSockErrInvalidSock" 13 "NetSockErrConnFail" 12 "NetSockErrFault" 11 "NetSockErrClosed" 10 "NetSockErrNotUsed" 9 "NetInitErrNotCompleted" 8 "NetIfErrorInvalidIf" 7 "NetErrFaultLockAcquire" 6 "NetErrFaultNullFnct" 5 "NetErrRx" 4 "NetErrTx" 3 "NetErrIfLinkDown" 2 "NetSecureErrNullPtr" 1 "NetIfErrInvalidIf" 0 "NetErrorNone" ;
VAL_ 1035 state_BGW 7 "SNA" 5 "EndDriveState" 4 "ExitingDriveState" 3 "DriveState" 2 "DriveAuthorizedState" 1 "DriveLikelyState" 0 "IdleState" ;
VAL_ 1035 doorRLLockStatus_BGW 3 "SNA" 2 "NoChange" 1 "Unlock" 0 "Lock" ;
VAL_ 1035 liftgateLockStatus_BGW 3 "SNA" 2 "NoChange" 1 "Unlock" 0 "Lock" ;
VAL_ 1035 doorRRLockStatus_BGW 3 "SNA" 2 "NoChange" 1 "Unlock" 0 "Lock" ;
VAL_ 1035 doorFRLockStatus_BGW 3 "SNA" 2 "NoChange" 1 "Unlock" 0 "Lock" ;
VAL_ 1035 doorFLLockStatus_BGW 3 "SNA" 2 "NoChange" 1 "Unlock" 0 "Lock" ;
VAL_ 1036 daytimeRunningLampsOnRequest_BGW 3 "SNA" 1 "DlrOn" 0 "DlrOff" ;
VAL_ 1036 timedWiperModeOn_BGW 3 "SNA" 1 "Timed" 0 "Auto" ;
VAL_ 1036 mirrorDipOnReverse_BGW 3 "SNA" 2 "PassengerOnly" 1 "Both" 0 "Off" ;
VAL_ 1037 lightLowBeamOnReq_BGW 3 "SNA" 1 "TurnLightOn" 0 "TurnLightOff" ;
VAL_ 1037 lightDomeOnReq_BGW 3 "SNA" 1 "TurnLightOn" 0 "TurnLightOff" ;
VAL_ 1037 lightTurnSigRightOnReq_BGW 3 "SNA" 1 "TurnLightOn" 0 "TurnLightOff" ;
VAL_ 1037 lightTurnSigLeftOnReq_BGW 3 "SNA" 1 "TurnLightOn" 0 "TurnLightOff" ;
VAL_ 1037 lightHighBeamOnReq_BGW 3 "SNA" 1 "TurnLightOn" 0 "TurnLightOff" ;
VAL_ 1037 lightHazardOnReq_BGW 3 "SNA" 1 "TurnLightOn" 0 "TurnLightOff" ;
VAL_ 1038 steerCtrTele_IHUB 3 "SNA" 2 "MoveForward" 1 "MoveBackward" 0 "NoMovement" ;
VAL_ 1038 steerCtrTilt_IHUB 3 "SNA" 2 "MoveUp" 1 "MoveDown" 0 "NoMovement" ;
VAL_ 1038 steerMemStrRec_IHUB 15 "SNA" 14 "Spare4" 13 "Spare3" 12 "Spare2" 11 "Spare1" 10 "EasyEntry" 9 "StopAllMovement" 8 "RecallMenu4" 7 "RecallMenu3" 6 "RecallMenu2" 5 "RecallMenu1" 4 "StoreMenu4" 3 "StoreMenu3" 2 "StoreMenu2" 1 "StoreMenu1" 0 "NoOperationRequired" ;
VAL_ 1039 nAirConditionActualRR_BPG 3 "SNA" 2 "Heating" 1 "Cooling" 0 "Off" ;
VAL_ 1039 nAirConditionActualRL_BPG 3 "SNA" 2 "Heating" 1 "Cooling" 0 "Off" ;
VAL_ 1039 nAirConditionActualFR_BPG 3 "SNA" 2 "Heating" 1 "Cooling" 0 "Off" ;
VAL_ 1039 nAirConditionActualFL_BPG 3 "SNA" 2 "Heating" 1 "Cooling" 0 "Off" ;
VAL_ 1039 lightStopOnReq_PTC 3 "SNA" 1 "True" 0 "False" ;
VAL_ 1039 batterySOC_BPG 255 "SNA" ;
VAL_ 1039 lowVoltagePowerMode_ABM 7 "SNA" 3 "Disconnected" 2 "ExtremelyLimited" 1 "Limited" 0 "LvAvailable" ;
VAL_ 1041 lightDRLOnReq_FBCM 3 "SNA" 2 "LightFault" 1 "LightOn" 0 "LightOff" ;
VAL_ 1041 lightSync_FBCM 3 "SNA" 2 "LampOff" 1 "LampOn" 0 "NoEffect" ;
VAL_ 1041 lightHighBeamOnReq_FBCM 3 "SNA" 2 "LightFault" 1 "LightOn" 0 "LightOff" ;
VAL_ 1041 lightTurnRightOnReq_FBCM 3 "SNA" 2 "LightFault" 1 "LightOn" 0 "LightOff" ;
VAL_ 1041 lightTurnLeftOnReq_FBCM 3 "SNA" 2 "LightFault" 1 "LightOn" 0 "LightOff" ;
VAL_ 1041 lightLowBeamOnReq_FBCM 3 "SNA" 2 "LightFault" 1 "LightOn" 0 "LightOff" ;
VAL_ 1041 lightHazardActive_FBCM 3 "SNA" 2 "LightFault" 1 "LightOn" 0 "LightOff" ;
VAL_ 1041 lightStopOnReq_FBCM 3 "SNA" 2 "LightFault" 1 "LightOn" 0 "LightOff" ;
VAL_ 1043 turnSigLh_SCCM 1 "On" 0 "Off" ;
VAL_ 1043 turnSigRh_SCCM 1 "On" 0 "Off" ;
VAL_ 1043 laneChangeLh_SCCM 1 "On" 0 "Off" ;
VAL_ 1043 laneChangeRh_SCCM 1 "On" 0 "Off" ;
VAL_ 1045 chargePortDoorStatus_FBCM 7 "SNA" 4 "DoorObstructed" 3 "DoorClosing" 2 "DoorOpen" 1 "DoorOpening" 0 "DoorClosed" ;
VAL_ 1045 lightHazardStatus_FBCM 3 "SNA" 1 "On" 0 "Off" ;
VAL_ 1045 lightFogFrontStatus_FBCM 3 "SNA" 2 "LightFault" 1 "LightOn" 0 "LightOff" ;
VAL_ 1045 lightDomeStatus_FBCM 3 "SNA" 2 "LightFault" 1 "LightOn" 0 "LightOff" ;
VAL_ 1045 brakeFluidLevel_FBCM 3 "SNA" 1 "Low" 0 "Off" ;
VAL_ 1045 lightFogFrontRightStatus_FBCM 3 "SNA" 2 "LightFault" 1 "LightOn" 0 "LightOff" ;
VAL_ 1045 lightFogFrontLeftStatus_FBCM 3 "SNA" 2 "LightFault" 1 "LightOn" 0 "LightOff" ;
VAL_ 1045 wiperStatus_LWMM 15 "SNA" 10 "IntermittentMode1" 9 "IntermittentMode2" 8 "IntermittentMode3" 7 "IntermittentMode4" 6 "IntermittentMode5" 5 "ServicePosition" 4 "HighWipes" 3 "LowWipes" 2 "Parked" 1 "Parking" 0 "NoWipe" ;
VAL_ 1045 washerFluidLevel_FBCM 3 "SNA" 1 "Low" 0 "Off" ;
VAL_ 1045 hornStatus_FBCM 3 "SNA" 2 "Fault" 1 "HornOn" 0 "HornOff" ;
VAL_ 1045 stateVehicle_FBCM 7 "SNA" 4 "SelfDriveState" 3 "DriveState" 2 "AccessoryState" 1 "StandbyState" 0 "SleepState" ;
VAL_ 1045 frontTrunkStatus_FBCM 3 "SNA" 2 "Ambiguous" 1 "Open" 0 "Closed" ;
VAL_ 1045 lockRejected_FBCM 3 "SNA" 1 "LockRejected" 0 "LockNotRejected" ;
VAL_ 1045 rsdStatus_FBCM 7 "SNA" 3 "MaxAngle" 2 "MinAngle" 1 "Open" 0 "Closed" ;
VAL_ 1046 rHumidityAir_RLS 255 "SNA" 254 "Err" 253 "Vel" 252 "Nr" ;
VAL_ 1046 tHumidityAir_RLS 255 "SNA" 254 "Err" 253 "Vel" 252 "Nr" ;
VAL_ 1046 tGlassFront_RLS 255 "SNA" 254 "Err" 253 "Vel" 252 "Nr" ;
VAL_ 1046 tDewpointAir_RLS 255 "SNA" 254 "Err" 253 "Vel" 252 "Nr" ;
VAL_ 1046 pSolarRight_RLS 255 "SNA" 254 "Err" 253 "Vel" 252 "Nr" ;
VAL_ 1046 pSolarLeft_RLS 255 "SNA" 254 "Err" 253 "Vel" 252 "Nr" ;
VAL_ 1056 liftgateOpenStatus_RBCM 3 "SNA" 1 "True" 0 "False" ;
VAL_ 1056 lightDomeStatus_RBCM 3 "SNA" 2 "LightFault" 1 "LightOn" 0 "LightOff" ;
VAL_ 1056 liftgateStatus_RBCM 7 "SNA" 4 "HardwareFault" 3 "LiftgateStopClosing" 2 "LiftgateStopOpening" 1 "LiftgateClose" 0 "LiftgateOpen" ;
VAL_ 1056 lightCHMSLStatus_RBCM 3 "SNA" 2 "LightFault" 1 "LightOn" 0 "LightOff" ;
VAL_ 1056 lightStopTrailerStatus_RBCM 3 "SNA" 2 "LightFault" 1 "LightOn" 0 "LightOff" ;
VAL_ 1056 lightTailTrailerStatus_RBCM 3 "SNA" 2 "LightFault" 1 "LightOn" 0 "LightOff" ;
VAL_ 1056 lightHazardStatus_RBCM 3 "SNA" 2 "LightFault" 1 "LightOn" 0 "LightOff" ;
VAL_ 1056 lightTailLeftStatus_RBCM 3 "SNA" 2 "LightFault" 1 "LightOn" 0 "LightOff" ;
VAL_ 1056 lightTailRightStatus_RBCM 3 "SNA" 2 "LightFault" 1 "LightOn" 0 "LightOff" ;
VAL_ 1056 lightTurnRightStatus_RBCM 3 "SNA" 2 "LightFault" 1 "LightOn" 0 "LightOff" ;
VAL_ 1056 lightStopLeftStatus_RBCM 3 "SNA" 2 "LightFault" 1 "LightOn" 0 "LightOff" ;
VAL_ 1056 lightTurnLeftStatus_RBCM 3 "SNA" 2 "LightFault" 1 "LightOn" 0 "LightOff" ;
VAL_ 1056 lightStopRightStatus_RBCM 3 "SNA" 2 "LightFault" 1 "LightOn" 0 "LightOff" ;
VAL_ 1056 lightFogRearLeftStatus_RBCM 3 "SNA" 2 "LightFault" 1 "LightOn" 0 "LightOff" ;
VAL_ 1056 lightReverseStatus_RBCM 3 "SNA" 2 "LightFault" 1 "LightOn" 0 "LightOff" ;
VAL_ 1056 lightFogRearRightStatus_RBCM 3 "SNA" 2 "LightFault" 1 "LightOn" 0 "LightOff" ;
